VERSION ""

NS_ :

BS_:

BU_: Turbocharger OnBoardDataLogger OffBoardDiagnosticTool2 OffBoardDiagnosticTool1 FileServer ParkingBrakeController SeatControl2 FanDriveController SteeringColumnUnit CommunicationUnitRadio CommunicationUnitSatellite CommunicationUnitCellular PropulsionBatteryCharger ChassisController2 ChassisController1 EngineValveControl AuxiliaryHeater2 AuxiliaryHeater1 ClutchUnit RampControl InformationSystem1 SuspensionSystemController2 OilSensor VehicleDynamicStability ExhaustEmissionController TransmissionDisplay2 TransmissionDisplay1 ClimateControl2 WaterPumpController RearAxleSteeringController LightingOperatorControl SeatController1 IgnitionController2 IgnitionController1 TirePressureController CabController2 CabController1 PneumaticSystemController SuspensionSystemController1 HydraulicPumpController EnduranceBrakingSystem RetarderExhaustEngine2 OnBoardDiagnosticUnit HeadwayController RetarderExhaustEngine1 CabDisplay1 ManagementComputer VirtualTerminal OffVehicleGateway PowerTakeOffFront HitchControl AuxiliaryValveControl BodyController TractorTrailerBridge1 StarterSystem ElectricalSystem VehicleSecurity VehicleNavigation AerodynamicControl ElectricalChargingSystem ClimateControl1 TripRecorder InstrumentCluster SuspensionDriveAxle2 SuspensionDriveAxle1 SuspensionSteerAxle SteeringController FuelSystem CruiseControl RetarderDriveline RetarderEngine BrakesDriveAxle2 BrakesDriveAxle1 BrakesSystemController BrakesSteerAxle AxleDrive2 AxleDrive1 AxleSteering PowerTakeOff ShiftConsoleSecondary ShiftConsolePrimary Transmission2 Transmission1 Engine2 Engine1

BO_ 2348941054 TC1: 8 Vector__XXX
 SG_ TrnsShftSlctorDisplayModeSwitch : 54|2@1+ (1,0) [0|3] "" Vector__XXX
 SG_ TransMode4 : 46|2@1+ (1,0) [0|3] "" Vector__XXX
 SG_ TransMode3 : 44|2@1+ (1,0) [0|3] "" Vector__XXX
 SG_ TransMode2 : 42|2@1+ (1,0) [0|3] "" Vector__XXX
 SG_ TransMode1 : 40|2@1+ (1,0) [0|3] "" Vector__XXX
 SG_ DisengageDiffLockRqCentralRear : 36|2@1+ (1,0) [0|3] "" Vector__XXX
 SG_ DisengageDiffLockRqCentralFront : 34|2@1+ (1,0) [0|3] "" Vector__XXX
 SG_ DisengageDiffLockRqCentral : 32|2@1+ (1,0) [0|3] "" Vector__XXX
 SG_ DisengageDiffLockRqRearAxle2 : 30|2@1+ (1,0) [0|3] "" Vector__XXX
 SG_ DisengageDiffLockRqRearAxle1 : 28|2@1+ (1,0) [0|3] "" Vector__XXX
 SG_ DisengageDiffLockRqFrontAxle2 : 26|2@1+ (1,0) [0|3] "" Vector__XXX
 SG_ DisengageDiffLockRqFrontAxle1 : 24|2@1+ (1,0) [0|3] "" Vector__XXX
 SG_ TransRqedGear : 16|8@1+ (1,-125) [-125|125] "" Vector__XXX
 SG_ RqedPercentClutchSlip : 8|8@1+ (0.4,0) [0|100] "%" Vector__XXX
 SG_ DisengageDrivelineRq : 4|2@1+ (1,0) [0|3] "" Vector__XXX
 SG_ TransGearShiftInhibitRq : 0|2@1+ (1,0) [0|3] "" Vector__XXX
 SG_ TrnsTrqConverterLockupDisableRq : 2|2@1+ (1,0) [0|3] "" Vector__XXX
 SG_ TransRqedLaunchGear : 50|4@1+ (1,0) [0|15] "" Vector__XXX
 SG_ TransReverseGearShiftInhibitRq : 6|2@1+ (1,0) [0|3] "" Vector__XXX
 SG_ TransMode8 : 62|2@1+ (1,0) [0|3] "" Vector__XXX
 SG_ TransMode7 : 60|2@1+ (1,0) [0|3] "" Vector__XXX
 SG_ TransMode6 : 58|2@1+ (1,0) [0|3] "" Vector__XXX
 SG_ TransMode5 : 56|2@1+ (1,0) [0|3] "" Vector__XXX

BO_ 2566839806 TC: 8 Vector__XXX
 SG_ EngTurboOilLevelSwitch : 30|2@1+ (1,0) [0|3] "" Vector__XXX
 SG_ EngTurbo1Speed : 8|16@1+ (4,0) [0|257020] "rpm" Vector__XXX
 SG_ EngTurboLubeOilPress1 : 0|8@1+ (4,0) [0|1000] "kPa" Vector__XXX

BO_ 2633911806 TAVG: 8 Vector__XXX
 SG_ EngTotalAverageFuelEconomy : 16|16@1+ (0.001953125,0) [0|125.5] "km/L" Vector__XXX
 SG_ EngTotalAverageFuelRate : 0|16@1+ (0.05,0) [0|3212.75] "L/h" Vector__XXX

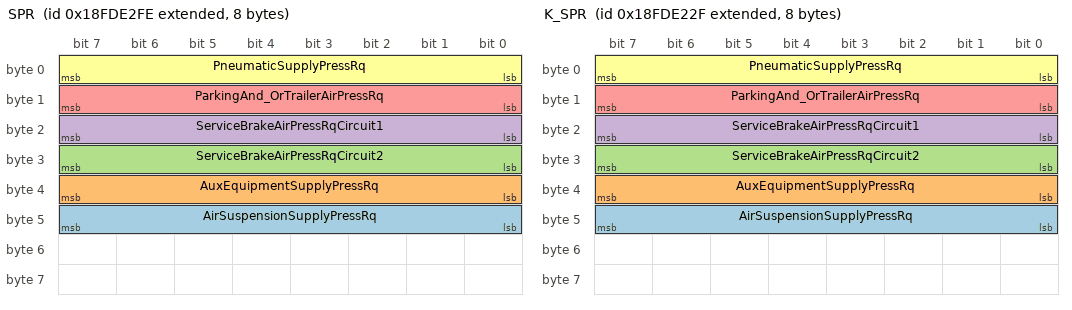
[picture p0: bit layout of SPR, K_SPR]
BO_ 2566775550 SPR: 8 Vector__XXX
 SG_ AirSuspensionSupplyPressRq : 40|8@1+ (8,0) [0|2000] "kPa" Vector__XXX
 SG_ AuxEquipmentSupplyPressRq : 32|8@1+ (8,0) [0|2000] "kPa" Vector__XXX
 SG_ ServiceBrakeAirPressRqCircuit2 : 24|8@1+ (8,0) [0|2000] "kPa" Vector__XXX
 SG_ ServiceBrakeAirPressRqCircuit1 : 16|8@1+ (8,0) [0|2000] "kPa" Vector__XXX
 SG_ ParkingAnd_OrTrailerAirPressRq : 8|8@1+ (8,0) [0|2000] "kPa" Vector__XXX
 SG_ PneumaticSupplyPressRq : 0|8@1+ (8,0) [0|2000] "kPa" Vector__XXX

BO_ 2566775343 K_SPR: 8 Vector__XXX
 SG_ AirSuspensionSupplyPressRq : 40|8@1+ (8,0) [0|2000] "kPa" Vector__XXX
 SG_ AuxEquipmentSupplyPressRq : 32|8@1+ (8,0) [0|2000] "kPa" Vector__XXX
 SG_ ServiceBrakeAirPressRqCircuit2 : 24|8@1+ (8,0) [0|2000] "kPa" Vector__XXX
 SG_ ServiceBrakeAirPressRqCircuit1 : 16|8@1+ (8,0) [0|2000] "kPa" Vector__XXX
 SG_ ParkingAnd_OrTrailerAirPressRq : 8|8@1+ (8,0) [0|2000] "kPa" Vector__XXX
 SG_ PneumaticSupplyPressRq : 0|8@1+ (8,0) [0|2000] "kPa" Vector__XXX

BO_ 2566819838 SP2: 8 Vector__XXX
 SG_ EngExtlShutdownAirSupplyPress : 0|16@1+ (0.5,0) [0|32127.5] "kPa" Vector__XXX

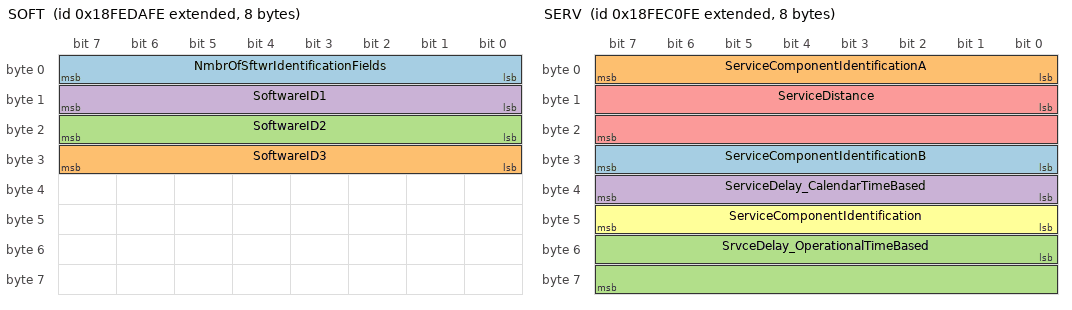
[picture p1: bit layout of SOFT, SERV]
BO_ 2566839038 SOFT: 8 Vector__XXX
 SG_ NmbrOfSftwrIdentificationFields : 0|8@1+ (1,0) [0|250] "steps" Vector__XXX
 SG_ SoftwareID3 : 24|8@1+ (1,0) [0|255] "" Vector__XXX
 SG_ SoftwareID2 : 16|8@1+ (1,0) [0|255] "" Vector__XXX
 SG_ SoftwareID1 : 8|8@1+ (1,0) [0|255] "" Vector__XXX

BO_ 2566841598 SHUTDN: 8 Vector__XXX
 SG_ EngOverspeedTest : 54|2@1+ (1,0) [0|3] "" Vector__XXX
 SG_ EngAirShutoffCmdStatus : 52|2@1+ (1,0) [0|3] "" Vector__XXX
 SG_ EngAlarmOutputCmdStatus : 50|2@1+ (1,0) [0|3] "" Vector__XXX
 SG_ EngAlarmAcknowledge : 48|2@1+ (1,0) [0|3] "" Vector__XXX
 SG_ EngProtectionSystemConfig : 46|2@1+ (1,0) [0|3] "" Vector__XXX
 SG_ EngProtectionSystemTimerState : 38|2@1+ (1,0) [0|3] "" Vector__XXX
 SG_ EngPrtectionSystemTimerOverride : 36|2@1+ (1,0) [0|3] "" Vector__XXX
 SG_ EngPrtctnSystmApprchingShutdown : 34|2@1+ (1,0) [0|3] "" Vector__XXX
 SG_ EngWaitToStartLamp : 24|2@1+ (1,0) [0|3] "" Vector__XXX
 SG_ RefrigerantHighPressSwitch : 20|2@1+ (1,0) [0|3] "" Vector__XXX
 SG_ RefrigerantLowPressSwitch : 18|2@1+ (1,0) [0|3] "" Vector__XXX
 SG_ A_CHighPressFanSwitch : 16|2@1+ (1,0) [0|3] "" Vector__XXX
 SG_ EngIdleShutdownTimerFunction : 14|2@1+ (1,0) [0|3] "" Vector__XXX
 SG_ EngIdleShutdownTimerState : 6|2@1+ (1,0) [0|3] "" Vector__XXX
 SG_ EngIdleShutdownTimerOverride : 4|2@1+ (1,0) [0|3] "" Vector__XXX
 SG_ EngIdleShutdownDriverAlertMode : 2|2@1+ (1,0) [0|3] "" Vector__XXX
 SG_ PTOShutdownHasShutdownEng : 58|2@1+ (1,0) [0|3] "" Vector__XXX
 SG_ EngPrtctnSystmHasShutdownEngine : 32|2@1+ (1,0) [0|3] "" Vector__XXX
 SG_ EngIdlShutdownHasShutdownEngine : 0|2@1+ (1,0) [0|3] "" Vector__XXX
 SG_ EngAirShutoffStatus : 56|2@1+ (1,0) [0|3] "" Vector__XXX

BO_ 2566832382 SERV: 8 Vector__XXX
 SG_ ServiceComponentIdentificationB : 24|8@1+ (1,0) [0|250] "ID" Vector__XXX
 SG_ ServiceComponentIdentificationA : 0|8@1+ (1,0) [0|250] "ID" Vector__XXX
 SG_ SrvceDelay_OperationalTimeBased : 48|16@1+ (1,-32127) [-32127|32128] "hr" Vector__XXX
 SG_ ServiceDelay_CalendarTimeBased : 32|8@1+ (1,-125) [-125|125] "weeks" Vector__XXX
 SG_ ServiceDistance : 8|16@1+ (5,-160635) [-160635|160640] "km" Vector__XXX
 SG_ ServiceComponentIdentification : 40|8@1+ (1,0) [0|250] "ID" Vector__XXX

BO_ 2633928446 S2: 8 Vector__XXX
 SG_ TimeSinceLastService : 8|16@1+ (1,-32127) [-32127|32128] "hr" Vector__XXX
 SG_ ServiceComponentIdentification : 0|8@1+ (1,0) [0|250] "ID" Vector__XXX

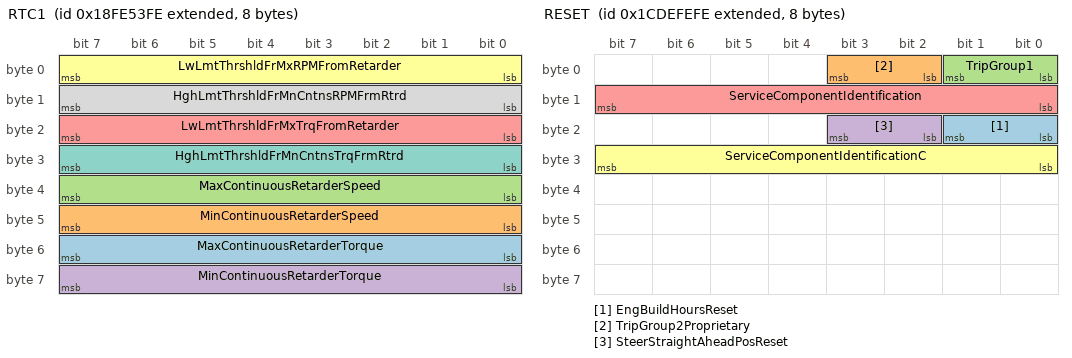
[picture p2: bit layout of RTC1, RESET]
BO_ 2566804478 RTC1: 8 Vector__XXX
 SG_ MaxContinuousRetarderTorque : 48|8@1+ (1,-125) [-125|125] "%" Vector__XXX
 SG_ MinContinuousRetarderSpeed : 40|8@1+ (32,0) [0|8000] "rpm" Vector__XXX
 SG_ MaxContinuousRetarderSpeed : 32|8@1+ (32,0) [0|8000] "rpm" Vector__XXX
 SG_ MinContinuousRetarderTorque : 56|8@1+ (1,-125) [-125|125] "%" Vector__XXX
 SG_ LwLmtThrshldFrMxTrqFromRetarder : 16|8@1+ (1,-125) [-125|125] "%" Vector__XXX
 SG_ LwLmtThrshldFrMxRPMFromRetarder : 0|8@1+ (32,0) [0|8000] "rpm" Vector__XXX
 SG_ HghLmtThrshldFrMnCntnsTrqFrmRtrd : 24|8@1+ (1,-125) [-125|125] "%" Vector__XXX
 SG_ HghLmtThrshldFrMnCntnsRPMFrmRtrd : 8|8@1+ (32,0) [0|8000] "rpm" Vector__XXX

BO_ 2566847486 RF: 8 Vector__XXX
 SG_ DrvlneRetarderOverheatIndicator : 16|2@1+ (1,0) [0|3] "" Vector__XXX
 SG_ HydRetarderOilTemp : 8|8@1+ (1,-40) [-40|210] "deg C" Vector__XXX
 SG_ HydRetarderPress : 0|8@1+ (16,0) [0|4000] "kPa" Vector__XXX

BO_ 2566847248 K_RF: 8 Vector__XXX
 SG_ DrvlneRetarderOverheatIndicator : 16|2@1+ (1,0) [0|3] "" Vector__XXX
 SG_ HydRetarderOilTemp : 8|8@1+ (1,-40) [-40|210] "deg C" Vector__XXX
 SG_ HydRetarderPress : 0|8@1+ (16,0) [0|4000] "kPa" Vector__XXX

BO_ 2631859966 RESET: 8 Vector__XXX
 SG_ EngBuildHoursReset : 16|2@1+ (1,0) [0|3] "" Vector__XXX
 SG_ TripGroup2Proprietary : 2|2@1+ (1,0) [0|3] "" Vector__XXX
 SG_ TripGroup1 : 0|2@1+ (1,0) [0|3] "" Vector__XXX
 SG_ SteerStraightAheadPosReset : 18|2@1+ (1,0) [0|3] "" Vector__XXX
 SG_ ServiceComponentIdentification : 8|8@1+ (1,0) [0|250] "ID" Vector__XXX
 SG_ ServiceComponentIdentificationC : 24|8@1+ (1,0) [0|250] "ID" Vector__XXX

BO_ 2566840830 RC: 19 Vector__XXX
 SG_ PercentTorqueAtPeakTorquePoint5 : 144|8@1+ (1,-125) [-125|125] "%" Vector__XXX
 SG_ ReferenceRetarderTorque : 128|16@1+ (1,0) [0|64255] "Nm" Vector__XXX
 SG_ RetarderSpeedAtPeakTorquePoint5 : 112|16@1+ (0.125,0) [0|8031.875] "rpm" Vector__XXX
 SG_ PercentTorqueAtPoint4 : 104|8@1+ (1,-125) [-125|125] "%" Vector__XXX
 SG_ RetarderSpeedAtPoint4 : 88|16@1+ (0.125,0) [0|8031.875] "rpm" Vector__XXX
 SG_ PercentTorqueAtPoint3 : 80|8@1+ (1,-125) [-125|125] "%" Vector__XXX
 SG_ RetarderSpeedAtPoint3 : 64|16@1+ (0.125,0) [0|8031.875] "rpm" Vector__XXX
 SG_ PercentTorqueAtMaxSpeedPoint2 : 56|8@1+ (1,-125) [-125|125] "%" Vector__XXX
 SG_ MaxRetarderSpeedPoint2 : 40|16@1+ (0.125,0) [0|8031.875] "rpm" Vector__XXX
 SG_ PercentTorqueAtIdlePoint1 : 32|8@1+ (1,-125) [-125|125] "%" Vector__XXX
 SG_ RetarderSpeedAtIdlePoint1 : 16|16@1+ (0.125,0) [0|8031.875] "rpm" Vector__XXX
 SG_ RetarderCtrlMethod : 8|8@1+ (1,0) [0|250] "steps" Vector__XXX
 SG_ RetarderLocation : 4|4@1+ (1,0) [0|15] "" Vector__XXX
 SG_ RetarderType : 0|4@1+ (1,0) [0|15] "" Vector__XXX

BO_ 2633930238 RBI: 8 Vector__XXX
 SG_ EngOperationTimeSinceRebuild : 0|32@1+ (1,0) [0|4211081215] "s" Vector__XXX

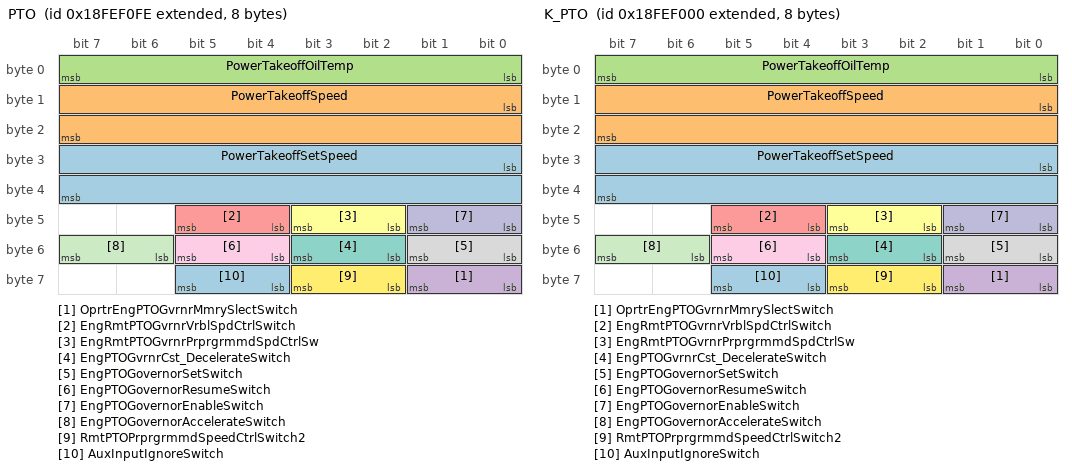
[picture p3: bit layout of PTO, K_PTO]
BO_ 2566844670 PTO: 8 Vector__XXX
 SG_ PowerTakeoffSetSpeed : 24|16@1+ (0.125,0) [0|8031.875] "rpm" Vector__XXX
 SG_ PowerTakeoffSpeed : 8|16@1+ (0.125,0) [0|8031.875] "rpm" Vector__XXX
 SG_ PowerTakeoffOilTemp : 0|8@1+ (1,-40) [-40|210] "deg C" Vector__XXX
 SG_ OprtrEngPTOGvrnrMmrySlectSwitch : 56|2@1+ (1,0) [0|3] "" Vector__XXX
 SG_ EngRmtPTOGvrnrVrblSpdCtrlSwitch : 44|2@1+ (1,0) [0|3] "" Vector__XXX
 SG_ EngRmtPTOGvrnrPrprgrmmdSpdCtrlSw : 42|2@1+ (1,0) [0|3] "" Vector__XXX
 SG_ EngPTOGvrnrCst_DecelerateSwitch : 50|2@1+ (1,0) [0|3] "" Vector__XXX
 SG_ EngPTOGovernorSetSwitch : 48|2@1+ (1,0) [0|3] "" Vector__XXX
 SG_ EngPTOGovernorResumeSwitch : 52|2@1+ (1,0) [0|3] "" Vector__XXX
 SG_ EngPTOGovernorEnableSwitch : 40|2@1+ (1,0) [0|3] "" Vector__XXX
 SG_ EngPTOGovernorAccelerateSwitch : 54|2@1+ (1,0) [0|3] "" Vector__XXX
 SG_ RmtPTOPrprgrmmdSpeedCtrlSwitch2 : 58|2@1+ (1,0) [0|3] "" Vector__XXX
 SG_ AuxInputIgnoreSwitch : 60|2@1+ (1,0) [0|3] "" Vector__XXX

BO_ 2566844416 K_PTO: 8 Vector__XXX
 SG_ PowerTakeoffSetSpeed : 24|16@1+ (0.125,0) [0|8031.875] "rpm" Vector__XXX
 SG_ PowerTakeoffSpeed : 8|16@1+ (0.125,0) [0|8031.875] "rpm" Vector__XXX
 SG_ PowerTakeoffOilTemp : 0|8@1+ (1,-40) [-40|210] "deg C" Vector__XXX
 SG_ OprtrEngPTOGvrnrMmrySlectSwitch : 56|2@1+ (1,0) [0|3] "" Vector__XXX
 SG_ EngRmtPTOGvrnrVrblSpdCtrlSwitch : 44|2@1+ (1,0) [0|3] "" Vector__XXX
 SG_ EngRmtPTOGvrnrPrprgrmmdSpdCtrlSw : 42|2@1+ (1,0) [0|3] "" Vector__XXX
 SG_ EngPTOGvrnrCst_DecelerateSwitch : 50|2@1+ (1,0) [0|3] "" Vector__XXX
 SG_ EngPTOGovernorSetSwitch : 48|2@1+ (1,0) [0|3] "" Vector__XXX
 SG_ EngPTOGovernorResumeSwitch : 52|2@1+ (1,0) [0|3] "" Vector__XXX
 SG_ EngPTOGovernorEnableSwitch : 40|2@1+ (1,0) [0|3] "" Vector__XXX
 SG_ EngPTOGovernorAccelerateSwitch : 54|2@1+ (1,0) [0|3] "" Vector__XXX
 SG_ RmtPTOPrprgrmmdSpeedCtrlSwitch2 : 58|2@1+ (1,0) [0|3] "" Vector__XXX
 SG_ AuxInputIgnoreSwitch : 60|2@1+ (1,0) [0|3] "" Vector__XXX

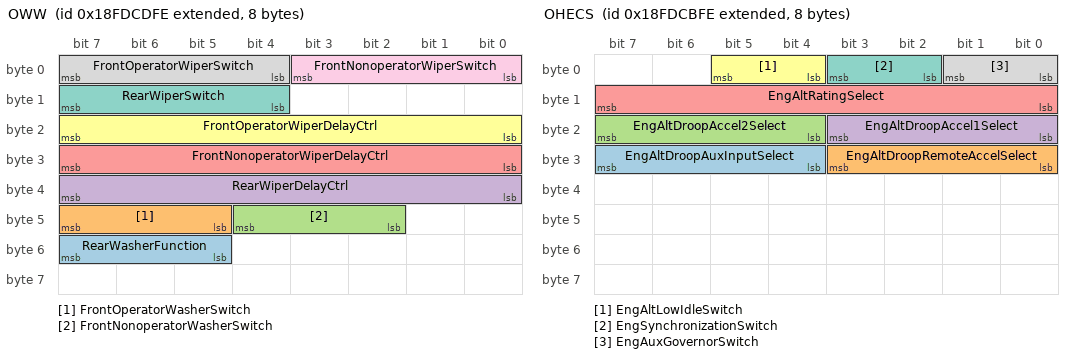
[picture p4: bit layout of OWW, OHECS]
BO_ 2566770174 OWW: 8 Vector__XXX
 SG_ RearWasherFunction : 53|3@1+ (1,0) [0|7] "" Vector__XXX
 SG_ FrontOperatorWasherSwitch : 45|3@1+ (1,0) [0|7] "" Vector__XXX
 SG_ FrontNonoperatorWasherSwitch : 42|3@1+ (1,0) [0|7] "" Vector__XXX
 SG_ RearWiperDelayCtrl : 32|8@1+ (0.4,0) [0|100] "%" Vector__XXX
 SG_ FrontNonoperatorWiperDelayCtrl : 24|8@1+ (0.4,0) [0|100] "%" Vector__XXX
 SG_ FrontOperatorWiperDelayCtrl : 16|8@1+ (0.4,0) [0|100] "%" Vector__XXX
 SG_ RearWiperSwitch : 12|4@1+ (1,0) [0|15] "" Vector__XXX
 SG_ FrontOperatorWiperSwitch : 4|4@1+ (1,0) [0|15] "" Vector__XXX
 SG_ FrontNonoperatorWiperSwitch : 0|4@1+ (1,0) [0|15] "" Vector__XXX

BO_ 2566769662 OHECS: 8 Vector__XXX
 SG_ EngAltDroopAuxInputSelect : 28|4@1+ (1,0) [0|15] "" Vector__XXX
 SG_ EngAltDroopRemoteAccelSelect : 24|4@1+ (1,0) [0|15] "" Vector__XXX
 SG_ EngAltDroopAccel2Select : 20|4@1+ (1,0) [0|15] "" Vector__XXX
 SG_ EngAltDroopAccel1Select : 16|4@1+ (1,0) [0|15] "" Vector__XXX
 SG_ EngAltRatingSelect : 8|8@1+ (1,0) [0|255] "" Vector__XXX
 SG_ EngAltLowIdleSwitch : 4|2@1+ (1,0) [0|3] "" Vector__XXX
 SG_ EngSynchronizationSwitch : 2|2@1+ (1,0) [0|3] "" Vector__XXX
 SG_ EngAuxGovernorSwitch : 0|2@1+ (1,0) [0|3] "" Vector__XXX

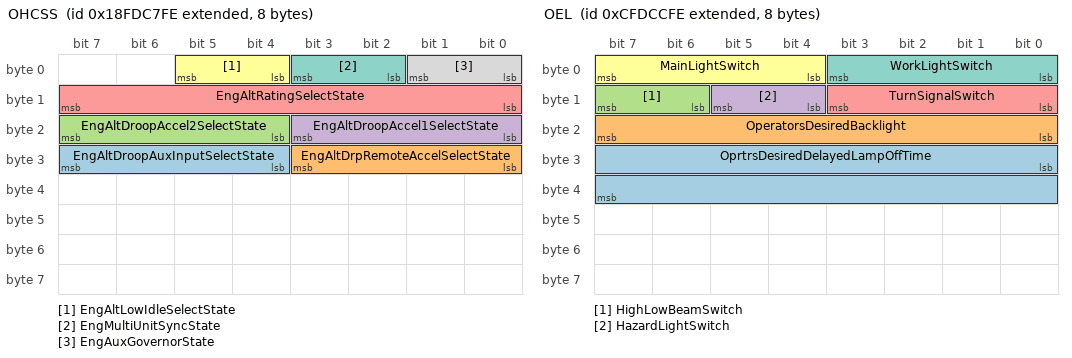
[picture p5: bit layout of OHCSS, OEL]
BO_ 2566768638 OHCSS: 8 Vector__XXX
 SG_ EngAltDroopAuxInputSelectState : 28|4@1+ (1,0) [0|15] "" Vector__XXX
 SG_ EngAltDrpRemoteAccelSelectState : 24|4@1+ (1,0) [0|15] "" Vector__XXX
 SG_ EngAltDroopAccel2SelectState : 20|4@1+ (1,0) [0|15] "" Vector__XXX
 SG_ EngAltDroopAccel1SelectState : 16|4@1+ (1,0) [0|15] "" Vector__XXX
 SG_ EngAltRatingSelectState : 8|8@1+ (1,0) [0|255] "" Vector__XXX
 SG_ EngAltLowIdleSelectState : 4|2@1+ (1,0) [0|3] "" Vector__XXX
 SG_ EngMultiUnitSyncState : 2|2@1+ (1,0) [0|3] "" Vector__XXX
 SG_ EngAuxGovernorState : 0|2@1+ (1,0) [0|3] "" Vector__XXX

BO_ 2365443326 OEL: 8 Vector__XXX
 SG_ OprtrsDesiredDelayedLampOffTime : 24|16@1+ (1,0) [0|64255] "s" Vector__XXX
 SG_ OperatorsDesiredBacklight : 16|8@1+ (0.4,0) [0|100] "%" Vector__XXX
 SG_ HighLowBeamSwitch : 14|2@1+ (1,0) [0|3] "" Vector__XXX
 SG_ HazardLightSwitch : 12|2@1+ (1,0) [0|3] "" Vector__XXX
 SG_ TurnSignalSwitch : 8|4@1+ (1,0) [0|15] "" Vector__XXX
 SG_ MainLightSwitch : 4|4@1+ (1,0) [0|15] "" Vector__XXX
 SG_ WorkLightSwitch : 0|4@1+ (1,0) [0|15] "" Vector__XXX

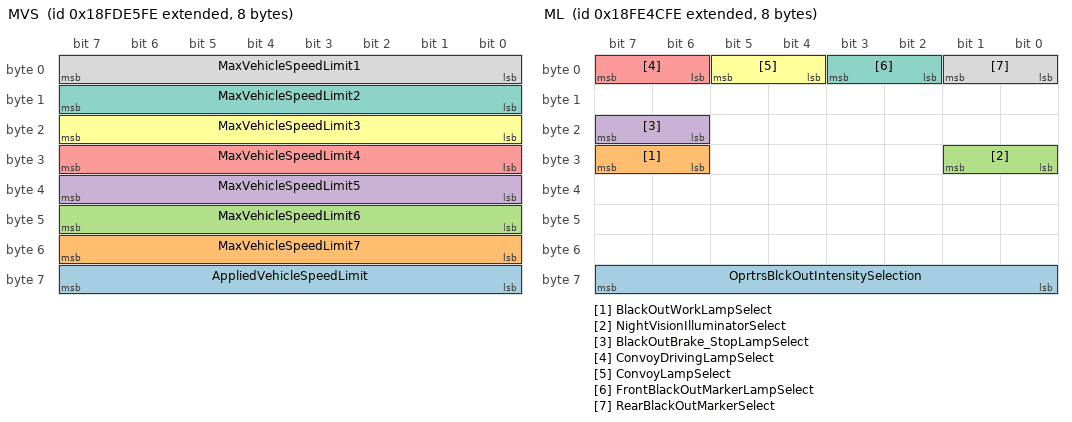
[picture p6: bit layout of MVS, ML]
BO_ 2566776318 MVS: 8 Vector__XXX
 SG_ AppliedVehicleSpeedLimit : 56|8@1+ (1,0) [0|250] "km/h" Vector__XXX
 SG_ MaxVehicleSpeedLimit7 : 48|8@1+ (1,0) [0|250] "km/h" Vector__XXX
 SG_ MaxVehicleSpeedLimit6 : 40|8@1+ (1,0) [0|250] "km/h" Vector__XXX
 SG_ MaxVehicleSpeedLimit5 : 32|8@1+ (1,0) [0|250] "km/h" Vector__XXX
 SG_ MaxVehicleSpeedLimit4 : 24|8@1+ (1,0) [0|250] "km/h" Vector__XXX
 SG_ MaxVehicleSpeedLimit3 : 16|8@1+ (1,0) [0|250] "km/h" Vector__XXX
 SG_ MaxVehicleSpeedLimit2 : 8|8@1+ (1,0) [0|250] "km/h" Vector__XXX
 SG_ MaxVehicleSpeedLimit1 : 0|8@1+ (1,0) [0|250] "km/h" Vector__XXX

BO_ 2566802686 ML: 8 Vector__XXX
 SG_ OprtrsBlckOutIntensitySelection : 56|8@1+ (0.4,0) [0|100] "%" Vector__XXX
 SG_ BlackOutWorkLampSelect : 30|2@1+ (1,0) [0|3] "" Vector__XXX
 SG_ NightVisionIlluminatorSelect : 24|2@1+ (1,0) [0|3] "" Vector__XXX
 SG_ BlackOutBrake_StopLampSelect : 22|2@1+ (1,0) [0|3] "" Vector__XXX
 SG_ ConvoyDrivingLampSelect : 6|2@1+ (1,0) [0|3] "" Vector__XXX
 SG_ ConvoyLampSelect : 4|2@1+ (1,0) [0|3] "" Vector__XXX
 SG_ FrontBlackOutMarkerLampSelect : 2|2@1+ (1,0) [0|3] "" Vector__XXX
 SG_ RearBlackOutMarkerSelect : 0|2@1+ (1,0) [0|3] "" Vector__XXX

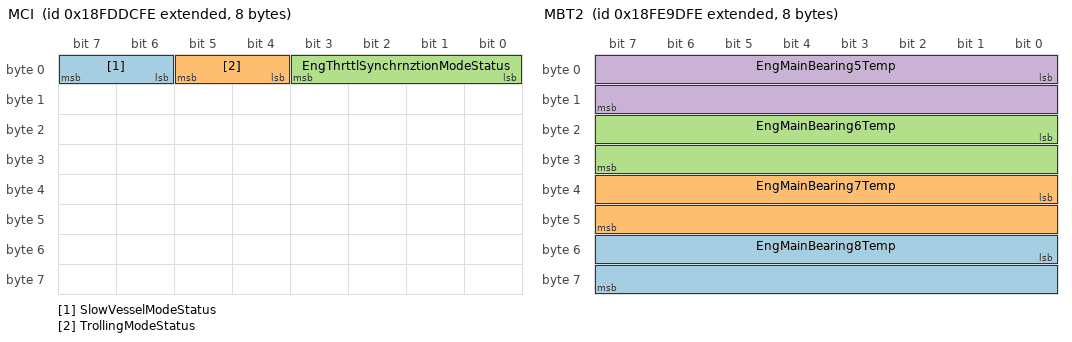
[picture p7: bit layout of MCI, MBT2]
BO_ 2566774014 MCI: 8 Vector__XXX
 SG_ SlowVesselModeStatus : 6|2@1+ (1,0) [0|3] "" Vector__XXX
 SG_ TrollingModeStatus : 4|2@1+ (1,0) [0|3] "" Vector__XXX
 SG_ EngThrttlSynchrnztionModeStatus : 0|4@1+ (1,0) [0|15] "" Vector__XXX

BO_ 2566823166 MBT3: 8 Vector__XXX
 SG_ EngMainBearing11Temp : 32|16@1+ (0.03125,-273) [-273|1734.96875] "deg C" Vector__XXX
 SG_ EngMainBearing10Temp : 16|16@1+ (0.03125,-273) [-273|1734.96875] "deg C" Vector__XXX
 SG_ EngMainBearing9Temp : 0|16@1+ (0.03125,-273) [-273|1734.96875] "deg C" Vector__XXX

BO_ 2566823422 MBT2: 8 Vector__XXX
 SG_ EngMainBearing8Temp : 48|16@1+ (0.03125,-273) [-273|1734.96875] "deg C" Vector__XXX
 SG_ EngMainBearing7Temp : 32|16@1+ (0.03125,-273) [-273|1734.96875] "deg C" Vector__XXX
 SG_ EngMainBearing6Temp : 16|16@1+ (0.03125,-273) [-273|1734.96875] "deg C" Vector__XXX
 SG_ EngMainBearing5Temp : 0|16@1+ (0.03125,-273) [-273|1734.96875] "deg C" Vector__XXX

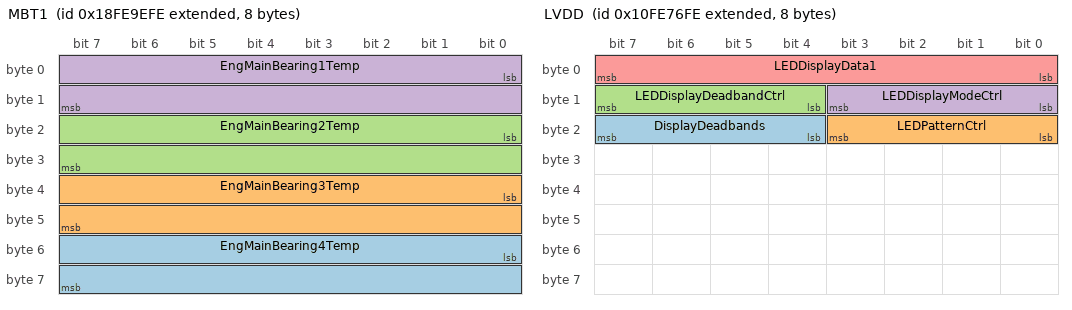
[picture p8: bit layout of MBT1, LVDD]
BO_ 2566823678 MBT1: 8 Vector__XXX
 SG_ EngMainBearing4Temp : 48|16@1+ (0.03125,-273) [-273|1734.96875] "deg C" Vector__XXX
 SG_ EngMainBearing3Temp : 32|16@1+ (0.03125,-273) [-273|1734.96875] "deg C" Vector__XXX
 SG_ EngMainBearing2Temp : 16|16@1+ (0.03125,-273) [-273|1734.96875] "deg C" Vector__XXX
 SG_ EngMainBearing1Temp : 0|16@1+ (0.03125,-273) [-273|1734.96875] "deg C" Vector__XXX

BO_ 2432595710 LVDD: 8 Vector__XXX
 SG_ DisplayDeadbands : 20|4@1+ (1,0) [0|15] "" Vector__XXX
 SG_ LEDPatternCtrl : 16|4@1+ (1,0) [0|15] "" Vector__XXX
 SG_ LEDDisplayDeadbandCtrl : 12|4@1+ (1,0) [0|15] "" Vector__XXX
 SG_ LEDDisplayModeCtrl : 8|4@1+ (1,0) [0|15] "" Vector__XXX
 SG_ LEDDisplayData1 : 0|8@1+ (1,0) [0|255] "" Vector__XXX

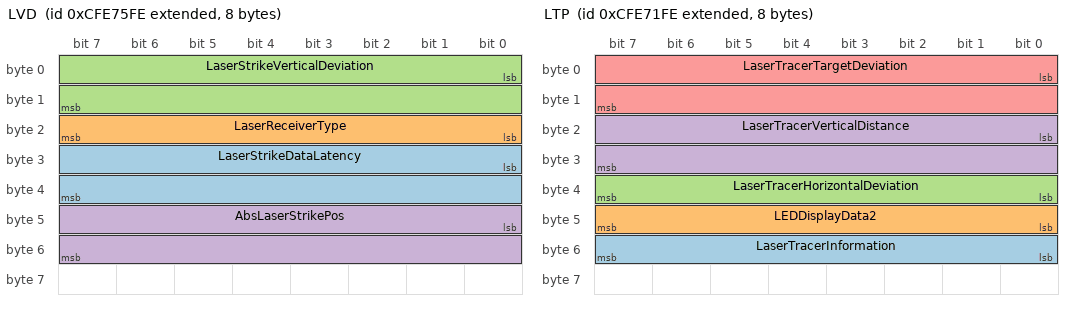
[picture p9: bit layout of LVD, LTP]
BO_ 2365486590 LVD: 8 Vector__XXX
 SG_ LaserStrikeDataLatency : 24|16@1+ (51.2,0) [0|3.289856] "s" Vector__XXX
 SG_ LaserReceiverType : 16|8@1+ (1,0) [0|250] "" Vector__XXX
 SG_ LaserStrikeVerticalDeviation : 0|16@1+ (0.1,-3200) [-3200|3225.5] "mm" Vector__XXX
 SG_ AbsLaserStrikePos : 40|16@1+ (0.1,0) [0|6425.5] "mm" Vector__XXX

BO_ 2365485566 LTP: 8 Vector__XXX
 SG_ LaserTracerInformation : 48|8@1+ (1,0) [0|255] "" Vector__XXX
 SG_ LEDDisplayData2 : 40|8@1+ (1,0) [0|255] "" Vector__XXX
 SG_ LaserTracerHorizontalDeviation : 32|8@1+ (1,0) [0|250] "%" Vector__XXX
 SG_ LaserTracerVerticalDistance : 16|16@1+ (0.1,0) [0|6425.5] "mm" Vector__XXX
 SG_ LaserTracerTargetDeviation : 0|16@1+ (0.1,-3200) [-3200|3225.5] "mm" Vector__XXX

BO_ 2633939454 LTFI: 22 Vector__XXX
 SG_ TripCruiseFuelUsed : 128|32@1+ (0.5,0) [0|2105540607.5] "L" Vector__XXX
 SG_ TripVehicleIdleFuelUsed : 96|32@1+ (0.5,0) [0|2105540607.5] "L" Vector__XXX
 SG_ TripDriveFuelUsed : 0|32@1+ (0.5,0) [0|2105540607.5] "L" Vector__XXX
 SG_ TrpPTOGovernorNonmovingFuelUsed : 64|32@1+ (0.5,0) [0|2105540607.5] "L" Vector__XXX
 SG_ TripPTOGovernorMovingFuelUsed : 32|32@1+ (0.5,0) [0|2105540607.5] "L" Vector__XXX
 SG_ TripDriveFuelEconomy : 160|16@1+ (0.001953125,0) [0|125.5] "km/L" Vector__XXX

BO_ 2365486334 LSP: 8 Vector__XXX
 SG_ BldHeightSetPointHighResolution : 16|32@1+ (100,-209.7152) [-209.7152|211.3929215] "m" Vector__XXX
 SG_ ModifyLevelingSystemSetPoint : 0|16@1+ (0.1,-3200) [-3200|3225.5] "mm" Vector__XXX

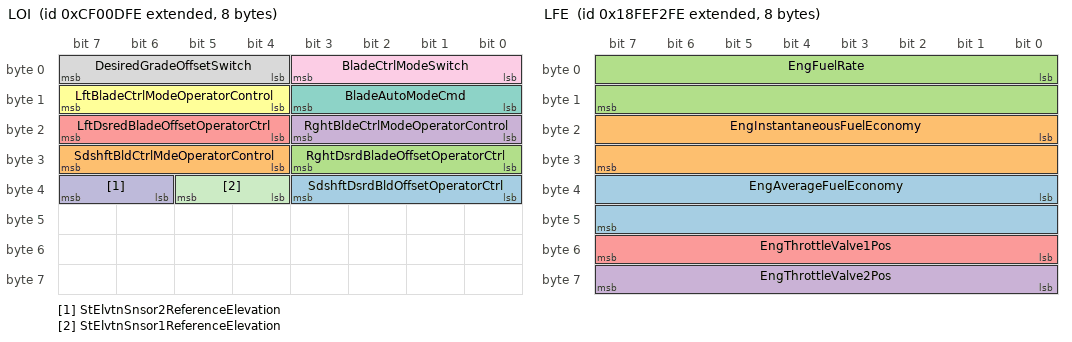
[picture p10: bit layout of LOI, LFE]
BO_ 2364542462 LOI: 8 Vector__XXX
 SG_ SdshftDsrdBldOffsetOperatorCtrl : 32|4@1+ (1,0) [0|15] "" Vector__XXX
 SG_ SdshftBldCtrlMdeOperatorControl : 28|4@1+ (1,0) [0|15] "" Vector__XXX
 SG_ RghtDsrdBladeOffsetOperatorCtrl : 24|4@1+ (1,0) [0|15] "" Vector__XXX
 SG_ RghtBldeCtrlModeOperatorControl : 16|4@1+ (1,0) [0|15] "" Vector__XXX
 SG_ LftDsredBladeOffsetOperatorCtrl : 20|4@1+ (1,0) [0|15] "" Vector__XXX
 SG_ LftBladeCtrlModeOperatorControl : 12|4@1+ (1,0) [0|15] "" Vector__XXX
 SG_ BladeAutoModeCmd : 8|4@1+ (1,0) [0|15] "" Vector__XXX
 SG_ DesiredGradeOffsetSwitch : 4|4@1+ (1,0) [0|15] "" Vector__XXX
 SG_ BladeCtrlModeSwitch : 0|4@1+ (1,0) [0|15] "" Vector__XXX
 SG_ StElvtnSnsor2ReferenceElevation : 38|2@1+ (1,0) [0|3] "" Vector__XXX
 SG_ StElvtnSnsor1ReferenceElevation : 36|2@1+ (1,0) [0|3] "" Vector__XXX

BO_ 2365486078 LMP: 8 Vector__XXX
 SG_ MastPos : 0|16@1+ (0.1,-3200) [-3200|3225.5] "mm" Vector__XXX

BO_ 2633937918 LFI: 8 Vector__XXX
 SG_ TotalEngPTOGovernorFuelUsed : 0|32@1+ (0.5,0) [0|2105540607.5] "L" Vector__XXX
 SG_ TripAverageFuelRate : 32|16@1+ (0.05,0) [0|3212.75] "L/h" Vector__XXX
 SG_ FlexibleFuelPercentage : 48|10@1+ (0.1,0) [0|102] "%" Vector__XXX

BO_ 2566845182 LFE: 8 Vector__XXX
 SG_ EngAverageFuelEconomy : 32|16@1+ (0.001953125,0) [0|125.5] "km/L" Vector__XXX
 SG_ EngInstantaneousFuelEconomy : 16|16@1+ (0.001953125,0) [0|125.5] "km/L" Vector__XXX
 SG_ EngFuelRate : 0|16@1+ (0.05,0) [0|3212.75] "L/h" Vector__XXX
 SG_ EngThrottleValve2Pos : 56|8@1+ (0.4,0) [0|100] "%" Vector__XXX
 SG_ EngThrottleValve1Pos : 48|8@1+ (0.4,0) [0|100] "%" Vector__XXX

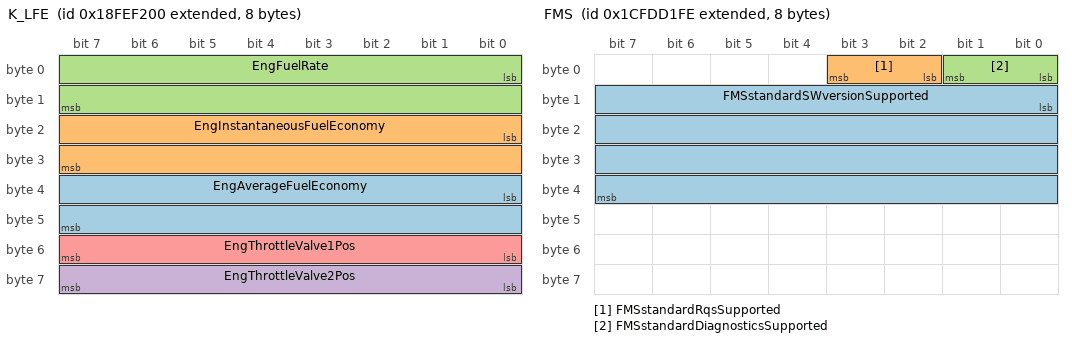
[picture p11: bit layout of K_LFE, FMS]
BO_ 2566844928 K_LFE: 8 Vector__XXX
 SG_ EngAverageFuelEconomy : 32|16@1+ (0.001953125,0) [0|125.5] "km/L" Vector__XXX
 SG_ EngInstantaneousFuelEconomy : 16|16@1+ (0.001953125,0) [0|125.5] "km/L" Vector__XXX
 SG_ EngFuelRate : 0|16@1+ (0.05,0) [0|3212.75] "L/h" Vector__XXX
 SG_ EngThrottleValve2Pos : 56|8@1+ (0.4,0) [0|100] "%" Vector__XXX
 SG_ EngThrottleValve1Pos : 48|8@1+ (0.4,0) [0|100] "%" Vector__XXX

BO_ 2566842878 LFC: 8 Vector__XXX
 SG_ EngTotalFuelUsed : 32|32@1+ (0.5,0) [0|2105540607.5] "L" Vector__XXX
 SG_ EngTripFuel : 0|32@1+ (0.5,0) [0|2105540607.5] "L" Vector__XXX

BO_ 2633883646 FWD: 8 Vector__XXX
 SG_ FrontWheelDriveActuatorStatus : 0|2@1+ (1,0) [0|3] "" Vector__XXX

BO_ 2633880062 FMS: 8 Vector__XXX
 SG_ FMSstandardSWversionSupported : 8|32@1+ (1,0) [0|255] "per" Vector__XXX
 SG_ FMSstandardRqsSupported : 2|2@1+ (1,0) [0|3] "" Vector__XXX
 SG_ FMSstandardDiagnosticsSupported : 0|2@1+ (1,0) [0|3] "" Vector__XXX

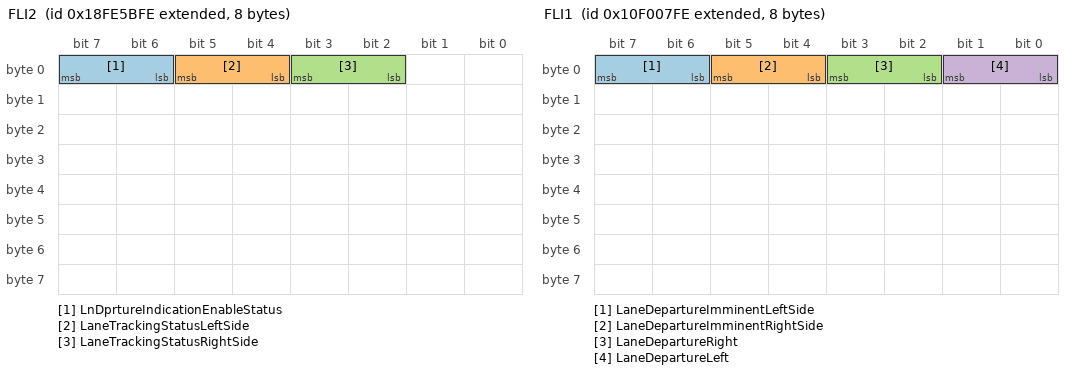
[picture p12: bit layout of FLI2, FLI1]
BO_ 2566806526 FLI2: 8 Vector__XXX
 SG_ LnDprtureIndicationEnableStatus : 6|2@1+ (1,0) [0|3] "" Vector__XXX
 SG_ LaneTrackingStatusLeftSide : 4|2@1+ (1,0) [0|3] "" Vector__XXX
 SG_ LaneTrackingStatusRightSide : 2|2@1+ (1,0) [0|3] "" Vector__XXX

BO_ 2431649790 FLI1: 8 Vector__XXX
 SG_ LaneDepartureImminentLeftSide : 6|2@1+ (1,0) [0|3] "" Vector__XXX
 SG_ LaneDepartureImminentRightSide : 4|2@1+ (1,0) [0|3] "" Vector__XXX
 SG_ LaneDepartureRight : 2|2@1+ (1,0) [0|3] "" Vector__XXX
 SG_ LaneDepartureLeft : 0|2@1+ (1,0) [0|3] "" Vector__XXX

BO_ 2633929214 FL: 8 Vector__XXX
 SG_ EngFuelLeakage2 : 2|2@1+ (1,0) [0|3] "" Vector__XXX
 SG_ EngFuelLeakage1 : 0|2@1+ (1,0) [0|3] "" Vector__XXX

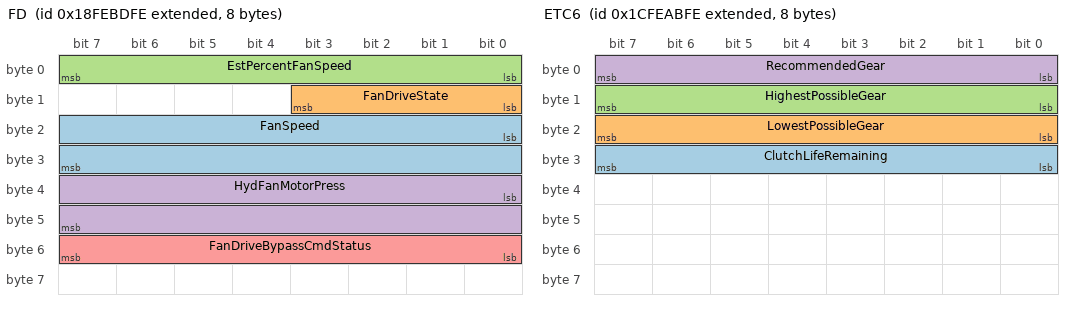
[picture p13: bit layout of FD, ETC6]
BO_ 2566831614 FD: 8 Vector__XXX
 SG_ FanSpeed : 16|16@1+ (0.125,0) [0|8031.875] "rpm" Vector__XXX
 SG_ FanDriveState : 8|4@1+ (1,0) [0|15] "" Vector__XXX
 SG_ EstPercentFanSpeed : 0|8@1+ (0.4,0) [0|100] "%" Vector__XXX
 SG_ HydFanMotorPress : 32|16@1+ (0.5,0) [0|32127.5] "kPa" Vector__XXX
 SG_ FanDriveBypassCmdStatus : 48|8@1+ (0.4,0) [0|100] "%" Vector__XXX

BO_ 2566820094 ETH: 33 Vector__XXX
 SG_ EngTorqueLimit6AxleInput : 248|16@1+ (2,0) [0|128510] "Nm" Vector__XXX
 SG_ EngTorqueLimit5Switch : 232|16@1+ (1,0) [0|64255] "Nm" Vector__XXX
 SG_ EngTorqueLimit4Trans : 216|16@1+ (1,0) [0|64255] "Nm" Vector__XXX
 SG_ EngTorqueLimit3Trans : 200|16@1+ (1,0) [0|64255] "Nm" Vector__XXX
 SG_ TransGearRatio3 : 184|16@1+ (0.01,0) [0|642.55] "" Vector__XXX
 SG_ EngTorqueLimit2Trans : 168|16@1+ (1,0) [0|64255] "Nm" Vector__XXX
 SG_ TransGearRatio2 : 152|16@1+ (0.01,0) [0|642.55] "" Vector__XXX
 SG_ EngTorqueLimit1Trans : 136|16@1+ (1,0) [0|64255] "Nm" Vector__XXX
 SG_ TransGearRatio1 : 120|16@1+ (0.01,0) [0|642.55] "" Vector__XXX
 SG_ EngTorqueLimitFeature : 114|3@1+ (1,0) [0|7] "" Vector__XXX
 SG_ TorqueLimitingFeatureStatus : 112|2@1+ (1,0) [0|3] "" Vector__XXX
 SG_ CalibRecordDurationTime : 80|32@1+ (0.05,0) [0|210554060.75] "hr" Vector__XXX
 SG_ CalibRecordStartYear : 72|8@1+ (1,1985) [1985|2235] "years" Vector__XXX
 SG_ CalibRecordStartDay : 64|8@1+ (0.25,0) [0|62.5] "days" Vector__XXX
 SG_ CalibRecordStartMonth : 56|8@1+ (1,0) [0|250] "months" Vector__XXX
 SG_ EngPeakTorque2 : 40|16@1+ (1,0) [0|64255] "Nm" Vector__XXX
 SG_ EngPeakTorque1 : 24|16@1+ (1,0) [0|64255] "Nm" Vector__XXX
 SG_ EngPower : 8|16@1+ (0.5,0) [0|32127.5] "kW" Vector__XXX
 SG_ NumberOfEngTorqueHistoryRecords : 0|8@1+ (1,0) [0|250] "records" Vector__XXX

BO_ 2364542206 ETC8: 8 Vector__XXX
 SG_ TransClutch_ConverterInputSpeed : 16|16@1+ (0.125,0) [0|8031.875] "rpm" Vector__XXX
 SG_ TransTorqueConverterRatio : 0|16@1+ (0.001,0) [0|64.255] "" Vector__XXX

BO_ 2566802174 ETC7: 8 Vector__XXX
 SG_ TrnsRvrseGearShiftInhibitStatus : 40|2@1+ (1,0) [0|3] "" Vector__XXX
 SG_ TrnsCrrntRangeDisplayBlankState : 0|2@1+ (1,0) [0|3] "" Vector__XXX
 SG_ TransWarningIndicator : 42|2@1+ (1,0) [0|3] "" Vector__XXX
 SG_ TransMode8Indicator : 38|2@1+ (1,0) [0|3] "" Vector__XXX
 SG_ TransMode7Indicator : 36|2@1+ (1,0) [0|3] "" Vector__XXX
 SG_ TransMode6Indicator : 34|2@1+ (1,0) [0|3] "" Vector__XXX
 SG_ TransMode5Indicator : 32|2@1+ (1,0) [0|3] "" Vector__XXX
 SG_ TransRqedGearFeedback : 24|8@1+ (1,-125) [-125|125] "" Vector__XXX
 SG_ TransMode1Indicator : 22|2@1+ (1,0) [0|3] "" Vector__XXX
 SG_ TransMode2Indicator : 20|2@1+ (1,0) [0|3] "" Vector__XXX
 SG_ TransMode3Indicator : 18|2@1+ (1,0) [0|3] "" Vector__XXX
 SG_ TransMode4Indicator : 16|2@1+ (1,0) [0|3] "" Vector__XXX
 SG_ TransShiftInhibitIndicator : 14|2@1+ (1,0) [0|3] "" Vector__XXX
 SG_ TransEngCrankEnable : 12|2@1+ (1,0) [0|3] "" Vector__XXX
 SG_ ActiveShiftConsoleIndicator : 10|2@1+ (1,0) [0|3] "" Vector__XXX
 SG_ TransReadyForBrakeRelease : 8|2@1+ (1,0) [0|3] "" Vector__XXX
 SG_ TransRqedRangeDisplayFlashState : 6|2@1+ (1,0) [0|3] "" Vector__XXX
 SG_ TransRqedRangeDisplayBlankState : 4|2@1+ (1,0) [0|3] "" Vector__XXX
 SG_ TransServiceIndicator : 2|2@1+ (1,0) [0|3] "" Vector__XXX

BO_ 2633935870 ETC6: 8 Vector__XXX
 SG_ ClutchLifeRemaining : 24|8@1+ (0.4,0) [0|100] "%" Vector__XXX
 SG_ LowestPossibleGear : 16|8@1+ (1,-125) [-125|125] "" Vector__XXX
 SG_ HighestPossibleGear : 8|8@1+ (1,-125) [-125|125] "" Vector__XXX
 SG_ RecommendedGear : 0|8@1+ (1,-125) [-125|125] "" Vector__XXX

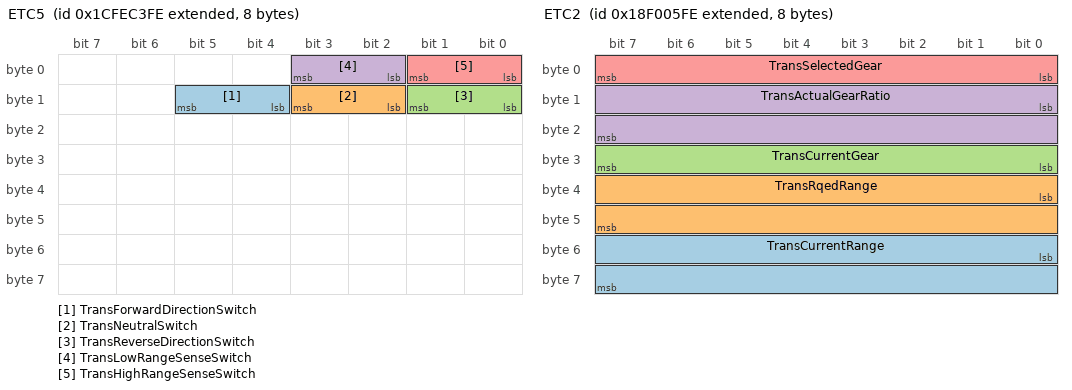
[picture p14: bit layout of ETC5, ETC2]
BO_ 2633942014 ETC5: 8 Vector__XXX
 SG_ TransForwardDirectionSwitch : 12|2@1+ (1,0) [0|3] "" Vector__XXX
 SG_ TransNeutralSwitch : 10|2@1+ (1,0) [0|3] "" Vector__XXX
 SG_ TransReverseDirectionSwitch : 8|2@1+ (1,0) [0|3] "" Vector__XXX
 SG_ TransLowRangeSenseSwitch : 2|2@1+ (1,0) [0|3] "" Vector__XXX
 SG_ TransHighRangeSenseSwitch : 0|2@1+ (1,0) [0|3] "" Vector__XXX

BO_ 2633942526 ETC4: 8 Vector__XXX
 SG_ TransSynchronizerBrakeValue : 8|8@1+ (0.4,0) [0|100] "%" Vector__XXX
 SG_ TransSynchronizerClutchValue : 0|8@1+ (0.4,0) [0|100] "%" Vector__XXX

BO_ 2633943038 ETC3: 8 Vector__XXX
 SG_ TransInertiaBrakeActuator : 46|2@1+ (1,0) [0|3] "" Vector__XXX
 SG_ TransDefuelActuator : 44|2@1+ (1,0) [0|3] "" Vector__XXX
 SG_ TransLockupClutchActuator : 42|2@1+ (1,0) [0|3] "" Vector__XXX
 SG_ TransClutchActuator : 40|2@1+ (1,0) [0|3] "" Vector__XXX
 SG_ TransSplitterIndirectActuator : 38|2@1+ (1,0) [0|3] "" Vector__XXX
 SG_ TransSplitterDirectActuator : 36|2@1+ (1,0) [0|3] "" Vector__XXX
 SG_ TransRangeLowActuator : 34|2@1+ (1,0) [0|3] "" Vector__XXX
 SG_ TransRangeHighActuator : 32|2@1+ (1,0) [0|3] "" Vector__XXX
 SG_ TransShiftFingerGearActuator2 : 30|2@1+ (1,0) [0|3] "" Vector__XXX
 SG_ TransShiftFingerRailActuator2 : 28|2@1+ (1,0) [0|3] "" Vector__XXX
 SG_ TransShiftFingerGearActuator1 : 26|2@1+ (1,0) [0|3] "" Vector__XXX
 SG_ TransShiftFingerRailActuator1 : 24|2@1+ (1,0) [0|3] "" Vector__XXX
 SG_ TrnsShftFngrCenterRailIndicator : 20|2@1+ (1,0) [0|3] "" Vector__XXX
 SG_ TrnsShftFngrEngagementIndicator : 18|2@1+ (1,0) [0|3] "" Vector__XXX
 SG_ TrnsShiftFingerNeutralIndicator : 16|2@1+ (1,0) [0|3] "" Vector__XXX
 SG_ TransShiftFingerRailPos : 8|8@1+ (0.4,0) [0|100] "%" Vector__XXX
 SG_ TransShiftFingerGearPos : 0|8@1+ (0.4,0) [0|100] "%" Vector__XXX

BO_ 2565867006 ETC2: 8 Vector__XXX
 SG_ TransCurrentRange : 48|16@1+ (1,0) [0|255] "" Vector__XXX
 SG_ TransRqedRange : 32|16@1+ (1,0) [0|255] "per" Vector__XXX
 SG_ TransCurrentGear : 24|8@1+ (1,-125) [-125|125] "" Vector__XXX
 SG_ TransActualGearRatio : 8|16@1+ (0.001,0) [0|64.255] "" Vector__XXX
 SG_ TransSelectedGear : 0|8@1+ (1,-125) [-125|125] "" Vector__XXX

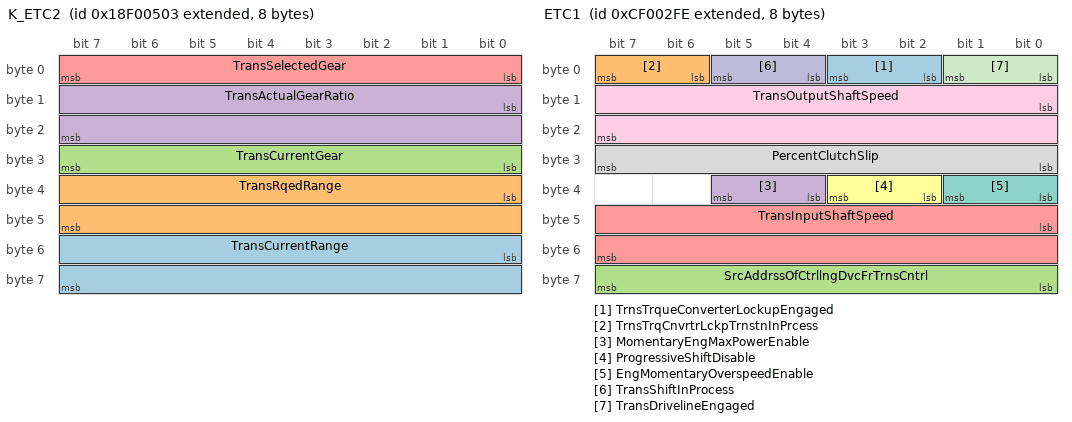
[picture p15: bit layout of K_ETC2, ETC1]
BO_ 2565866755 K_ETC2: 8 Vector__XXX
 SG_ TransCurrentRange : 48|16@1+ (1,0) [0|255] "" Vector__XXX
 SG_ TransRqedRange : 32|16@1+ (1,0) [0|255] "per" Vector__XXX
 SG_ TransCurrentGear : 24|8@1+ (1,-125) [-125|125] "" Vector__XXX
 SG_ TransActualGearRatio : 8|16@1+ (0.001,0) [0|64.255] "" Vector__XXX
 SG_ TransSelectedGear : 0|8@1+ (1,-125) [-125|125] "" Vector__XXX

BO_ 2364539646 ETC1: 8 Vector__XXX
 SG_ TrnsTrqueConverterLockupEngaged : 2|2@1+ (1,0) [0|3] "" Vector__XXX
 SG_ TrnsTrqCnvrtrLckpTrnstnInPrcess : 6|2@1+ (1,0) [0|3] "" Vector__XXX
 SG_ SrcAddrssOfCtrllngDvcFrTrnsCntrl : 56|8@1+ (1,0) [0|255] "" Vector__XXX
 SG_ MomentaryEngMaxPowerEnable : 36|2@1+ (1,0) [0|3] "" Vector__XXX
 SG_ TransInputShaftSpeed : 40|16@1+ (0.125,0) [0|8031.875] "rpm" Vector__XXX
 SG_ ProgressiveShiftDisable : 34|2@1+ (1,0) [0|3] "" Vector__XXX
 SG_ EngMomentaryOverspeedEnable : 32|2@1+ (1,0) [0|3] "" Vector__XXX
 SG_ PercentClutchSlip : 24|8@1+ (0.4,0) [0|100] "%" Vector__XXX
 SG_ TransOutputShaftSpeed : 8|16@1+ (0.125,0) [0|8031.875] "rpm" Vector__XXX
 SG_ TransShiftInProcess : 4|2@1+ (1,0) [0|3] "" Vector__XXX
 SG_ TransDrivelineEngaged : 0|2@1+ (1,0) [0|3] "" Vector__XXX

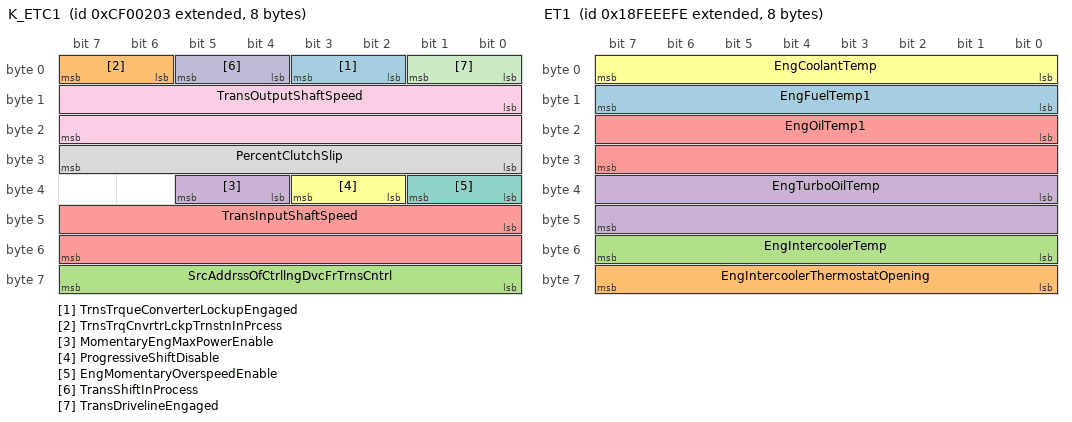
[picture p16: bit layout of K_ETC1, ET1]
BO_ 2364539395 K_ETC1: 8 Vector__XXX
 SG_ TrnsTrqueConverterLockupEngaged : 2|2@1+ (1,0) [0|3] "" Vector__XXX
 SG_ TrnsTrqCnvrtrLckpTrnstnInPrcess : 6|2@1+ (1,0) [0|3] "" Vector__XXX
 SG_ SrcAddrssOfCtrllngDvcFrTrnsCntrl : 56|8@1+ (1,0) [0|255] "" Vector__XXX
 SG_ MomentaryEngMaxPowerEnable : 36|2@1+ (1,0) [0|3] "" Vector__XXX
 SG_ TransInputShaftSpeed : 40|16@1+ (0.125,0) [0|8031.875] "rpm" Vector__XXX
 SG_ ProgressiveShiftDisable : 34|2@1+ (1,0) [0|3] "" Vector__XXX
 SG_ EngMomentaryOverspeedEnable : 32|2@1+ (1,0) [0|3] "" Vector__XXX
 SG_ PercentClutchSlip : 24|8@1+ (0.4,0) [0|100] "%" Vector__XXX
 SG_ TransOutputShaftSpeed : 8|16@1+ (0.125,0) [0|8031.875] "rpm" Vector__XXX
 SG_ TransShiftInProcess : 4|2@1+ (1,0) [0|3] "" Vector__XXX
 SG_ TransDrivelineEngaged : 0|2@1+ (1,0) [0|3] "" Vector__XXX

BO_ 2566810110 ET3: 8 Vector__XXX
 SG_ EngChargeAirCooler1OutletTemp : 48|16@1+ (0.03125,-273) [-273|1734.96875] "deg C" Vector__XXX
 SG_ EngIntkVlvActationSystemOilTemp : 32|16@1+ (0.03125,-273) [-273|1734.96875] "deg C" Vector__XXX
 SG_ EngIntakeManifold1AirTemp : 0|16@1+ (0.03125,-273) [-273|1734.96875] "deg C" Vector__XXX
 SG_ EngCoolantTempHiRes : 16|16@1+ (0.03125,-273) [-273|1734.96875] "deg C" Vector__XXX

BO_ 2566825214 ET2: 8 Vector__XXX
 SG_ EngExhstGsRcrculation1DiffPress : 32|16@1+ (0.0078125,-250) [-250|251.99] "kPa" Vector__XXX
 SG_ EngExhaustGasRecirculation1Temp : 48|16@1+ (0.03125,-273) [-273|1734.96875] "deg C" Vector__XXX
 SG_ EngECUTemp : 16|16@1+ (0.03125,-273) [-273|1734.96875] "deg C" Vector__XXX
 SG_ EngOilTemp2 : 0|16@1+ (0.03125,-273) [-273|1734.96875] "deg C" Vector__XXX

BO_ 2566844158 ET1: 8 Vector__XXX
 SG_ EngFuelTemp1 : 8|8@1+ (1,-40) [-40|210] "deg C" Vector__XXX
 SG_ EngIntercoolerThermostatOpening : 56|8@1+ (0.4,0) [0|100] "%" Vector__XXX
 SG_ EngIntercoolerTemp : 48|8@1+ (1,-40) [-40|210] "deg C" Vector__XXX
 SG_ EngTurboOilTemp : 32|16@1+ (0.03125,-273) [-273|1734.96875] "deg C" Vector__XXX
 SG_ EngOilTemp1 : 16|16@1+ (0.03125,-273) [-273|1734.96875] "deg C" Vector__XXX
 SG_ EngCoolantTemp : 0|8@1+ (0.03125,-273) [-273|-265.03125] "deg C" Vector__XXX

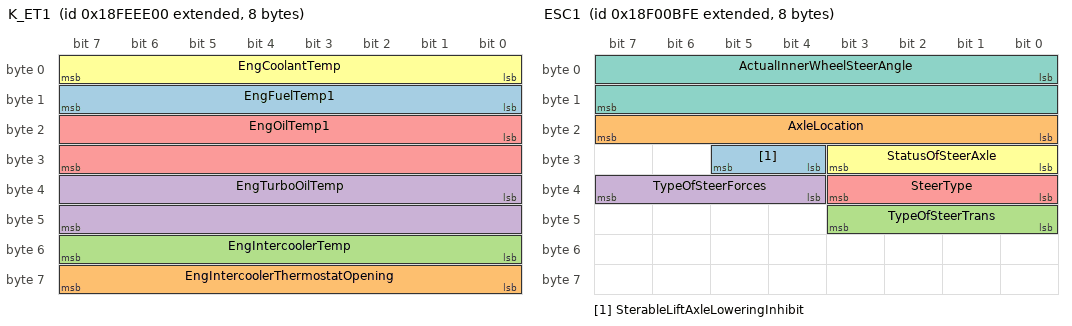
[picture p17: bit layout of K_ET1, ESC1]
BO_ 2566843904 K_ET1: 8 Vector__XXX
 SG_ EngFuelTemp1 : 8|8@1+ (1,-40) [-40|210] "deg C" Vector__XXX
 SG_ EngIntercoolerThermostatOpening : 56|8@1+ (0.4,0) [0|100] "%" Vector__XXX
 SG_ EngIntercoolerTemp : 48|8@1+ (1,-40) [-40|210] "deg C" Vector__XXX
 SG_ EngTurboOilTemp : 32|16@1+ (0.03125,-273) [-273|1734.96875] "deg C" Vector__XXX
 SG_ EngOilTemp1 : 16|16@1+ (0.03125,-273) [-273|1734.96875] "deg C" Vector__XXX
 SG_ EngCoolantTemp : 0|8@1+ (0.03125,-273) [-273|-265.03125] "deg C" Vector__XXX

BO_ 2566785022 ET: 8 Vector__XXX
 SG_ EngExhaustGasTempRightManifold : 0|16@1+ (0.03125,-273) [-273|1734.96875] "deg C" Vector__XXX
 SG_ EngExhaustGasTempLeftManifold : 16|16@1+ (0.03125,-273) [-273|1734.96875] "deg C" Vector__XXX

BO_ 2565868542 ESC1: 8 Vector__XXX
 SG_ SterableLiftAxleLoweringInhibit : 28|2@1+ (1,0) [0|3] "" Vector__XXX
 SG_ AxleLocation : 16|8@1+ (1,0) [0|255] "" Vector__XXX
 SG_ TypeOfSteerTrans : 40|4@1+ (1,0) [0|15] "" Vector__XXX
 SG_ TypeOfSteerForces : 36|4@1+ (1,0) [0|15] "" Vector__XXX
 SG_ SteerType : 32|4@1+ (1,0) [0|15] "" Vector__XXX
 SG_ StatusOfSteerAxle : 24|4@1+ (1,0) [0|15] "" Vector__XXX
 SG_ ActualInnerWheelSteerAngle : 0|16@1+ (0.00390625,-125) [-125|125] "deg" Vector__XXX

BO_ 2633941758 ERC2: 8 Vector__XXX
 SG_ TransOutputRetarder : 0|2@1+ (1,0) [0|3] "" Vector__XXX

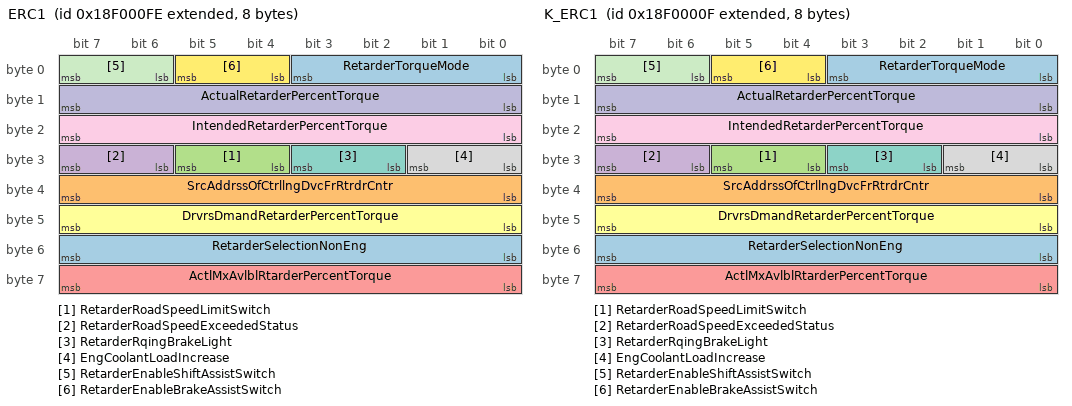
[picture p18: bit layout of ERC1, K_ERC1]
BO_ 2565865726 ERC1: 8 Vector__XXX
 SG_ RetarderSelectionNonEng : 48|8@1+ (0.4,0) [0|100] "%" Vector__XXX
 SG_ SrcAddrssOfCtrllngDvcFrRtrdrCntr : 32|8@1+ (1,0) [0|255] "" Vector__XXX
 SG_ RetarderRoadSpeedLimitSwitch : 28|2@1+ (1,0) [0|3] "" Vector__XXX
 SG_ RetarderRoadSpeedExceededStatus : 30|2@1+ (1,0) [0|3] "" Vector__XXX
 SG_ ActlMxAvlblRtarderPercentTorque : 56|8@1+ (1,-125) [-125|125] "%" Vector__XXX
 SG_ DrvrsDmandRetarderPercentTorque : 40|8@1+ (1,-125) [-125|125] "%" Vector__XXX
 SG_ RetarderRqingBrakeLight : 26|2@1+ (1,0) [0|3] "" Vector__XXX
 SG_ EngCoolantLoadIncrease : 24|2@1+ (1,0) [0|3] "" Vector__XXX
 SG_ IntendedRetarderPercentTorque : 16|8@1+ (1,-125) [-125|125] "%" Vector__XXX
 SG_ ActualRetarderPercentTorque : 8|8@1+ (1,-125) [-125|125] "%" Vector__XXX
 SG_ RetarderEnableShiftAssistSwitch : 6|2@1+ (1,0) [0|3] "" Vector__XXX
 SG_ RetarderEnableBrakeAssistSwitch : 4|2@1+ (1,0) [0|3] "" Vector__XXX
 SG_ RetarderTorqueMode : 0|4@1+ (1,0) [0|15] "" Vector__XXX

BO_ 2565865487 K_ERC1: 8 Vector__XXX
 SG_ RetarderSelectionNonEng : 48|8@1+ (0.4,0) [0|100] "%" Vector__XXX
 SG_ SrcAddrssOfCtrllngDvcFrRtrdrCntr : 32|8@1+ (1,0) [0|255] "" Vector__XXX
 SG_ RetarderRoadSpeedLimitSwitch : 28|2@1+ (1,0) [0|3] "" Vector__XXX
 SG_ RetarderRoadSpeedExceededStatus : 30|2@1+ (1,0) [0|3] "" Vector__XXX
 SG_ ActlMxAvlblRtarderPercentTorque : 56|8@1+ (1,-125) [-125|125] "%" Vector__XXX
 SG_ DrvrsDmandRetarderPercentTorque : 40|8@1+ (1,-125) [-125|125] "%" Vector__XXX
 SG_ RetarderRqingBrakeLight : 26|2@1+ (1,0) [0|3] "" Vector__XXX
 SG_ EngCoolantLoadIncrease : 24|2@1+ (1,0) [0|3] "" Vector__XXX
 SG_ IntendedRetarderPercentTorque : 16|8@1+ (1,-125) [-125|125] "%" Vector__XXX
 SG_ ActualRetarderPercentTorque : 8|8@1+ (1,-125) [-125|125] "%" Vector__XXX
 SG_ RetarderEnableShiftAssistSwitch : 6|2@1+ (1,0) [0|3] "" Vector__XXX
 SG_ RetarderEnableBrakeAssistSwitch : 4|2@1+ (1,0) [0|3] "" Vector__XXX
 SG_ RetarderTorqueMode : 0|4@1+ (1,0) [0|15] "" Vector__XXX

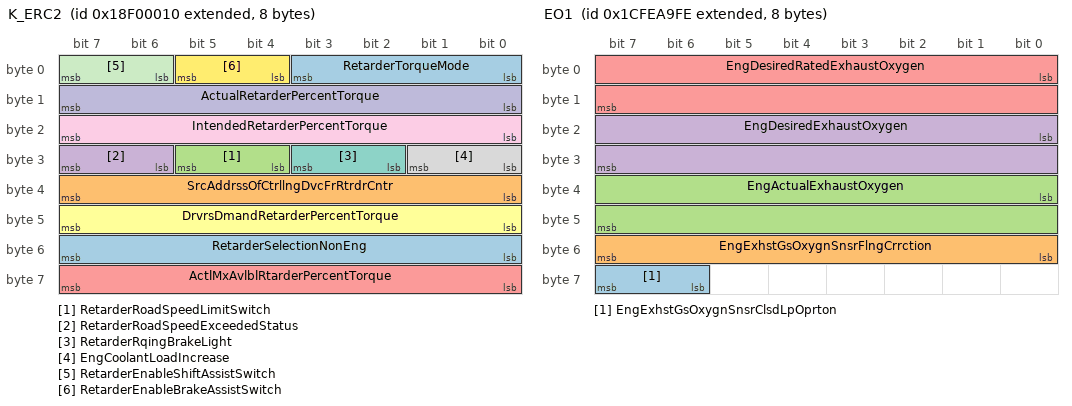
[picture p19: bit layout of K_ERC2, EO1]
BO_ 2565865488 K_ERC2: 8 Vector__XXX
 SG_ RetarderSelectionNonEng : 48|8@1+ (0.4,0) [0|100] "%" Vector__XXX
 SG_ SrcAddrssOfCtrllngDvcFrRtrdrCntr : 32|8@1+ (1,0) [0|255] "" Vector__XXX
 SG_ RetarderRoadSpeedLimitSwitch : 28|2@1+ (1,0) [0|3] "" Vector__XXX
 SG_ RetarderRoadSpeedExceededStatus : 30|2@1+ (1,0) [0|3] "" Vector__XXX
 SG_ ActlMxAvlblRtarderPercentTorque : 56|8@1+ (1,-125) [-125|125] "%" Vector__XXX
 SG_ DrvrsDmandRetarderPercentTorque : 40|8@1+ (1,-125) [-125|125] "%" Vector__XXX
 SG_ RetarderRqingBrakeLight : 26|2@1+ (1,0) [0|3] "" Vector__XXX
 SG_ EngCoolantLoadIncrease : 24|2@1+ (1,0) [0|3] "" Vector__XXX
 SG_ IntendedRetarderPercentTorque : 16|8@1+ (1,-125) [-125|125] "%" Vector__XXX
 SG_ ActualRetarderPercentTorque : 8|8@1+ (1,-125) [-125|125] "%" Vector__XXX
 SG_ RetarderEnableShiftAssistSwitch : 6|2@1+ (1,0) [0|3] "" Vector__XXX
 SG_ RetarderEnableBrakeAssistSwitch : 4|2@1+ (1,0) [0|3] "" Vector__XXX
 SG_ RetarderTorqueMode : 0|4@1+ (1,0) [0|15] "" Vector__XXX

BO_ 2633932798 EPT5: 8 Vector__XXX
 SG_ EngExhaustGasPort20Temp : 48|16@1+ (0.03125,-273) [-273|1734.96875] "deg C" Vector__XXX
 SG_ EngExhaustGasPort19Temp : 32|16@1+ (0.03125,-273) [-273|1734.96875] "deg C" Vector__XXX
 SG_ EngExhaustGasPort18Temp : 16|16@1+ (0.03125,-273) [-273|1734.96875] "deg C" Vector__XXX
 SG_ EngExhaustGasPort17Temp : 0|16@1+ (0.03125,-273) [-273|1734.96875] "deg C" Vector__XXX

BO_ 2566824190 EPT4: 8 Vector__XXX
 SG_ EngExhaustGasPort16Temp : 48|16@1+ (0.03125,-273) [-273|1734.96875] "deg C" Vector__XXX
 SG_ EngExhaustGasPort15Temp : 32|16@1+ (0.03125,-273) [-273|1734.96875] "deg C" Vector__XXX
 SG_ EngExhaustGasPort14Temp : 16|16@1+ (0.03125,-273) [-273|1734.96875] "deg C" Vector__XXX
 SG_ EngExhaustGasPort13Temp : 0|16@1+ (0.03125,-273) [-273|1734.96875] "deg C" Vector__XXX

BO_ 2633933310 EPT3: 8 Vector__XXX
 SG_ EngExhaustGasPort12Temp : 48|16@1+ (0.03125,-273) [-273|1734.96875] "deg C" Vector__XXX
 SG_ EngExhaustGasPort11Temp : 32|16@1+ (0.03125,-273) [-273|1734.96875] "deg C" Vector__XXX
 SG_ EngExhaustGasPort10Temp : 16|16@1+ (0.03125,-273) [-273|1734.96875] "deg C" Vector__XXX
 SG_ EngExhaustGasPort9Temp : 0|16@1+ (0.03125,-273) [-273|1734.96875] "deg C" Vector__XXX

BO_ 2633933566 EPT2: 8 Vector__XXX
 SG_ EngExhaustGasPort8Temp : 48|16@1+ (0.03125,-273) [-273|1734.96875] "deg C" Vector__XXX
 SG_ EngExhaustGasPort7Temp : 32|16@1+ (0.03125,-273) [-273|1734.96875] "deg C" Vector__XXX
 SG_ EngExhaustGasPort6Temp : 16|16@1+ (0.03125,-273) [-273|1734.96875] "deg C" Vector__XXX
 SG_ EngExhaustGasPort5Temp : 0|16@1+ (0.03125,-273) [-273|1734.96875] "deg C" Vector__XXX

BO_ 2633933822 EPT1: 8 Vector__XXX
 SG_ EngExhaustGasPort4Temp : 48|16@1+ (0.03125,-273) [-273|1734.96875] "deg C" Vector__XXX
 SG_ EngExhaustGasPort3Temp : 32|16@1+ (0.03125,-273) [-273|1734.96875] "deg C" Vector__XXX
 SG_ EngExhaustGasPort2Temp : 16|16@1+ (0.03125,-273) [-273|1734.96875] "deg C" Vector__XXX
 SG_ EngExhaustGasPort1Temp : 0|16@1+ (0.03125,-273) [-273|1734.96875] "deg C" Vector__XXX

BO_ 2566776062 EPD: 8 Vector__XXX
 SG_ PayloadPercentage : 0|8@1+ (1,0) [0|250] "%" Vector__XXX

BO_ 2566771454 EP: 8 Vector__XXX
 SG_ DataMemoryUsage : 16|8@1+ (0.4,0) [0|100] "%" Vector__XXX
 SG_ KeepAliveBatteryConsumption : 0|16@1+ (1,0) [0|64255] "mAhr" Vector__XXX

BO_ 2566775806 EOAC: 8 Vector__XXX
 SG_ TravelVelocityCtrlPos : 0|8@1+ (1,-125) [-125|125] "%" Vector__XXX

BO_ 2633935358 EO1: 8 Vector__XXX
 SG_ EngExhstGsOxygnSnsrClsdLpOprton : 62|2@1+ (1,0) [0|3] "" Vector__XXX
 SG_ EngExhstGsOxygnSnsrFlngCrrction : 48|8@1+ (1,-125) [-125|125] "%" Vector__XXX
 SG_ EngActualExhaustOxygen : 32|16@1+ (0.0025,0) [0|160.6375] "%" Vector__XXX
 SG_ EngDesiredExhaustOxygen : 16|16@1+ (0.0025,0) [0|160.6375] "%" Vector__XXX
 SG_ EngDesiredRatedExhaustOxygen : 0|16@1+ (0.0025,0) [0|160.6375] "%" Vector__XXX

CM_ BO_ 2348941054 "Transmission Control 1";
CM_ SG_ 2348941054 TrnsShftSlctorDisplayModeSwitch "Status of the operator's switch used to `toggle' through multiple display modes of a shift selector display.";
CM_ SG_ 2348941054 TransMode4 "Indicates whether transmission mode 4 is enabled.";
CM_ SG_ 2348941054 TransMode3 "Indicates whether transmission mode 3 is enabled.";
CM_ SG_ 2348941054 TransMode2 "Indicates whether transmission mode 2 is enabled.";
CM_ SG_ 2348941054 TransMode1 "Indicates whether transmission mode 1 is enabled.";
CM_ SG_ 2348941054 DisengageDiffLockRqCentralRear "Command signal used to disengage the various differential locks, e.";
CM_ SG_ 2348941054 DisengageDiffLockRqCentralFront "Command signal used to disengage the various differential locks, e.";
CM_ SG_ 2348941054 DisengageDiffLockRqCentral "Command signal used to disengage the various differential locks, e.";
CM_ SG_ 2348941054 DisengageDiffLockRqRearAxle2 "Command signal used to disengage the various differential locks, e.";
CM_ SG_ 2348941054 DisengageDiffLockRqRearAxle1 "Command signal used to disengage the various differential locks, e.";
CM_ SG_ 2348941054 DisengageDiffLockRqFrontAxle2 "Command signal used to disengage the various differential locks, e.";
CM_ SG_ 2348941054 DisengageDiffLockRqFrontAxle1 "Command signal used to disengage the various differential locks, e.";
CM_ SG_ 2348941054 TransRqedGear "Gear requested by the operator, ABS, or engine.";
CM_ SG_ 2348941054 RqedPercentClutchSlip "Parameter which represents the percent clutch slip requested by a device.";
CM_ SG_ 2348941054 DisengageDrivelineRq "Command signal used to simply disengage the driveline, e.";
CM_ SG_ 2348941054 TransGearShiftInhibitRq "Command signal to inhibit gear shifts.";
CM_ SG_ 2348941054 TrnsTrqConverterLockupDisableRq "Command signal to prevent torque converter lockup, which may cause problems in certain circumstances for ASR.";
CM_ SG_ 2348941054 TransRqedLaunchGear "Initial gear for the transmission to start out in when the vehicle is launched from a standing stop, as specified by the";
CM_ SG_ 2348941054 TransReverseGearShiftInhibitRq "Allows devices external to the normal transmission shift selector system to request the transmission to inhibit shifts into";
CM_ SG_ 2348941054 TransMode8 "Indicates whether transmission mode 8 is enabled.";
CM_ SG_ 2348941054 TransMode7 "Indicates whether transmission mode 7 is enabled.";
CM_ SG_ 2348941054 TransMode6 "Indicates whether transmission mode 6 is enabled.";
CM_ SG_ 2348941054 TransMode5 "Indicates whether transmission mode 5 is enabled.";
CM_ BO_ 2566839806 "Turbocharger";
CM_ SG_ 2566839806 EngTurboOilLevelSwitch "Switch signal which indicates the presence of oil at the turbocharger";
CM_ SG_ 2566839806 EngTurbo1Speed "Rotational velocity of rotor in the turbocharger.";
CM_ SG_ 2566839806 EngTurboLubeOilPress1 "Gage pressure of oil in turbocharger lubrication system.";
CM_ BO_ 2633911806 "Total Averaged Information";
CM_ SG_ 2633911806 EngTotalAverageFuelEconomy "Average fuel economy, equal to total vehicle distance divided by total fuel used, over the life of the engine";
CM_ SG_ 2633911806 EngTotalAverageFuelRate "Average fuel rate, equal to total fuel used divided by total engine hours, over the life of the engine";
CM_ BO_ 2566775550 "Supply Pressure Demand";
CM_ SG_ 2566775550 AirSuspensionSupplyPressRq "Command signal to influence the pneumatic pressure in the circuit for the electronically controlled air suspension system.";
CM_ SG_ 2566775550 AuxEquipmentSupplyPressRq "Command signal to influence the pneumatic pressure in the auxiliary circuit.";
CM_ SG_ 2566775550 ServiceBrakeAirPressRqCircuit2 "Command signal to influence the pneumatic pressure in the service brake circuit or reservoir #2.";
CM_ SG_ 2566775550 ServiceBrakeAirPressRqCircuit1 "Command signal to influence the pneumatic pressure in the service brake circuit or reservoir #1.";
CM_ SG_ 2566775550 ParkingAnd_OrTrailerAirPressRq "Command signal to influence the pneumatic pressure in the circuit or reservoir for the parking brake and/or the trailer supply.";
CM_ SG_ 2566775550 PneumaticSupplyPressRq "Command signal to influence the pneumatic pressure in the main reservoir.";
CM_ BO_ 2566775343 "Supply Pressure Demand";
CM_ SG_ 2566775343 AirSuspensionSupplyPressRq "Command signal to influence the pneumatic pressure in the circuit for the electronically controlled air suspension system.";
CM_ SG_ 2566775343 AuxEquipmentSupplyPressRq "Command signal to influence the pneumatic pressure in the auxiliary circuit.";
CM_ SG_ 2566775343 ServiceBrakeAirPressRqCircuit2 "Command signal to influence the pneumatic pressure in the service brake circuit or reservoir #2.";
CM_ SG_ 2566775343 ServiceBrakeAirPressRqCircuit1 "Command signal to influence the pneumatic pressure in the service brake circuit or reservoir #1.";
CM_ SG_ 2566775343 ParkingAnd_OrTrailerAirPressRq "Command signal to influence the pneumatic pressure in the circuit or reservoir for the parking brake and/or the trailer supply.";
CM_ SG_ 2566775343 PneumaticSupplyPressRq "Command signal to influence the pneumatic pressure in the main reservoir.";
CM_ BO_ 2566819838 "Supply Pressure 2";
CM_ SG_ 2566819838 EngExtlShutdownAirSupplyPress "Pressure of the air used to shut off the fuel supply to the engine.";
CM_ BO_ 2566839038 "Software Identification";
CM_ SG_ 2566839038 NmbrOfSftwrIdentificationFields "Number of software identification designators represented in the software identification parameter group.";
CM_ SG_ 2566839038 SoftwareID3 "Software ID";
CM_ SG_ 2566839038 SoftwareID2 "Software ID";
CM_ SG_ 2566839038 SoftwareID1 "Software ID";
CM_ BO_ 2566841598 "Shutdown";
CM_ SG_ 2566841598 EngOverspeedTest "The engine overspeed test signal as measured by the reporting ECM.";
CM_ SG_ 2566841598 EngAirShutoffCmdStatus "State signal which indicates when the Air Shutoff driver output is being driven.";
CM_ SG_ 2566841598 EngAlarmOutputCmdStatus "State signal which indicates when the Alarm driver output is being driven.";
CM_ SG_ 2566841598 EngAlarmAcknowledge "The Engine Alarm Acknowledge Input signal as measured by the reporting ECM.";
CM_ SG_ 2566841598 EngProtectionSystemConfig "Parameter which indicates the configuration of the engine shutdown system.";
CM_ SG_ 2566841598 EngProtectionSystemTimerState "Status signal which indicates the current mode of the engine protection system timer system.";
CM_ SG_ 2566841598 EngPrtectionSystemTimerOverride "Status signal which indicates the status of the override feature of the engine protection system timer.";
CM_ SG_ 2566841598 EngPrtctnSystmApprchingShutdown "Status signal which indicates that engine shutdown is imminent.";
CM_ SG_ 2566841598 EngWaitToStartLamp "Lamp signal which indicates that the engine is too cold to start and the operator should wait until the signal becomes";
CM_ SG_ 2566841598 RefrigerantHighPressSwitch "Switch signal which indicates the position of the high pressure switch in the coolant circuit of an air conditioning system.";
CM_ SG_ 2566841598 RefrigerantLowPressSwitch "Switch signal which indicates the position of the low pressure switch in the coolant circuit of an air conditioning system.";
CM_ SG_ 2566841598 A_CHighPressFanSwitch "Switch signal which indicates that the pressure in the coolant circuit of an air conditioning system is high and the fan may";
CM_ SG_ 2566841598 EngIdleShutdownTimerFunction "Parameter which indicates the configuration of the idle shutdown timer system.";
CM_ SG_ 2566841598 EngIdleShutdownTimerState "Status signal which indicates the current mode of operation of the idle shutdown timer system.";
CM_ SG_ 2566841598 EngIdleShutdownTimerOverride "Status signal which indicates the status of the override feature of the idle shutdown timer system.";
CM_ SG_ 2566841598 EngIdleShutdownDriverAlertMode "Status signal which indicates the status of the driver alert mode of the idle shutdown timer system.";
CM_ SG_ 2566841598 PTOShutdownHasShutdownEng "Status signal which identifies whether or not the engine has been shutdown by the PTO shutdown system.";
CM_ SG_ 2566841598 EngPrtctnSystmHasShutdownEngine "Status signal which indicates whether or not the engine protection system has shutdown the engine.";
CM_ SG_ 2566841598 EngIdlShutdownHasShutdownEngine "Status signal which identifies whether or not the engine has been shutdown by the idle shutdown timer system.";
CM_ SG_ 2566841598 EngAirShutoffStatus "State signal which indicates the actual measured position of the Air Shutoff.";
CM_ BO_ 2566832382 "Service Information";
CM_ SG_ 2566832382 ServiceComponentIdentificationB "Identification of component needing service.";
CM_ SG_ 2566832382 ServiceComponentIdentificationA "Identification of component needing service.";
CM_ SG_ 2566832382 SrvceDelay_OperationalTimeBased "The time in vehicle operational time until the next vehicle service inspection is required.";
CM_ SG_ 2566832382 ServiceDelay_CalendarTimeBased "The time in weeks until the next vehicle service inspection is required.";
CM_ SG_ 2566832382 ServiceDistance "The distance which can be traveled by the vehicle before the next service inspection is required.";
CM_ SG_ 2566832382 ServiceComponentIdentification "Identification of component needing service.";
CM_ BO_ 2633928446 "Service 2";
CM_ SG_ 2633928446 TimeSinceLastService "The vehicle operation time since the last service was performed.";
CM_ SG_ 2633928446 ServiceComponentIdentification "Identification of component needing service.";
CM_ BO_ 2566804478 "Retarder Continuous Torque & Speed Limit";
CM_ SG_ 2566804478 MaxContinuousRetarderTorque "Applied limit for maximum continuous retarder torque.";
CM_ SG_ 2566804478 MinContinuousRetarderSpeed "Applied limit for minimum continuous retarder RPM";
CM_ SG_ 2566804478 MaxContinuousRetarderSpeed "Applied limit for maximum continuous retarder RPM";
CM_ SG_ 2566804478 MinContinuousRetarderTorque "Applied limit for minimum continuous retarder torque";
CM_ SG_ 2566804478 LwLmtThrshldFrMxTrqFromRetarder "Minimum allowable value for maximum continuous retarder torque.";
CM_ SG_ 2566804478 LwLmtThrshldFrMxRPMFromRetarder "Minimum allowable value for maximum continuous retarder speed";
CM_ SG_ 2566804478 HghLmtThrshldFrMnCntnsTrqFrmRtrd "Maximum allowable value for minimum continuous retarder torque.";
CM_ SG_ 2566804478 HghLmtThrshldFrMnCntnsRPMFrmRtrd "Maximum allowable value for minimum continuous retarder speed";
CM_ BO_ 2566847486 "Retarder fluids";
CM_ SG_ 2566847486 DrvlneRetarderOverheatIndicator "Signal from the driveline retarder indicating that its fluid temperature is above normal acceptable limits, and as a result,";
CM_ SG_ 2566847486 HydRetarderOilTemp "Temperature of oil found in a hydraulic retarder.";
CM_ SG_ 2566847486 HydRetarderPress "Gage pressure of oil in hydraulic retarder system.";
CM_ BO_ 2566847248 "Retarder fluids";
CM_ SG_ 2566847248 DrvlneRetarderOverheatIndicator "Signal from the driveline retarder indicating that its fluid temperature is above normal acceptable limits, and as a result,";
CM_ SG_ 2566847248 HydRetarderOilTemp "Temperature of oil found in a hydraulic retarder.";
CM_ SG_ 2566847248 HydRetarderPress "Gage pressure of oil in hydraulic retarder system.";
CM_ BO_ 2631859966 "Reset";
CM_ SG_ 2631859966 EngBuildHoursReset "Command signal used to reset the engine rebuild hours.";
CM_ SG_ 2631859966 TripGroup2Proprietary "Command signal used to reset proprietary parameters associated with a trip but not defined within this document.";
CM_ SG_ 2631859966 TripGroup1 "Command signal used to reset the PGNs and parameters as defined in Table SPN988_A.";
CM_ SG_ 2631859966 SteerStraightAheadPosReset "Used to reset the straight ahead position for a steering sensor in the steering column or a steering controller's straight";
CM_ SG_ 2631859966 ServiceComponentIdentification "Identification of component needing service.";
CM_ SG_ 2631859966 ServiceComponentIdentificationC "Identification of component needing service.";
CM_ BO_ 2566840830 "Retarder Configuration";
CM_ SG_ 2566840830 PercentTorqueAtPeakTorquePoint5 "The torque limit that indicates the available retarder torque which can be provided by the retarder at point 5 of the retarder";
CM_ SG_ 2566840830 ReferenceRetarderTorque "This parameter is the 100% reference value for all defined indicated retarder torque parameters.";
CM_ SG_ 2566840830 RetarderSpeedAtPeakTorquePoint5 "Please reference PGN 65249";
CM_ SG_ 2566840830 PercentTorqueAtPoint4 "The torque limit that indicates the available retarder torque which can be provided by the retarder at points 3 and 4 of the";
CM_ SG_ 2566840830 RetarderSpeedAtPoint4 "Retarder speed of point 4 of the engine retarder torque map.";
CM_ SG_ 2566840830 PercentTorqueAtPoint3 "The torque limit that indicates the available retarder torque which can be provided by the retarder at points 3 and 4 of the";
CM_ SG_ 2566840830 RetarderSpeedAtPoint3 "Retarder speed of point 3 of the engine retarder torque map.";
CM_ SG_ 2566840830 PercentTorqueAtMaxSpeedPoint2 "The torque limit that indicates the available retarder torque which can be provided by the retarder at its maximum speed.";
CM_ SG_ 2566840830 MaxRetarderSpeedPoint2 "Maximum speed of retarder (Please reference PGN 65249).";
CM_ SG_ 2566840830 PercentTorqueAtIdlePoint1 "The torque limit that indicates the available retarder torque which can be provided by the retarder at idle speed.";
CM_ SG_ 2566840830 RetarderSpeedAtIdlePoint1 "Please reference PGN 65249";
CM_ SG_ 2566840830 RetarderCtrlMethod "This parameter identifies the number of steps used by the retarder.";
CM_ SG_ 2566840830 RetarderLocation "This parameter defines whether the [torque/speed curve] defined by the retarder configuration message (PGN 65249) is";
CM_ SG_ 2566840830 RetarderType "A vehicle retarder is a supplementary device to the wheel brakes for the driver to better control the vehicle.";
CM_ BO_ 2633930238 "Rebuild Information";
CM_ SG_ 2633930238 EngOperationTimeSinceRebuild "The time in engine operation since the last engine rebuild.";
CM_ BO_ 2566844670 "Power Takeoff Information";
CM_ SG_ 2566844670 PowerTakeoffSetSpeed "Rotational velocity selected by operator for device used to transmit engine power to auxiliary equipment.";
CM_ SG_ 2566844670 PowerTakeoffSpeed "Rotational velocity of device used to transmit engine power to auxiliary equipment.";
CM_ SG_ 2566844670 PowerTakeoffOilTemp "Temperature of lubricant in device used to transmit engine power to auxiliary equipment.";
CM_ SG_ 2566844670 OprtrEngPTOGvrnrMmrySlectSwitch "Measured state of the operator's engine PTO governor memory select switch.";
CM_ SG_ 2566844670 EngRmtPTOGvrnrVrblSpdCtrlSwitch "Switch signal which indicates that the remote PTO governor toggle switch is in the enabled (ON) position.";
CM_ SG_ 2566844670 EngRmtPTOGvrnrPrprgrmmdSpdCtrlSw "Switch signal which indicates that the remote PTO governor toggle switch is in the enabled (ON) position.";
CM_ SG_ 2566844670 EngPTOGvrnrCst_DecelerateSwitch "Switch signal of the PTO control activator which indicates that the activator is in the position to \"coast\" decelerate\" the PTO";
CM_ SG_ 2566844670 EngPTOGovernorSetSwitch "Switch signal of the PTO control activator which indicates that the activator is in the position to \"set\" the engine PTO";
CM_ SG_ 2566844670 EngPTOGovernorResumeSwitch "Switch signal of the PTO control activator which indicates that the activator is in the position to \"resume\" a previously";
CM_ SG_ 2566844670 EngPTOGovernorEnableSwitch "Switch signal which indicates that the PTO governor toggle switch is in the enabled (ON) position and therefore it is";
CM_ SG_ 2566844670 EngPTOGovernorAccelerateSwitch "Switch signal of the PTO control activator which indicates that the activator is in the position to \"accelerate\" the PTO";
CM_ SG_ 2566844670 RmtPTOPrprgrmmdSpeedCtrlSwitch2 "Switch signal which indicates that the remote PTO toggle switch #2 is in the enabled (ON) position.";
CM_ SG_ 2566844670 AuxInputIgnoreSwitch "Switch signal which overrides other switch input's ability to kick out of an engine's operating condition.";
CM_ BO_ 2566844416 "Power Takeoff Information";
CM_ SG_ 2566844416 PowerTakeoffSetSpeed "Rotational velocity selected by operator for device used to transmit engine power to auxiliary equipment.";
CM_ SG_ 2566844416 PowerTakeoffSpeed "Rotational velocity of device used to transmit engine power to auxiliary equipment.";
CM_ SG_ 2566844416 PowerTakeoffOilTemp "Temperature of lubricant in device used to transmit engine power to auxiliary equipment.";
CM_ SG_ 2566844416 OprtrEngPTOGvrnrMmrySlectSwitch "Measured state of the operator's engine PTO governor memory select switch.";
CM_ SG_ 2566844416 EngRmtPTOGvrnrVrblSpdCtrlSwitch "Switch signal which indicates that the remote PTO governor toggle switch is in the enabled (ON) position.";
CM_ SG_ 2566844416 EngRmtPTOGvrnrPrprgrmmdSpdCtrlSw "Switch signal which indicates that the remote PTO governor toggle switch is in the enabled (ON) position.";
CM_ SG_ 2566844416 EngPTOGvrnrCst_DecelerateSwitch "Switch signal of the PTO control activator which indicates that the activator is in the position to \"coast\" decelerate\" the PTO";
CM_ SG_ 2566844416 EngPTOGovernorSetSwitch "Switch signal of the PTO control activator which indicates that the activator is in the position to \"set\" the engine PTO";
CM_ SG_ 2566844416 EngPTOGovernorResumeSwitch "Switch signal of the PTO control activator which indicates that the activator is in the position to \"resume\" a previously";
CM_ SG_ 2566844416 EngPTOGovernorEnableSwitch "Switch signal which indicates that the PTO governor toggle switch is in the enabled (ON) position and therefore it is";
CM_ SG_ 2566844416 EngPTOGovernorAccelerateSwitch "Switch signal of the PTO control activator which indicates that the activator is in the position to \"accelerate\" the PTO";
CM_ SG_ 2566844416 RmtPTOPrprgrmmdSpeedCtrlSwitch2 "Switch signal which indicates that the remote PTO toggle switch #2 is in the enabled (ON) position.";
CM_ SG_ 2566844416 AuxInputIgnoreSwitch "Switch signal which overrides other switch input's ability to kick out of an engine's operating condition.";
CM_ BO_ 2566770174 "Operator Wiper and Washer Controls Message";
CM_ SG_ 2566770174 RearWasherFunction "State of operation selected by operator switch for the rear washer.";
CM_ SG_ 2566770174 FrontOperatorWasherSwitch "State of operation selected by operator switch for the washer in front of the operator position.";
CM_ SG_ 2566770174 FrontNonoperatorWasherSwitch "State of operation selected by operator switch for the front washer not in front of the operator position.";
CM_ SG_ 2566770174 RearWiperDelayCtrl "Time between cycles of the rear wiper (i.";
CM_ SG_ 2566770174 FrontNonoperatorWiperDelayCtrl "Time between cycles of the front non-operator side wiper (i.";
CM_ SG_ 2566770174 FrontOperatorWiperDelayCtrl "Time between cycles of the front operator side wiper (i.";
CM_ SG_ 2566770174 RearWiperSwitch "State of operation selected by operator switch for the rear wiper.";
CM_ SG_ 2566770174 FrontOperatorWiperSwitch "State of operation selected by operator switch for the Wiper in front of the operator position.";
CM_ SG_ 2566770174 FrontNonoperatorWiperSwitch "State of operation selected by operator switch for the front wiper not in front of the operator position.";
CM_ BO_ 2566769662 "Off-Highway Engine Control Selection";
CM_ SG_ 2566769662 EngAltDroopAuxInputSelect "In some off-highway applications it may be desirable to have multiple droop settings available across the range of engine";
CM_ SG_ 2566769662 EngAltDroopRemoteAccelSelect "In some off-highway applications it may be desirable to have multiple droop settings available across the range of engine";
CM_ SG_ 2566769662 EngAltDroopAccel2Select "Same description as Engine Alternate Droop Accelerator 1 Select (SPN 2881) except that the selections may apply to";
CM_ SG_ 2566769662 EngAltDroopAccel1Select "In some off-highway applications it may be desirable to have multiple droop settings available across the range of engine";
CM_ SG_ 2566769662 EngAltRatingSelect "In some off-highway applications it may be desirable to have multiple engine ratings available for selection by the operator.";
CM_ SG_ 2566769662 EngAltLowIdleSwitch "Operator switch which selects between two low idle speeds, default and alternate.";
CM_ SG_ 2566769662 EngSynchronizationSwitch "This is the On/Off operation of the Multiple Unit Synchronization functionality.";
CM_ SG_ 2566769662 EngAuxGovernorSwitch "This is the On/Off operation of the Auxiliary Governor feature switch.";
CM_ BO_ 2566768638 "Off-Highway Engine Control Selection States";
CM_ SG_ 2566768638 EngAltDroopAuxInputSelectState "In some off-highway applications it may be desirable to have multiple droop settings available across the range of engine";
CM_ SG_ 2566768638 EngAltDrpRemoteAccelSelectState "In some off-highway applications it may be desirable to have multiple droop settings available across the range of engine";
CM_ SG_ 2566768638 EngAltDroopAccel2SelectState "In some off-highway applications it may be desirable to have multiple droop settings available across the range of engine";
CM_ SG_ 2566768638 EngAltDroopAccel1SelectState "In some off-highway applications it may be desirable to have multiple droop settings available across the range of engine";
CM_ SG_ 2566768638 EngAltRatingSelectState "In some off-highway applications it may be desirable to have multiple engine ratings available for selection by the operator.";
CM_ SG_ 2566768638 EngAltLowIdleSelectState "In many applications, it is desirable that an alternate low idle speed setting be made available via switch input.";
CM_ SG_ 2566768638 EngMultiUnitSyncState "This feature is widely used in Industry to operate multiple engines from a single command source.";
CM_ SG_ 2566768638 EngAuxGovernorState "This is the Engine Auxiliary Governor feature.";
CM_ BO_ 2365443326 "Operators External Light Controls Message";
CM_ SG_ 2365443326 OprtrsDesiredDelayedLampOffTime "A 16 bit parameter to be associated with Delayed Off position (1000 binary) of the Main Light Switch.";
CM_ SG_ 2365443326 OperatorsDesiredBacklight "A 8 bit parameter to indicate the level of back lighting the operator has selected for displays.";
CM_ SG_ 2365443326 HighLowBeamSwitch "A 2 bit parameter to indicate the selected position of the operator's high/low beam select switch.";
CM_ SG_ 2365443326 HazardLightSwitch "A 2 bit parameter to indicate the selected position of the operator's hazard light switch.";
CM_ SG_ 2365443326 TurnSignalSwitch "A 4 bit parameter to indicate the selected position of the operator's turn signal switch.";
CM_ SG_ 2365443326 MainLightSwitch "A 4 bit parameter to indicate the selected position of the operator's main light switch.";
CM_ SG_ 2365443326 WorkLightSwitch "A 4 bit parameter to indicate the selected position of the operator's work light switch.";
CM_ BO_ 2566776318 "Maximum Vehicle Speed Limit Status";
CM_ SG_ 2566776318 AppliedVehicleSpeedLimit "The vehicle speed limit in effect.";
CM_ SG_ 2566776318 MaxVehicleSpeedLimit7 "The highest of the seven lowest vehicle speed limits";
CM_ SG_ 2566776318 MaxVehicleSpeedLimit6 "The highest of the six lowest vehicle speed limits";
CM_ SG_ 2566776318 MaxVehicleSpeedLimit5 "The highest of the five lowest vehicle speed limits";
CM_ SG_ 2566776318 MaxVehicleSpeedLimit4 "The highest of the four lowest vehicle speed limits";
CM_ SG_ 2566776318 MaxVehicleSpeedLimit3 "The highest of the three lowest vehicle speed limits";
CM_ SG_ 2566776318 MaxVehicleSpeedLimit2 "The highest of the two lowest vehicle speed limits";
CM_ SG_ 2566776318 MaxVehicleSpeedLimit1 "The lowest Maximum Vehicle Speed Limit.";
CM_ BO_ 2566802686 "Military Lighting Command";
CM_ SG_ 2566802686 OprtrsBlckOutIntensitySelection "Operators Selection of lamp intensity in black out mode.";
CM_ SG_ 2566802686 BlackOutWorkLampSelect "Black Out Work Lamp Selection";
CM_ SG_ 2566802686 NightVisionIlluminatorSelect "Night Vision Illuminator Selection";
CM_ SG_ 2566802686 BlackOutBrake_StopLampSelect "Black Out Brake/Stop Lamp Selection";
CM_ SG_ 2566802686 ConvoyDrivingLampSelect "Black Out Convoy Driving Lamp Selection";
CM_ SG_ 2566802686 ConvoyLampSelect "Black Out Convoy Lamp Selection";
CM_ SG_ 2566802686 FrontBlackOutMarkerLampSelect "Front Black Out Marker Lamp Selection";
CM_ SG_ 2566802686 RearBlackOutMarkerSelect "Rear Black Out Marker Selection";
CM_ BO_ 2566774014 "Marine Control Information";
CM_ SG_ 2566774014 SlowVesselModeStatus "The status of the Slow Vessel Mode.";
CM_ SG_ 2566774014 TrollingModeStatus "The status of the Trolling Mode.";
CM_ SG_ 2566774014 EngThrttlSynchrnztionModeStatus "The status of the Throttle Synchronization Mode.";
CM_ BO_ 2566823166 "Main Bearing Temperature 3";
CM_ SG_ 2566823166 EngMainBearing11Temp "Temperature of the main bearing which supports the crankshaft of the engine.";
CM_ SG_ 2566823166 EngMainBearing10Temp "Temperature of the main bearing which supports the crankshaft of the engine.";
CM_ SG_ 2566823166 EngMainBearing9Temp "Temperature of the main bearing which supports the crankshaft of the engine.";
CM_ BO_ 2566823422 "Main Bearing Temperature 2";
CM_ SG_ 2566823422 EngMainBearing8Temp "Temperature of the main bearing which supports the crankshaft of the engine.";
CM_ SG_ 2566823422 EngMainBearing7Temp "Temperature of the main bearing which supports the crankshaft of the engine.";
CM_ SG_ 2566823422 EngMainBearing6Temp "Temperature of the main bearing which supports the crankshaft of the engine.";
CM_ SG_ 2566823422 EngMainBearing5Temp "Temperature of the main bearing which supports the crankshaft of the engine.";
CM_ BO_ 2566823678 "Main Bearing Temperature 1";
CM_ SG_ 2566823678 EngMainBearing4Temp "Temperature of the main bearing which supports the crankshaft of the engine.";
CM_ SG_ 2566823678 EngMainBearing3Temp "Temperature of the main bearing which supports the crankshaft of the engine.";
CM_ SG_ 2566823678 EngMainBearing2Temp "Temperature of the main bearing which supports the crankshaft of the engine.";
CM_ SG_ 2566823678 EngMainBearing1Temp "Temperature of the main bearing which supports the crankshaft of the engine.";
CM_ BO_ 2432595710 "Laser Leveling System Vertical Position Display Data";
CM_ SG_ 2432595710 DisplayDeadbands "Sets Display Deadbands mode.";
CM_ SG_ 2432595710 LEDPatternCtrl "Sets LED Pattern control mode on laser leveling systems.";
CM_ SG_ 2432595710 LEDDisplayDeadbandCtrl "This parameter informs the system what the selected Display deadband will be.";
CM_ SG_ 2432595710 LEDDisplayModeCtrl "This parameter informs the system what the selected Display mode will be.";
CM_ SG_ 2432595710 LEDDisplayData1 "Informs display devices how to display the current vertical position.";
CM_ BO_ 2365486590 "Laser Leveling System Vertical Deviation";
CM_ SG_ 2365486590 LaserStrikeDataLatency "Time from laser strike to CAN message transmission.";
CM_ SG_ 2365486590 LaserReceiverType "Identifies which type of Laser Receiver transmitted the message.";
CM_ SG_ 2365486590 LaserStrikeVerticalDeviation "The calculated distance from the laser strike position to the current land leveling system reference point.";
CM_ SG_ 2365486590 AbsLaserStrikePos "Laser Strike location on the survey type laser receiver.";
CM_ BO_ 2365485566 "Laser Tracer Position";
CM_ SG_ 2365485566 LaserTracerInformation "Provides the status of the laser tracer to the operator.";
CM_ SG_ 2365485566 LEDDisplayData2 "Informs display devices how to display the current position of the laser tracer.";
CM_ SG_ 2365485566 LaserTracerHorizontalDeviation "The calculated percent deviation between the target distance and the center of the laser tracer.";
CM_ SG_ 2365485566 LaserTracerVerticalDistance "The elevation of the laser tracer sensor in a laser leveling system.";
CM_ SG_ 2365485566 LaserTracerTargetDeviation "The calculated distance for the laser target to the current laser tracer reference point.";
CM_ BO_ 2633939454 "Trip Fuel Information (Liquid)";
CM_ SG_ 2633939454 TripCruiseFuelUsed "Total fuel consumed while the engine is in the cruise hold state since the last trip reset.";
CM_ SG_ 2633939454 TripVehicleIdleFuelUsed "Total fuel consumed while neither the PTO or remote PTO governor is in the hold state, the engine speed is greater than";
CM_ SG_ 2633939454 TripDriveFuelUsed "Total fuel consumed while the engine speed is greater than zero, vehicle speed is greater than or equal to 2 km/h, and";
CM_ SG_ 2633939454 TrpPTOGovernorNonmovingFuelUsed "Total fuel consumed while either the PTO or remote PTO governors are in the hold state, the engine speed is greater";
CM_ SG_ 2633939454 TripPTOGovernorMovingFuelUsed "Total fuel consumed while either the PTO or remote PTO governors are in the hold state, the engine speed is greater";
CM_ SG_ 2633939454 TripDriveFuelEconomy "Trip drive fuel economy is equal to the distance traveled by vehicle in the drive state (engine speed greater than zero,";
CM_ BO_ 2365486334 "Modify Leveling System Control Set Point";
CM_ SG_ 2365486334 BldHeightSetPointHighResolution "High resolution for the laser guided blade set point.";
CM_ SG_ 2365486334 ModifyLevelingSystemSetPoint "Used to control and coordinate the set point for the leveling system.";
CM_ BO_ 2364542462 "Land Leveling System Operational Information";
CM_ SG_ 2364542462 SdshftDsrdBldOffsetOperatorCtrl "This parameter indicates the side-shift blade control mode operator control state the user has set for the land leveling system.";
CM_ SG_ 2364542462 SdshftBldCtrlMdeOperatorControl "This parameter indicates the side-shift offset operator control state the user has set for the land leveling system.";
CM_ SG_ 2364542462 RghtDsrdBladeOffsetOperatorCtrl "This parameter indicates the right blade offset operator control state the user has set for the land leveling system.";
CM_ SG_ 2364542462 RghtBldeCtrlModeOperatorControl "This parameter indicates the right blade control mode operator control state the user has set for the land leveling system.";
CM_ SG_ 2364542462 LftDsredBladeOffsetOperatorCtrl "This parameter indicates the left blade offset operator control state the user has set for the land leveling system.";
CM_ SG_ 2364542462 LftBladeCtrlModeOperatorControl "This parameter indicates the left blade control mode operator control state the user has set for the land leveling system.";
CM_ SG_ 2364542462 BladeAutoModeCmd "Allows other controllers to command to the primary control system what they think is the appropriate auto control mode to";
CM_ SG_ 2364542462 DesiredGradeOffsetSwitch "This parameter indicates the grade offset switch state the user has set for the land leveling system.";
CM_ SG_ 2364542462 BladeCtrlModeSwitch "This parameter indicates the blade control mode switch state the user has set for the land leveling system.";
CM_ SG_ 2364542462 StElvtnSnsor2ReferenceElevation "Command from a display or other external device (i.";
CM_ SG_ 2364542462 StElvtnSnsor1ReferenceElevation "Command from a display or other external device (i.";
CM_ BO_ 2365486078 "Laser Receiver Mast Position";
CM_ SG_ 2365486078 MastPos "Used to monitor the position of the sensor attached to the land leveling mast.";
CM_ BO_ 2633937918 "Fuel Information (Liquid)";
CM_ SG_ 2633937918 TotalEngPTOGovernorFuelUsed "Total fuel used while the PTO or remote PTO governors are in the hold state and engine speed is above zero, over the";
CM_ SG_ 2633937918 TripAverageFuelRate "Average fuel rate, equal to trip fuel divided by trip time while the engine speed is above zero, since the last trip reset.";
CM_ SG_ 2633937918 FlexibleFuelPercentage "Measured signal that indicates the percentage of alcohol in the fuel currently being used.";
CM_ BO_ 2566845182 "Fuel Economy (Liquid)";
CM_ SG_ 2566845182 EngAverageFuelEconomy "Average of instantaneous fuel economy for that segment of vehicle operation of interest.";
CM_ SG_ 2566845182 EngInstantaneousFuelEconomy "Current fuel economy at current vehicle velocity.";
CM_ SG_ 2566845182 EngFuelRate "Amount of fuel consumed by engine per unit of time.";
CM_ SG_ 2566845182 EngThrottleValve2Pos "The sensed position feedback of the valve, coming from a second electrical actuator for a second throttle plate, used to";
CM_ SG_ 2566845182 EngThrottleValve1Pos "The position of the valve used to regulate the supply of a fluid, usually air or fuel/air mixture, to an engine.";
CM_ BO_ 2566844928 "Fuel Economy (Liquid)";
CM_ SG_ 2566844928 EngAverageFuelEconomy "Average of instantaneous fuel economy for that segment of vehicle operation of interest.";
CM_ SG_ 2566844928 EngInstantaneousFuelEconomy "Current fuel economy at current vehicle velocity.";
CM_ SG_ 2566844928 EngFuelRate "Amount of fuel consumed by engine per unit of time.";
CM_ SG_ 2566844928 EngThrottleValve2Pos "The sensed position feedback of the valve, coming from a second electrical actuator for a second throttle plate, used to";
CM_ SG_ 2566844928 EngThrottleValve1Pos "The position of the valve used to regulate the supply of a fluid, usually air or fuel/air mixture, to an engine.";
CM_ BO_ 2566842878 "Fuel Consumption (Liquid)";
CM_ SG_ 2566842878 EngTotalFuelUsed "Accumulated amount of fuel used during vehicle operation.";
CM_ SG_ 2566842878 EngTripFuel "Fuel consumed during all or part of a journey.";
CM_ BO_ 2633883646 "Front Wheel Drive Status";
CM_ SG_ 2633883646 FrontWheelDriveActuatorStatus "Feedback on the front wheel drive actuator.";
CM_ BO_ 2633880062 "FMS-standard Interface Identity/Capabilities";
CM_ SG_ 2633880062 FMSstandardSWversionSupported "Information that identifies which issue level of the FMS-standard document the software included in the FMS gateway supports.";
CM_ SG_ 2633880062 FMSstandardRqsSupported "Status signal which indicates if the FMS Vehicle Interface (FMS Gateway) will respond to requests from the FMS device";
CM_ SG_ 2633880062 FMSstandardDiagnosticsSupported "Status signal which indicates if the FMS Vehicle Interface (FMS Gateway) supports the handling of diagnostic messages";
CM_ BO_ 2566806526 "Forward Lane Image";
CM_ SG_ 2566806526 LnDprtureIndicationEnableStatus "Indicates whether lane departure indication is active.";
CM_ SG_ 2566806526 LaneTrackingStatusLeftSide "Indicates whether the left side is tracking lane.";
CM_ SG_ 2566806526 LaneTrackingStatusRightSide "Indicates whether right side is tracking lane.";
CM_ BO_ 2431649790 "Forward Lane Image urgent msg";
CM_ SG_ 2431649790 LaneDepartureImminentLeftSide "Indicates departure imminent on left side of lane.";
CM_ SG_ 2431649790 LaneDepartureImminentRightSide "Indicates departure imminent on right side of lane.";
CM_ SG_ 2431649790 LaneDepartureRight "Indicates that the middle of vehicle departs the lane on the right side.";
CM_ SG_ 2431649790 LaneDepartureLeft "Indicates that the middle of vehicle departs the lane on the left side.";
CM_ BO_ 2633929214 "Fuel Leakage";
CM_ SG_ 2633929214 EngFuelLeakage2 "Status signal which indicates fuel leakage in the fuel rail of the engine.";
CM_ SG_ 2633929214 EngFuelLeakage1 "Status signal which indicates fuel leakage in the fuel rail of the engine.";
CM_ BO_ 2566831614 "Fan Drive";
CM_ SG_ 2566831614 FanSpeed "The speed of the fan associated with engine coolant system.";
CM_ SG_ 2566831614 FanDriveState "This parameter is used to indicate the current state or mode of operation by the fan drive.";
CM_ SG_ 2566831614 EstPercentFanSpeed "Estimated fan speed as a ratio of the fan drive (current speed) to the fully engaged fan drive (maximum fan speed).";
CM_ SG_ 2566831614 HydFanMotorPress "The hydraulic pressure used to drive the fan system, sensed before the hydraulic fan motor.";
CM_ SG_ 2566831614 FanDriveBypassCmdStatus "Status of the Fan Drive Bypass Command as being commanded by the ECU.";
CM_ BO_ 2566820094 "Engine Torque History";
CM_ SG_ 2566820094 EngTorqueLimit6AxleInput "Limit applied to the engine output torque based on the maximum allowable axle input torque.";
CM_ SG_ 2566820094 EngTorqueLimit5Switch "Limit applied to the engine output torque based on activation of an ECU switch input.";
CM_ SG_ 2566820094 EngTorqueLimit4Trans "Limit applied to the engine output torque during vehicle operation in transmission gear ratios numerically less than or";
CM_ SG_ 2566820094 EngTorqueLimit3Trans "Limit applied to the engine output torque during vehicle operation in transmission gear ratios numerically less than or";
CM_ SG_ 2566820094 TransGearRatio3 "Gear ratio value stored in the ECU that is used to define a range of transmission gears for which a limit is applied to the";
CM_ SG_ 2566820094 EngTorqueLimit2Trans "Limit applied to the engine output torque during vehicle operation in transmission gear ratios numerically less than or";
CM_ SG_ 2566820094 TransGearRatio2 "Gear ratio value stored in the ECU that is used to define a range of transmission gears for which a limit is applied to the";
CM_ SG_ 2566820094 EngTorqueLimit1Trans "Limit applied to the engine output torque during vehicle operation in transmission gear ratios numerically greater than";
CM_ SG_ 2566820094 TransGearRatio1 "Gear ratio value stored in the ECU that is used to define a range of transmission gears for which a limit is applied to the";
CM_ SG_ 2566820094 EngTorqueLimitFeature "Torque limit rating described in the current record.";
CM_ SG_ 2566820094 TorqueLimitingFeatureStatus "Status of an ECU feature which limits the torque output of the engine.";
CM_ SG_ 2566820094 CalibRecordDurationTime "Duration in hours for which the engine operated in the conditions captured in the current record.";
CM_ SG_ 2566820094 CalibRecordStartYear "Calendar year timestamp when an ECU record was established.";
CM_ SG_ 2566820094 CalibRecordStartDay "Calendar day timestamp when an ECU record was established.";
CM_ SG_ 2566820094 CalibRecordStartMonth "Calendar month timestamp when an ECU record was established.";
CM_ SG_ 2566820094 EngPeakTorque2 "Maximum torque output of the current ECU calibration when the engine operates on torque curve 2.";
CM_ SG_ 2566820094 EngPeakTorque1 "Maximum torque output of the current ECU calibration when the engine operates on torque curve 1.";
CM_ SG_ 2566820094 EngPower "Advertised engine power capability.";
CM_ SG_ 2566820094 NumberOfEngTorqueHistoryRecords "Number of torque history records contained in the engine torque history PGN.";
CM_ BO_ 2364542206 "Electronic Transmission Controller #8";
CM_ SG_ 2364542206 TransClutch_ConverterInputSpeed "Rotational velocity of the input to a transmission's master clutch or torque converter.";
CM_ SG_ 2364542206 TransTorqueConverterRatio "Ratio of the transmissions torque converter output torque to torque converter input torque at current speed.";
CM_ BO_ 2566802174 "Electronic Transmission Controller 7";
CM_ SG_ 2566802174 TrnsRvrseGearShiftInhibitStatus "Reflects the status of transmission reverse inhibit activity in response to requests via SPN 4242 - Transmission Reverse";
CM_ SG_ 2566802174 TrnsCrrntRangeDisplayBlankState "State signal indicating a transmission request for the display of the Transmission Current Range parameter (SPN 163) to";
CM_ SG_ 2566802174 TransWarningIndicator "Signal from transmission indicating that some aspect of its operation is not functioning correctly, and as a result,";
CM_ SG_ 2566802174 TransMode8Indicator "Indicates whether transmission mode 8 is enabled.";
CM_ SG_ 2566802174 TransMode7Indicator "Indicates whether transmission mode 7 is enabled.";
CM_ SG_ 2566802174 TransMode6Indicator "Indicates whether transmission mode 6 is enabled.";
CM_ SG_ 2566802174 TransMode5Indicator "Indicates whether transmission mode 5 is enabled.";
CM_ SG_ 2566802174 TransRqedGearFeedback "Feedback of the SPN 525 Transmission Requested Gear input as received from the shift selector, ABS or engine via";
CM_ SG_ 2566802174 TransMode1Indicator "This state signal is the transmission's indication that it is operating under transmission mode 1 (SPN 1852) as";
CM_ SG_ 2566802174 TransMode2Indicator "This state signal is the transmission's indication that it is operating under transmission mode 2 (SPN 1853) as";
CM_ SG_ 2566802174 TransMode3Indicator "This state signal is the transmission's indication that it is operating under transmission mode 3 (SPN 1854) as";
CM_ SG_ 2566802174 TransMode4Indicator "This state signal is the transmission's indication that it is operating under transmission mode 4 (SPN 1855) as";
CM_ SG_ 2566802174 TransShiftInhibitIndicator "State signal indicating a transmission request for the Shift Inhibit Indicator to be active or inactive.";
CM_ SG_ 2566802174 TransEngCrankEnable "State signal from the transmission indicating if the transmission's status is such that engine cranking is allowed (i.";
CM_ SG_ 2566802174 ActiveShiftConsoleIndicator "Signal from transmission control unit indicating which shift console (primary or secondary) it currently considers as the";
CM_ SG_ 2566802174 TransReadyForBrakeRelease "This parameter indicates that enough torque / motive force is available at the transmission output shaft to release all the";
CM_ SG_ 2566802174 TransRqedRangeDisplayFlashState "State signal indicating a transmission request for the display of the Transmission Requested Range parameter (SPN 162)";
CM_ SG_ 2566802174 TransRqedRangeDisplayBlankState "State signal indicating a transmission request for the display of the Transmission Requested Range parameter (SPN162)";
CM_ SG_ 2566802174 TransServiceIndicator "Signal from transmission indicating that some aspect of the gearbox requires servicing, such as the oil, filter, clutch(es) or";
CM_ BO_ 2633935870 "Electronic Transmission Controller 6";
CM_ SG_ 2633935870 ClutchLifeRemaining "Signal which indicates the actual clutch life remaining in percent.";
CM_ SG_ 2633935870 LowestPossibleGear "The transmission calculates this gear continuously.";
CM_ SG_ 2633935870 HighestPossibleGear "The transmission calculates this gear continuously.";
CM_ SG_ 2633935870 RecommendedGear "The transmission calculates this gear continuously.";
CM_ BO_ 2633942014 "Electronic Transmission Controller 5";
CM_ SG_ 2633942014 TransForwardDirectionSwitch "Identifies the status of the switch that indicates forward direction.";
CM_ SG_ 2633942014 TransNeutralSwitch "Identifies the status of the switch that indicates neutral.";
CM_ SG_ 2633942014 TransReverseDirectionSwitch "Identifies the status of the switch that indicates reverse direction.";
CM_ SG_ 2633942014 TransLowRangeSenseSwitch "Identifies the status of the switch that represents low range.";
CM_ SG_ 2633942014 TransHighRangeSenseSwitch "Identifies the status of the switch that represents high range.";
CM_ BO_ 2633942526 "Electronic Transmission Controller 4";
CM_ SG_ 2633942526 TransSynchronizerBrakeValue "The current modulated value for the air supply to the synchronizer brake.";
CM_ SG_ 2633942526 TransSynchronizerClutchValue "The current modulated value for the air supply to the synchronizer clutch.";
CM_ BO_ 2633943038 "Electronic Transmission Controller 3";
CM_ SG_ 2633943038 TransInertiaBrakeActuator "Identifies the status of the actuator that controls the inertia brake.";
CM_ SG_ 2633943038 TransDefuelActuator "Identifies the status of the actuator that controls the engine defuel mechanism.";
CM_ SG_ 2633943038 TransLockupClutchActuator "Identifies the status of the actuator that controls the lockup clutch.";
CM_ SG_ 2633943038 TransClutchActuator "Identifies the status of the actuator that controls the clutch.";
CM_ SG_ 2633943038 TransSplitterIndirectActuator "Identifies the status of the splitter indirect actuator in the auxiliary unit.";
CM_ SG_ 2633943038 TransSplitterDirectActuator "Identifies the status of the splitter direct actuator in the auxiliary unit.";
CM_ SG_ 2633943038 TransRangeLowActuator "Identifies the status of the range low actuator in the auxiliary unit.";
CM_ SG_ 2633943038 TransRangeHighActuator "Identifies the status of the range high actuator in the auxiliary unit.";
CM_ SG_ 2633943038 TransShiftFingerGearActuator2 "Identifies the status of the actuator that moves the shift finger identified as gear actuator #2.";
CM_ SG_ 2633943038 TransShiftFingerRailActuator2 "Identifies the status of the actuator that moves the shift finger identified as rail actuator #2.";
CM_ SG_ 2633943038 TransShiftFingerGearActuator1 "Identifies the status of the actuator that moves the shift finger identified as gear actuator #1.";
CM_ SG_ 2633943038 TransShiftFingerRailActuator1 "Identifies the status of the actuator that moves the shift finger identified as rail actuator #1.";
CM_ SG_ 2633943038 TrnsShftFngrCenterRailIndicator "Identifies the status of the shift finger in the center rail position.";
CM_ SG_ 2633943038 TrnsShftFngrEngagementIndicator "Identifies the status of the shift finger in the engagement position.";
CM_ SG_ 2633943038 TrnsShiftFingerNeutralIndicator "Indicates the status of the shift finger in the neutral position.";
CM_ SG_ 2633943038 TransShiftFingerRailPos "The current position of the shift finger in the rail direction.";
CM_ SG_ 2633943038 TransShiftFingerGearPos "The current position of the shift finger in the gear direction.";
CM_ BO_ 2565867006 "Electronic Transmission Controller 2";
CM_ SG_ 2565867006 TransCurrentRange "Range currently being commanded by the transmission control system.";
CM_ SG_ 2565867006 TransRqedRange "Range selected by the operator.";
CM_ SG_ 2565867006 TransCurrentGear "The gear currently engaged in the transmission or the last gear engaged while the transmission is in the process of";
CM_ SG_ 2565867006 TransActualGearRatio "Actual ratio of input shaft speed to output shaft speed.";
CM_ SG_ 2565867006 TransSelectedGear "The gear that the transmission will attempt to achieve during the current shift if a shift is in progress, or the next shift if one";
CM_ BO_ 2565866755 "Electronic Transmission Controller 2";
CM_ SG_ 2565866755 TransCurrentRange "Range currently being commanded by the transmission control system.";
CM_ SG_ 2565866755 TransRqedRange "Range selected by the operator.";
CM_ SG_ 2565866755 TransCurrentGear "The gear currently engaged in the transmission or the last gear engaged while the transmission is in the process of";
CM_ SG_ 2565866755 TransActualGearRatio "Actual ratio of input shaft speed to output shaft speed.";
CM_ SG_ 2565866755 TransSelectedGear "The gear that the transmission will attempt to achieve during the current shift if a shift is in progress, or the next shift if one";
CM_ BO_ 2364539646 "Electronic Transmission Controller 1";
CM_ SG_ 2364539646 TrnsTrqueConverterLockupEngaged "State signal which indicates whether the torque converter lockup is engaged.";
CM_ SG_ 2364539646 TrnsTrqCnvrtrLckpTrnstnInPrcess "State signal indicating whether or not the transmission torque converter lock up clutch is transitioning between being";
CM_ SG_ 2364539646 SrcAddrssOfCtrllngDvcFrTrnsCntrl "The source address of the SAE J1939 device currently controlling the transmission.";
CM_ SG_ 2364539646 MomentaryEngMaxPowerEnable "Momentarily Requesting highest torque map from the engine control";
CM_ SG_ 2364539646 TransInputShaftSpeed "Rotational velocity of the primary shaft transferring power into the transmission.";
CM_ SG_ 2364539646 ProgressiveShiftDisable "Command signal used to indicate that progressive shifting by the engine should be disallowed.";
CM_ SG_ 2364539646 EngMomentaryOverspeedEnable "Command signal used to indicate that the engine speed may be boosted up to the maximum engine overspeed value to";
CM_ SG_ 2364539646 PercentClutchSlip "Parameter which represents the ratio of input shaft speed to current engine speed (in percent).";
CM_ SG_ 2364539646 TransOutputShaftSpeed "Calculated speed of the transmission output shaft.";
CM_ SG_ 2364539646 TransShiftInProcess "Indicates that the transmission is in process of shifting from the current gear to the selected gear.";
CM_ SG_ 2364539646 TransDrivelineEngaged "Driveline engaged indicates the transmission controlled portion of the driveline is engaged sufficiently to allow a transfer";
CM_ BO_ 2364539395 "Electronic Transmission Controller 1";
CM_ SG_ 2364539395 TrnsTrqueConverterLockupEngaged "State signal which indicates whether the torque converter lockup is engaged.";
CM_ SG_ 2364539395 TrnsTrqCnvrtrLckpTrnstnInPrcess "State signal indicating whether or not the transmission torque converter lock up clutch is transitioning between being";
CM_ SG_ 2364539395 SrcAddrssOfCtrllngDvcFrTrnsCntrl "The source address of the SAE J1939 device currently controlling the transmission.";
CM_ SG_ 2364539395 MomentaryEngMaxPowerEnable "Momentarily Requesting highest torque map from the engine control";
CM_ SG_ 2364539395 TransInputShaftSpeed "Rotational velocity of the primary shaft transferring power into the transmission.";
CM_ SG_ 2364539395 ProgressiveShiftDisable "Command signal used to indicate that progressive shifting by the engine should be disallowed.";
CM_ SG_ 2364539395 EngMomentaryOverspeedEnable "Command signal used to indicate that the engine speed may be boosted up to the maximum engine overspeed value to";
CM_ SG_ 2364539395 PercentClutchSlip "Parameter which represents the ratio of input shaft speed to current engine speed (in percent).";
CM_ SG_ 2364539395 TransOutputShaftSpeed "Calculated speed of the transmission output shaft.";
CM_ SG_ 2364539395 TransShiftInProcess "Indicates that the transmission is in process of shifting from the current gear to the selected gear.";
CM_ SG_ 2364539395 TransDrivelineEngaged "Driveline engaged indicates the transmission controlled portion of the driveline is engaged sufficiently to allow a transfer";
CM_ BO_ 2566810110 "Engine Temperature 3";
CM_ SG_ 2566810110 EngChargeAirCooler1OutletTemp "Temperature of combustion air after it exits from the Charge Air Cooler 1 but before any mixing of recirculated exhaust";
CM_ SG_ 2566810110 EngIntkVlvActationSystemOilTemp "The temperature of the oil in the hydraulic system that powers the intake valve actuation system.";
CM_ SG_ 2566810110 EngIntakeManifold1AirTemp "Temperature of pre-combustion air found in intake manifold of engine air supply system.";
CM_ SG_ 2566810110 EngCoolantTempHiRes "Temperature of liquid found in engine cooling system.";
CM_ BO_ 2566825214 "Engine Temperature 2";
CM_ SG_ 2566825214 EngExhstGsRcrculation1DiffPress "Differential pressure across the Exhaust Gas Recirculation (EGR) system";
CM_ SG_ 2566825214 EngExhaustGasRecirculation1Temp "Temperature of Recirculated Exhaust Gas.";
CM_ SG_ 2566825214 EngECUTemp "Temperature of the engine electronic control unit.";
CM_ SG_ 2566825214 EngOilTemp2 "Temperature of the engine lubricant.";
CM_ BO_ 2566844158 "Engine Temperature 1";
CM_ SG_ 2566844158 EngFuelTemp1 "Temperature of fuel (or gas) passing through the first fuel control system.";
CM_ SG_ 2566844158 EngIntercoolerThermostatOpening "The current position of the thermostat used to regulate the temperature of the engine intercooler.";
CM_ SG_ 2566844158 EngIntercoolerTemp "Temperature of liquid found in the intercooler located after the turbocharger.";
CM_ SG_ 2566844158 EngTurboOilTemp "Temperature of the turbocharger lubricant.";
CM_ SG_ 2566844158 EngOilTemp1 "Temperature of the engine lubricant.";
CM_ SG_ 2566844158 EngCoolantTemp "Temperature of liquid found in engine cooling system.";
CM_ BO_ 2566843904 "Engine Temperature 1";
CM_ SG_ 2566843904 EngFuelTemp1 "Temperature of fuel (or gas) passing through the first fuel control system.";
CM_ SG_ 2566843904 EngIntercoolerThermostatOpening "The current position of the thermostat used to regulate the temperature of the engine intercooler.";
CM_ SG_ 2566843904 EngIntercoolerTemp "Temperature of liquid found in the intercooler located after the turbocharger.";
CM_ SG_ 2566843904 EngTurboOilTemp "Temperature of the turbocharger lubricant.";
CM_ SG_ 2566843904 EngOilTemp1 "Temperature of the engine lubricant.";
CM_ SG_ 2566843904 EngCoolantTemp "Temperature of liquid found in engine cooling system.";
CM_ BO_ 2566785022 "Exhaust Temperature";
CM_ SG_ 2566785022 EngExhaustGasTempRightManifold "Temperature of combustion byproducts within the right engine exhaust manifold.";
CM_ SG_ 2566785022 EngExhaustGasTempLeftManifold "Temperature of combustion byproducts within the left engine exhaust manifold.";
CM_ BO_ 2565868542 "Electronic Steering Control";
CM_ SG_ 2565868542 SterableLiftAxleLoweringInhibit "A signal which indicates if lowering of lifted axle is allowed or inhibited.";
CM_ SG_ 2565868542 AxleLocation "To identify to which of several similar devices (such as tires or fuel tanks) the information applies.";
CM_ SG_ 2565868542 TypeOfSteerTrans "Type of Steering Transmission (Ref.";
CM_ SG_ 2565868542 TypeOfSteerForces "Type of Steering Forces (Ref.";
CM_ SG_ 2565868542 SteerType "Indicates the different types of steering systems (ref.";
CM_ SG_ 2565868542 StatusOfSteerAxle "A signal which indicates different states of the steering axle";
CM_ SG_ 2565868542 ActualInnerWheelSteerAngle "Signal which indicates the actual inner wheel steering angle.";
CM_ BO_ 2633941758 "Electronic Retarder Controller 2";
CM_ SG_ 2633941758 TransOutputRetarder "Identifies the status of the transmission output retarder.";
CM_ BO_ 2565865726 "Electronic Retarder Controller 1";
CM_ SG_ 2565865726 RetarderSelectionNonEng "The [Retarder Selection, non-engine] is the position of the driver's selector for retarders that are not part of the engine";
CM_ SG_ 2565865726 SrcAddrssOfCtrllngDvcFrRtrdrCntr "The source address of the SAE J1939 device currently controlling the retarder.";
CM_ SG_ 2565865726 RetarderRoadSpeedLimitSwitch "Retarder road speed limit switch states:";
CM_ SG_ 2565865726 RetarderRoadSpeedExceededStatus "Retarder Road Speed Exceeded Status:";
CM_ SG_ 2565865726 ActlMxAvlblRtarderPercentTorque "This is the maximum amount of torque that the retarder can immediately deliver.";
CM_ SG_ 2565865726 DrvrsDmandRetarderPercentTorque "The Drivers demand retarder percent torque is the maximum torque selected by the driver when one or more modes";
CM_ SG_ 2565865726 RetarderRqingBrakeLight "Indicates that whether the retarder is requesting that the brake lights are illuminated.";
CM_ SG_ 2565865726 EngCoolantLoadIncrease "Status of an event, external to the engine, that may increase the nominal temperature of the engine coolant liquid.";
CM_ SG_ 2565865726 IntendedRetarderPercentTorque "Braking torque of retarder that the retarder is currently trying to achieve.";
CM_ SG_ 2565865726 ActualRetarderPercentTorque "Actual braking torque of the retarder as a percent of retarder configuration reference torque SPN 556.";
CM_ SG_ 2565865726 RetarderEnableShiftAssistSwitch "Switch signal which indicates whether the operator wishes the retarder to be enabled for transmission shift assist.";
CM_ SG_ 2565865726 RetarderEnableBrakeAssistSwitch "Switch signal which indicates whether the operator wishes the retarder to be enabled for vehicle braking assist.";
CM_ SG_ 2565865726 RetarderTorqueMode "State signal which indicates which retarder torque mode is currently generating, limiting, or controlling the torque.";
CM_ BO_ 2565865487 "Electronic Retarder Controller 1";
CM_ SG_ 2565865487 RetarderSelectionNonEng "The [Retarder Selection, non-engine] is the position of the driver's selector for retarders that are not part of the engine";
CM_ SG_ 2565865487 SrcAddrssOfCtrllngDvcFrRtrdrCntr "The source address of the SAE J1939 device currently controlling the retarder.";
CM_ SG_ 2565865487 RetarderRoadSpeedLimitSwitch "Retarder road speed limit switch states:";
CM_ SG_ 2565865487 RetarderRoadSpeedExceededStatus "Retarder Road Speed Exceeded Status:";
CM_ SG_ 2565865487 ActlMxAvlblRtarderPercentTorque "This is the maximum amount of torque that the retarder can immediately deliver.";
CM_ SG_ 2565865487 DrvrsDmandRetarderPercentTorque "The Drivers demand retarder percent torque is the maximum torque selected by the driver when one or more modes";
CM_ SG_ 2565865487 RetarderRqingBrakeLight "Indicates that whether the retarder is requesting that the brake lights are illuminated.";
CM_ SG_ 2565865487 EngCoolantLoadIncrease "Status of an event, external to the engine, that may increase the nominal temperature of the engine coolant liquid.";
CM_ SG_ 2565865487 IntendedRetarderPercentTorque "Braking torque of retarder that the retarder is currently trying to achieve.";
CM_ SG_ 2565865487 ActualRetarderPercentTorque "Actual braking torque of the retarder as a percent of retarder configuration reference torque SPN 556.";
CM_ SG_ 2565865487 RetarderEnableShiftAssistSwitch "Switch signal which indicates whether the operator wishes the retarder to be enabled for transmission shift assist.";
CM_ SG_ 2565865487 RetarderEnableBrakeAssistSwitch "Switch signal which indicates whether the operator wishes the retarder to be enabled for vehicle braking assist.";
CM_ SG_ 2565865487 RetarderTorqueMode "State signal which indicates which retarder torque mode is currently generating, limiting, or controlling the torque.";
CM_ BO_ 2565865488 "Electronic Retarder Controller 1";
CM_ SG_ 2565865488 RetarderSelectionNonEng "The [Retarder Selection, non-engine] is the position of the driver's selector for retarders that are not part of the engine";
CM_ SG_ 2565865488 SrcAddrssOfCtrllngDvcFrRtrdrCntr "The source address of the SAE J1939 device currently controlling the retarder.";
CM_ SG_ 2565865488 RetarderRoadSpeedLimitSwitch "Retarder road speed limit switch states:";
CM_ SG_ 2565865488 RetarderRoadSpeedExceededStatus "Retarder Road Speed Exceeded Status:";
CM_ SG_ 2565865488 ActlMxAvlblRtarderPercentTorque "This is the maximum amount of torque that the retarder can immediately deliver.";
CM_ SG_ 2565865488 DrvrsDmandRetarderPercentTorque "The Drivers demand retarder percent torque is the maximum torque selected by the driver when one or more modes";
CM_ SG_ 2565865488 RetarderRqingBrakeLight "Indicates that whether the retarder is requesting that the brake lights are illuminated.";
CM_ SG_ 2565865488 EngCoolantLoadIncrease "Status of an event, external to the engine, that may increase the nominal temperature of the engine coolant liquid.";
CM_ SG_ 2565865488 IntendedRetarderPercentTorque "Braking torque of retarder that the retarder is currently trying to achieve.";
CM_ SG_ 2565865488 ActualRetarderPercentTorque "Actual braking torque of the retarder as a percent of retarder configuration reference torque SPN 556.";
CM_ SG_ 2565865488 RetarderEnableShiftAssistSwitch "Switch signal which indicates whether the operator wishes the retarder to be enabled for transmission shift assist.";
CM_ SG_ 2565865488 RetarderEnableBrakeAssistSwitch "Switch signal which indicates whether the operator wishes the retarder to be enabled for vehicle braking assist.";
CM_ SG_ 2565865488 RetarderTorqueMode "State signal which indicates which retarder torque mode is currently generating, limiting, or controlling the torque.";
CM_ BO_ 2633932798 "Exhaust Port Temperature 5";
CM_ SG_ 2633932798 EngExhaustGasPort20Temp "Temperature at the cylinder exhaust port of the engine.";
CM_ SG_ 2633932798 EngExhaustGasPort19Temp "Temperature at the cylinder exhaust port of the engine.";
CM_ SG_ 2633932798 EngExhaustGasPort18Temp "Temperature at the cylinder exhaust port of the engine.";
CM_ SG_ 2633932798 EngExhaustGasPort17Temp "Temperature at the cylinder exhaust port of the engine.";
CM_ BO_ 2566824190 "Exhaust Port Temperature 4";
CM_ SG_ 2566824190 EngExhaustGasPort16Temp "Temperature at the cylinder exhaust port of the engine.";
CM_ SG_ 2566824190 EngExhaustGasPort15Temp "Temperature at the cylinder exhaust port of the engine.";
CM_ SG_ 2566824190 EngExhaustGasPort14Temp "Temperature at the cylinder exhaust port of the engine.";
CM_ SG_ 2566824190 EngExhaustGasPort13Temp "Temperature at the cylinder exhaust port of the engine.";
CM_ BO_ 2633933310 "Exhaust Port Temperature 3";
CM_ SG_ 2633933310 EngExhaustGasPort12Temp "Temperature at the cylinder exhaust port of the engine.";
CM_ SG_ 2633933310 EngExhaustGasPort11Temp "Temperature at the cylinder exhaust port of the engine.";
CM_ SG_ 2633933310 EngExhaustGasPort10Temp "Temperature at the cylinder exhaust port of the engine.";
CM_ SG_ 2633933310 EngExhaustGasPort9Temp "Temperature at the cylinder exhaust port of the engine.";
CM_ BO_ 2633933566 "Exhaust Port Temperature 2";
CM_ SG_ 2633933566 EngExhaustGasPort8Temp "Temperature at the cylinder exhaust port of the engine.";
CM_ SG_ 2633933566 EngExhaustGasPort7Temp "Temperature at the cylinder exhaust port of the engine.";
CM_ SG_ 2633933566 EngExhaustGasPort6Temp "Temperature at the cylinder exhaust port of the engine.";
CM_ SG_ 2633933566 EngExhaustGasPort5Temp "Temperature at the cylinder exhaust port of the engine.";
CM_ BO_ 2633933822 "Exhaust Port Temperature 1";
CM_ SG_ 2633933822 EngExhaustGasPort4Temp "Temperature at the cylinder exhaust port of the engine.";
CM_ SG_ 2633933822 EngExhaustGasPort3Temp "Temperature at the cylinder exhaust port of the engine.";
CM_ SG_ 2633933822 EngExhaustGasPort2Temp "Temperature at the cylinder exhaust port of the engine.";
CM_ SG_ 2633933822 EngExhaustGasPort1Temp "Temperature at the cylinder exhaust port of the engine.";
CM_ BO_ 2566776062 "Equipment Performance Data";
CM_ SG_ 2566776062 PayloadPercentage "The current payload of the equipment, reported as a percentage of the equipment's rated payload limit.";
CM_ BO_ 2566771454 "ECU Performance";
CM_ SG_ 2566771454 DataMemoryUsage "The used storage capacity of the data buffer memory internal to an ECU, such as a data logger.";
CM_ SG_ 2566771454 KeepAliveBatteryConsumption "The capacity consumed from the direct battery connection since the key was last turned off.";
CM_ BO_ 2566775806 "Equipment Operation and Control";
CM_ SG_ 2566775806 TravelVelocityCtrlPos "The position of the travel velocity control component reported as a percentage of the control's full displacement in each";
CM_ BO_ 2633935358 "Exhaust Oxygen 1";
CM_ SG_ 2633935358 EngExhstGsOxygnSnsrClsdLpOprton "Indicates whether the engine is using the Exhaust Gas Oxygen sensor to control the air/fuel ratio.";
CM_ SG_ 2633935358 EngExhstGsOxygnSnsrFlngCrrction "The amount of fueling change required by the system based on the measured Exhaust Oxygen value compared to the";
CM_ SG_ 2633935358 EngActualExhaustOxygen "The actual amount of oxygen in the exhaust represented as a percentage by volume with respect to the total volume of";
CM_ SG_ 2633935358 EngDesiredExhaustOxygen "The desired amount of oxygen in the exhaust represented as a percentage by volume with respect to the total volume of";
CM_ SG_ 2633935358 EngDesiredRatedExhaustOxygen "The desired amount of oxygen in the exhaust at rated conditions represented as a percentage by volume with respect to";
BA_DEF_ SG_  "SigType" ENUM  "Default","Range","RangeSigned","ASCII","Discrete","Control","ReferencePGN","DTC","StringDelimiter","StringLength","StringLengthControl";
BA_DEF_ SG_  "GenSigStartValue" INT 0 10000;
BA_DEF_ SG_  "GenSigSendType" ENUM  "Cyclic","OnWrite","reserved","OnChange","reserved","reserved","reserved","NoSigSendType";
BA_DEF_ SG_  "GenSigILSupport" ENUM  "Yes","No";
BA_DEF_ SG_  "GenSigEVName" STRING ;
BA_DEF_ SG_  "SPN" INT 0 524287;
BA_DEF_ BO_  "GenMsgStartDelayTime" INT 0 100000;
BA_DEF_ BO_  "GenMsgILSupport" ENUM  "Yes","No";
BA_DEF_ BO_  "GenMsgRequestable" INT 0 1;
BA_DEF_ BO_  "GenMsgSendType" ENUM  "cyclic","reserved","cyclicIfActive","reserved","reserved","reserved","reserved","reserved","noMsgSendType";
BA_DEF_ BO_  "VFrameFormat" ENUM  "StandardCAN","ExtendedCAN","reserved","J1939PG";
BA_DEF_ BO_  "GenMsgCycleTime" INT 0 3600000;
BA_DEF_ SG_  "SystemSignalLongSymbol" STRING ;
BA_DEF_DEF_  "SigType" "Default";
BA_DEF_DEF_  "GenSigStartValue" 0;
BA_DEF_DEF_  "GenSigSendType" "NoSigSendType";
BA_DEF_DEF_  "GenSigILSupport" "Yes";
BA_DEF_DEF_  "GenSigEVName" "Env@Nodename_@Signame";
BA_DEF_DEF_  "SPN" 0;
BA_DEF_DEF_  "GenMsgStartDelayTime" 0;
BA_DEF_DEF_  "GenMsgILSupport" "Yes";
BA_DEF_DEF_  "GenMsgRequestable" 1;
BA_DEF_DEF_  "GenMsgSendType" "noMsgSendType";
BA_DEF_DEF_  "VFrameFormat" "J1939PG";
BA_DEF_DEF_  "GenMsgCycleTime" 0;
BA_DEF_DEF_  "SystemSignalLongSymbol" "";
BA_ "GenMsgCycleTime" BO_ 2566839806 1000;
BA_ "GenMsgSendType" BO_ 2566839806 0;
BA_ "GenMsgCycleTime" BO_ 2566775550 1000;
BA_ "GenMsgSendType" BO_ 2566775550 2;
BA_ "GenMsgCycleTime" BO_ 2566775343 1000;
BA_ "GenMsgSendType" BO_ 2566775343 2;
BA_ "GenMsgCycleTime" BO_ 2566819838 1000;
BA_ "GenMsgSendType" BO_ 2566819838 0;
BA_ "GenMsgCycleTime" BO_ 2566841598 1000;
BA_ "GenMsgSendType" BO_ 2566841598 0;
BA_ "GenMsgCycleTime" BO_ 2566804478 5000;
BA_ "GenMsgSendType" BO_ 2566804478 0;
BA_ "GenMsgCycleTime" BO_ 2566847486 1000;
BA_ "GenMsgSendType" BO_ 2566847486 0;
BA_ "GenMsgCycleTime" BO_ 2566847248 1000;
BA_ "GenMsgSendType" BO_ 2566847248 0;
BA_ "GenMsgCycleTime" BO_ 2566844670 100;
BA_ "GenMsgSendType" BO_ 2566844670 0;
BA_ "GenMsgCycleTime" BO_ 2566844416 100;
BA_ "GenMsgSendType" BO_ 2566844416 0;
BA_ "GenMsgCycleTime" BO_ 2566770174 200;
BA_ "GenMsgSendType" BO_ 2566770174 0;
BA_ "GenMsgCycleTime" BO_ 2566769662 500;
BA_ "GenMsgSendType" BO_ 2566769662 0;
BA_ "GenMsgCycleTime" BO_ 2566768638 500;
BA_ "GenMsgSendType" BO_ 2566768638 0;
BA_ "GenMsgCycleTime" BO_ 2566776318 1000;
BA_ "GenMsgSendType" BO_ 2566776318 0;
BA_ "GenMsgCycleTime" BO_ 2566802686 500;
BA_ "GenMsgSendType" BO_ 2566802686 0;
BA_ "GenMsgCycleTime" BO_ 2566774014 1000;
BA_ "GenMsgSendType" BO_ 2566774014 0;
BA_ "GenMsgCycleTime" BO_ 2566823166 1000;
BA_ "GenMsgSendType" BO_ 2566823166 0;
BA_ "GenMsgCycleTime" BO_ 2566823422 1000;
BA_ "GenMsgSendType" BO_ 2566823422 0;
BA_ "GenMsgCycleTime" BO_ 2566823678 1000;
BA_ "GenMsgSendType" BO_ 2566823678 0;
BA_ "GenMsgCycleTime" BO_ 2432595710 100;
BA_ "GenMsgSendType" BO_ 2432595710 0;
BA_ "GenMsgCycleTime" BO_ 2365486590 50;
BA_ "GenMsgSendType" BO_ 2365486590 0;
BA_ "GenMsgCycleTime" BO_ 2365485566 50;
BA_ "GenMsgSendType" BO_ 2365485566 0;
BA_ "GenMsgCycleTime" BO_ 2365486334 50;
BA_ "GenMsgSendType" BO_ 2365486334 0;
BA_ "GenMsgCycleTime" BO_ 2364542462 100;
BA_ "GenMsgSendType" BO_ 2364542462 0;
BA_ "GenMsgCycleTime" BO_ 2365486078 50;
BA_ "GenMsgSendType" BO_ 2365486078 0;
BA_ "GenMsgCycleTime" BO_ 2566845182 100;
BA_ "GenMsgSendType" BO_ 2566845182 0;
BA_ "GenMsgCycleTime" BO_ 2566844928 100;
BA_ "GenMsgSendType" BO_ 2566844928 0;
BA_ "GenMsgCycleTime" BO_ 2633883646 500;
BA_ "GenMsgSendType" BO_ 2633883646 0;
BA_ "GenMsgCycleTime" BO_ 2633880062 10000;
BA_ "GenMsgSendType" BO_ 2633880062 0;
BA_ "GenMsgCycleTime" BO_ 2566806526 100;
BA_ "GenMsgSendType" BO_ 2566806526 0;
BA_ "GenMsgCycleTime" BO_ 2431649790 50;
BA_ "GenMsgSendType" BO_ 2431649790 2;
BA_ "GenMsgCycleTime" BO_ 2633929214 1000;
BA_ "GenMsgSendType" BO_ 2633929214 0;
BA_ "GenMsgCycleTime" BO_ 2566831614 1000;
BA_ "GenMsgSendType" BO_ 2566831614 0;
BA_ "GenMsgCycleTime" BO_ 2364542206 20;
BA_ "GenMsgSendType" BO_ 2364542206 0;
BA_ "GenMsgCycleTime" BO_ 2566802174 100;
BA_ "GenMsgSendType" BO_ 2566802174 0;
BA_ "GenMsgCycleTime" BO_ 2565867006 100;
BA_ "GenMsgSendType" BO_ 2565867006 0;
BA_ "GenMsgCycleTime" BO_ 2565866755 100;
BA_ "GenMsgSendType" BO_ 2565866755 0;
BA_ "GenMsgCycleTime" BO_ 2364539646 10;
BA_ "GenMsgSendType" BO_ 2364539646 0;
BA_ "GenMsgCycleTime" BO_ 2364539395 10;
BA_ "GenMsgSendType" BO_ 2364539395 0;
BA_ "GenMsgCycleTime" BO_ 2566810110 1000;
BA_ "GenMsgSendType" BO_ 2566810110 0;
BA_ "GenMsgCycleTime" BO_ 2566825214 1000;
BA_ "GenMsgSendType" BO_ 2566825214 0;
BA_ "GenMsgCycleTime" BO_ 2566844158 1000;
BA_ "GenMsgSendType" BO_ 2566844158 0;
BA_ "GenMsgCycleTime" BO_ 2566843904 1000;
BA_ "GenMsgSendType" BO_ 2566843904 0;
BA_ "GenMsgCycleTime" BO_ 2566785022 500;
BA_ "GenMsgSendType" BO_ 2566785022 0;
BA_ "GenMsgCycleTime" BO_ 2565868542 20;
BA_ "GenMsgSendType" BO_ 2565868542 0;
BA_ "GenMsgCycleTime" BO_ 2633941758 1000;
BA_ "GenMsgSendType" BO_ 2633941758 2;
BA_ "GenMsgCycleTime" BO_ 2565865726 100;
BA_ "GenMsgSendType" BO_ 2565865726 0;
BA_ "GenMsgCycleTime" BO_ 2565865487 100;
BA_ "GenMsgSendType" BO_ 2565865487 0;
BA_ "GenMsgCycleTime" BO_ 2565865488 100;
BA_ "GenMsgSendType" BO_ 2565865488 0;
BA_ "GenMsgCycleTime" BO_ 2633932798 1000;
BA_ "GenMsgSendType" BO_ 2633932798 0;
BA_ "GenMsgCycleTime" BO_ 2566824190 1000;
BA_ "GenMsgSendType" BO_ 2566824190 0;
BA_ "GenMsgCycleTime" BO_ 2633933310 1000;
BA_ "GenMsgSendType" BO_ 2633933310 0;
BA_ "GenMsgCycleTime" BO_ 2633933566 1000;
BA_ "GenMsgSendType" BO_ 2633933566 0;
BA_ "GenMsgCycleTime" BO_ 2633933822 1000;
BA_ "GenMsgSendType" BO_ 2633933822 0;
BA_ "GenMsgCycleTime" BO_ 2566776062 500;
BA_ "GenMsgSendType" BO_ 2566776062 0;
BA_ "GenMsgCycleTime" BO_ 2566775806 250;
BA_ "GenMsgSendType" BO_ 2566775806 0;
BA_ "SPN" SG_ 2348941054 TrnsShftSlctorDisplayModeSwitch 2985;
BA_ "SigType" SG_ 2348941054 TrnsShftSlctorDisplayModeSwitch 4;
BA_ "SPN" SG_ 2348941054 TransMode4 1855;
BA_ "SigType" SG_ 2348941054 TransMode4 4;
BA_ "SPN" SG_ 2348941054 TransMode3 1854;
BA_ "SigType" SG_ 2348941054 TransMode3 4;
BA_ "SPN" SG_ 2348941054 TransMode2 1853;
BA_ "SigType" SG_ 2348941054 TransMode2 4;
BA_ "SPN" SG_ 2348941054 TransMode1 1852;
BA_ "SigType" SG_ 2348941054 TransMode1 4;
BA_ "SPN" SG_ 2348941054 DisengageDiffLockRqCentralRear 691;
BA_ "SigType" SG_ 2348941054 DisengageDiffLockRqCentralRear 4;
BA_ "SPN" SG_ 2348941054 DisengageDiffLockRqCentralFront 690;
BA_ "SigType" SG_ 2348941054 DisengageDiffLockRqCentralFront 4;
BA_ "SPN" SG_ 2348941054 DisengageDiffLockRqCentral 689;
BA_ "SigType" SG_ 2348941054 DisengageDiffLockRqCentral 4;
BA_ "SPN" SG_ 2348941054 DisengageDiffLockRqRearAxle2 688;
BA_ "SigType" SG_ 2348941054 DisengageDiffLockRqRearAxle2 4;
BA_ "SPN" SG_ 2348941054 DisengageDiffLockRqRearAxle1 687;
BA_ "SigType" SG_ 2348941054 DisengageDiffLockRqRearAxle1 4;
BA_ "SPN" SG_ 2348941054 DisengageDiffLockRqFrontAxle2 686;
BA_ "SigType" SG_ 2348941054 DisengageDiffLockRqFrontAxle2 4;
BA_ "SPN" SG_ 2348941054 DisengageDiffLockRqFrontAxle1 685;
BA_ "SigType" SG_ 2348941054 DisengageDiffLockRqFrontAxle1 4;
BA_ "SPN" SG_ 2348941054 TransRqedGear 525;
BA_ "SigType" SG_ 2348941054 TransRqedGear 1;
BA_ "SPN" SG_ 2348941054 RqedPercentClutchSlip 684;
BA_ "SigType" SG_ 2348941054 RqedPercentClutchSlip 1;
BA_ "SPN" SG_ 2348941054 DisengageDrivelineRq 683;
BA_ "SigType" SG_ 2348941054 DisengageDrivelineRq 4;
BA_ "SPN" SG_ 2348941054 TransGearShiftInhibitRq 681;
BA_ "SigType" SG_ 2348941054 TransGearShiftInhibitRq 4;
BA_ "SPN" SG_ 2348941054 TrnsTrqConverterLockupDisableRq 682;
BA_ "SigType" SG_ 2348941054 TrnsTrqConverterLockupDisableRq 4;
BA_ "SPN" SG_ 2348941054 TransRqedLaunchGear 4255;
BA_ "SigType" SG_ 2348941054 TransRqedLaunchGear 4;
BA_ "SPN" SG_ 2348941054 TransReverseGearShiftInhibitRq 4242;
BA_ "SigType" SG_ 2348941054 TransReverseGearShiftInhibitRq 4;
BA_ "SPN" SG_ 2348941054 TransMode8 4249;
BA_ "SigType" SG_ 2348941054 TransMode8 4;
BA_ "SPN" SG_ 2348941054 TransMode7 4248;
BA_ "SigType" SG_ 2348941054 TransMode7 4;
BA_ "SPN" SG_ 2348941054 TransMode6 4247;
BA_ "SigType" SG_ 2348941054 TransMode6 4;
BA_ "SPN" SG_ 2348941054 TransMode5 4246;
BA_ "SigType" SG_ 2348941054 TransMode5 4;
BA_ "SPN" SG_ 2566839806 EngTurboOilLevelSwitch 1665;
BA_ "SigType" SG_ 2566839806 EngTurboOilLevelSwitch 4;
BA_ "SPN" SG_ 2566839806 EngTurbo1Speed 103;
BA_ "SigType" SG_ 2566839806 EngTurbo1Speed 1;
BA_ "SPN" SG_ 2566839806 EngTurboLubeOilPress1 104;
BA_ "SigType" SG_ 2566839806 EngTurboLubeOilPress1 1;
BA_ "SPN" SG_ 2633911806 EngTotalAverageFuelEconomy 1835;
BA_ "SigType" SG_ 2633911806 EngTotalAverageFuelEconomy 1;
BA_ "SPN" SG_ 2633911806 EngTotalAverageFuelRate 1834;
BA_ "SigType" SG_ 2633911806 EngTotalAverageFuelRate 1;
BA_ "SPN" SG_ 2566775550 AirSuspensionSupplyPressRq 2608;
BA_ "SigType" SG_ 2566775550 AirSuspensionSupplyPressRq 1;
BA_ "SPN" SG_ 2566775550 AuxEquipmentSupplyPressRq 2607;
BA_ "SigType" SG_ 2566775550 AuxEquipmentSupplyPressRq 1;
BA_ "SPN" SG_ 2566775550 ServiceBrakeAirPressRqCircuit2 2606;
BA_ "SigType" SG_ 2566775550 ServiceBrakeAirPressRqCircuit2 1;
BA_ "SPN" SG_ 2566775550 ServiceBrakeAirPressRqCircuit1 2605;
BA_ "SigType" SG_ 2566775550 ServiceBrakeAirPressRqCircuit1 1;
BA_ "SPN" SG_ 2566775550 ParkingAnd_OrTrailerAirPressRq 2604;
BA_ "SigType" SG_ 2566775550 ParkingAnd_OrTrailerAirPressRq 1;
BA_ "SPN" SG_ 2566775550 PneumaticSupplyPressRq 2603;
BA_ "SigType" SG_ 2566775550 PneumaticSupplyPressRq 1;
BA_ "SPN" SG_ 2566775343 AirSuspensionSupplyPressRq 2608;
BA_ "SigType" SG_ 2566775343 AirSuspensionSupplyPressRq 1;
BA_ "SPN" SG_ 2566775343 AuxEquipmentSupplyPressRq 2607;
BA_ "SigType" SG_ 2566775343 AuxEquipmentSupplyPressRq 1;
BA_ "SPN" SG_ 2566775343 ServiceBrakeAirPressRqCircuit2 2606;
BA_ "SigType" SG_ 2566775343 ServiceBrakeAirPressRqCircuit2 1;
BA_ "SPN" SG_ 2566775343 ServiceBrakeAirPressRqCircuit1 2605;
BA_ "SigType" SG_ 2566775343 ServiceBrakeAirPressRqCircuit1 1;
BA_ "SPN" SG_ 2566775343 ParkingAnd_OrTrailerAirPressRq 2604;
BA_ "SigType" SG_ 2566775343 ParkingAnd_OrTrailerAirPressRq 1;
BA_ "SPN" SG_ 2566775343 PneumaticSupplyPressRq 2603;
BA_ "SigType" SG_ 2566775343 PneumaticSupplyPressRq 1;
BA_ "SPN" SG_ 2566819838 EngExtlShutdownAirSupplyPress 1320;
BA_ "SigType" SG_ 2566819838 EngExtlShutdownAirSupplyPress 1;
BA_ "SPN" SG_ 2566839038 NmbrOfSftwrIdentificationFields 965;
BA_ "SigType" SG_ 2566839038 NmbrOfSftwrIdentificationFields 1;
BA_ "SPN" SG_ 2566839038 SoftwareID3 234;
BA_ "SigType" SG_ 2566839038 SoftwareID3 8;
BA_ "SPN" SG_ 2566839038 SoftwareID2 234;
BA_ "SigType" SG_ 2566839038 SoftwareID2 8;
BA_ "SPN" SG_ 2566839038 SoftwareID1 234;
BA_ "SigType" SG_ 2566839038 SoftwareID1 8;
BA_ "SPN" SG_ 2566841598 EngOverspeedTest 2812;
BA_ "SigType" SG_ 2566841598 EngOverspeedTest 4;
BA_ "SPN" SG_ 2566841598 EngAirShutoffCmdStatus 2813;
BA_ "SigType" SG_ 2566841598 EngAirShutoffCmdStatus 4;
BA_ "SPN" SG_ 2566841598 EngAlarmOutputCmdStatus 2814;
BA_ "SigType" SG_ 2566841598 EngAlarmOutputCmdStatus 4;
BA_ "SPN" SG_ 2566841598 EngAlarmAcknowledge 2815;
BA_ "SigType" SG_ 2566841598 EngAlarmAcknowledge 4;
BA_ "SPN" SG_ 2566841598 EngProtectionSystemConfig 1111;
BA_ "SigType" SG_ 2566841598 EngProtectionSystemConfig 4;
BA_ "SPN" SG_ 2566841598 EngProtectionSystemTimerState 1107;
BA_ "SigType" SG_ 2566841598 EngProtectionSystemTimerState 4;
BA_ "SPN" SG_ 2566841598 EngPrtectionSystemTimerOverride 1108;
BA_ "SigType" SG_ 2566841598 EngPrtectionSystemTimerOverride 4;
BA_ "SPN" SG_ 2566841598 EngPrtctnSystmApprchingShutdown 1109;
BA_ "SigType" SG_ 2566841598 EngPrtctnSystmApprchingShutdown 4;
BA_ "SPN" SG_ 2566841598 EngWaitToStartLamp 1081;
BA_ "SigType" SG_ 2566841598 EngWaitToStartLamp 4;
BA_ "SPN" SG_ 2566841598 RefrigerantHighPressSwitch 605;
BA_ "SigType" SG_ 2566841598 RefrigerantHighPressSwitch 4;
BA_ "SPN" SG_ 2566841598 RefrigerantLowPressSwitch 875;
BA_ "SigType" SG_ 2566841598 RefrigerantLowPressSwitch 4;
BA_ "SPN" SG_ 2566841598 A_CHighPressFanSwitch 985;
BA_ "SigType" SG_ 2566841598 A_CHighPressFanSwitch 4;
BA_ "SPN" SG_ 2566841598 EngIdleShutdownTimerFunction 591;
BA_ "SigType" SG_ 2566841598 EngIdleShutdownTimerFunction 4;
BA_ "SPN" SG_ 2566841598 EngIdleShutdownTimerState 590;
BA_ "SigType" SG_ 2566841598 EngIdleShutdownTimerState 4;
BA_ "SPN" SG_ 2566841598 EngIdleShutdownTimerOverride 592;
BA_ "SigType" SG_ 2566841598 EngIdleShutdownTimerOverride 4;
BA_ "SPN" SG_ 2566841598 EngIdleShutdownDriverAlertMode 594;
BA_ "SigType" SG_ 2566841598 EngIdleShutdownDriverAlertMode 4;
BA_ "SPN" SG_ 2566841598 PTOShutdownHasShutdownEng 5404;
BA_ "SigType" SG_ 2566841598 PTOShutdownHasShutdownEng 4;
BA_ "SPN" SG_ 2566841598 EngPrtctnSystmHasShutdownEngine 1110;
BA_ "SigType" SG_ 2566841598 EngPrtctnSystmHasShutdownEngine 4;
BA_ "SPN" SG_ 2566841598 EngIdlShutdownHasShutdownEngine 593;
BA_ "SigType" SG_ 2566841598 EngIdlShutdownHasShutdownEngine 4;
BA_ "SPN" SG_ 2566841598 EngAirShutoffStatus 3667;
BA_ "SigType" SG_ 2566841598 EngAirShutoffStatus 4;
BA_ "SPN" SG_ 2566832382 ServiceComponentIdentificationB 912;
BA_ "SigType" SG_ 2566832382 ServiceComponentIdentificationB 1;
BA_ "SPN" SG_ 2566832382 ServiceComponentIdentificationA 911;
BA_ "SigType" SG_ 2566832382 ServiceComponentIdentificationA 1;
BA_ "SPN" SG_ 2566832382 SrvceDelay_OperationalTimeBased 916;
BA_ "SigType" SG_ 2566832382 SrvceDelay_OperationalTimeBased 1;
BA_ "SPN" SG_ 2566832382 ServiceDelay_CalendarTimeBased 915;
BA_ "SigType" SG_ 2566832382 ServiceDelay_CalendarTimeBased 1;
BA_ "SPN" SG_ 2566832382 ServiceDistance 914;
BA_ "SigType" SG_ 2566832382 ServiceDistance 1;
BA_ "SPN" SG_ 2566832382 ServiceComponentIdentification 1584;
BA_ "SigType" SG_ 2566832382 ServiceComponentIdentification 1;
BA_ "SPN" SG_ 2633928446 TimeSinceLastService 1350;
BA_ "SigType" SG_ 2633928446 TimeSinceLastService 1;
BA_ "SPN" SG_ 2633928446 ServiceComponentIdentification 1584;
BA_ "SigType" SG_ 2633928446 ServiceComponentIdentification 1;
BA_ "SPN" SG_ 2566804478 MaxContinuousRetarderTorque 1782;
BA_ "SigType" SG_ 2566804478 MaxContinuousRetarderTorque 1;
BA_ "SPN" SG_ 2566804478 MinContinuousRetarderSpeed 1781;
BA_ "SigType" SG_ 2566804478 MinContinuousRetarderSpeed 1;
BA_ "SPN" SG_ 2566804478 MaxContinuousRetarderSpeed 1780;
BA_ "SigType" SG_ 2566804478 MaxContinuousRetarderSpeed 1;
BA_ "SPN" SG_ 2566804478 MinContinuousRetarderTorque 1783;
BA_ "SigType" SG_ 2566804478 MinContinuousRetarderTorque 1;
BA_ "SPN" SG_ 2566804478 LwLmtThrshldFrMxTrqFromRetarder 1778;
BA_ "SigType" SG_ 2566804478 LwLmtThrshldFrMxTrqFromRetarder 1;
BA_ "SPN" SG_ 2566804478 LwLmtThrshldFrMxRPMFromRetarder 1776;
BA_ "SigType" SG_ 2566804478 LwLmtThrshldFrMxRPMFromRetarder 1;
BA_ "SPN" SG_ 2566804478 HghLmtThrshldFrMnCntnsTrqFrmRtrd 1779;
BA_ "SigType" SG_ 2566804478 HghLmtThrshldFrMnCntnsTrqFrmRtrd 1;
BA_ "SystemSignalLongSymbol" SG_ 2566804478 HghLmtThrshldFrMnCntnsTrqFrmRtrd "HghLmtThrshldFrMnCntnsTrqFrmRtrdr";
BA_ "SPN" SG_ 2566804478 HghLmtThrshldFrMnCntnsRPMFrmRtrd 1777;
BA_ "SigType" SG_ 2566804478 HghLmtThrshldFrMnCntnsRPMFrmRtrd 1;
BA_ "SystemSignalLongSymbol" SG_ 2566804478 HghLmtThrshldFrMnCntnsRPMFrmRtrd "HghLmtThrshldFrMnCntnsRPMFrmRtrdr";
BA_ "SPN" SG_ 2566847486 DrvlneRetarderOverheatIndicator 5346;
BA_ "SigType" SG_ 2566847486 DrvlneRetarderOverheatIndicator 4;
BA_ "SPN" SG_ 2566847486 HydRetarderOilTemp 120;
BA_ "SigType" SG_ 2566847486 HydRetarderOilTemp 1;
BA_ "SPN" SG_ 2566847486 HydRetarderPress 119;
BA_ "SigType" SG_ 2566847486 HydRetarderPress 1;
BA_ "SPN" SG_ 2566847248 DrvlneRetarderOverheatIndicator 5346;
BA_ "SigType" SG_ 2566847248 DrvlneRetarderOverheatIndicator 4;
BA_ "SPN" SG_ 2566847248 HydRetarderOilTemp 120;
BA_ "SigType" SG_ 2566847248 HydRetarderOilTemp 1;
BA_ "SPN" SG_ 2566847248 HydRetarderPress 119;
BA_ "SigType" SG_ 2566847248 HydRetarderPress 1;
BA_ "SPN" SG_ 2631859966 EngBuildHoursReset 1211;
BA_ "SigType" SG_ 2631859966 EngBuildHoursReset 4;
BA_ "SPN" SG_ 2631859966 TripGroup2Proprietary 989;
BA_ "SigType" SG_ 2631859966 TripGroup2Proprietary 4;
BA_ "SPN" SG_ 2631859966 TripGroup1 988;
BA_ "SigType" SG_ 2631859966 TripGroup1 4;
BA_ "SPN" SG_ 2631859966 SteerStraightAheadPosReset 3600;
BA_ "SigType" SG_ 2631859966 SteerStraightAheadPosReset 4;
BA_ "SPN" SG_ 2631859966 ServiceComponentIdentification 1584;
BA_ "SigType" SG_ 2631859966 ServiceComponentIdentification 1;
BA_ "SPN" SG_ 2631859966 ServiceComponentIdentificationC 1584;
BA_ "SigType" SG_ 2631859966 ServiceComponentIdentificationC 1;
BA_ "SPN" SG_ 2566840830 PercentTorqueAtPeakTorquePoint5 555;
BA_ "SigType" SG_ 2566840830 PercentTorqueAtPeakTorquePoint5 1;
BA_ "SPN" SG_ 2566840830 ReferenceRetarderTorque 556;
BA_ "SigType" SG_ 2566840830 ReferenceRetarderTorque 1;
BA_ "SPN" SG_ 2566840830 RetarderSpeedAtPeakTorquePoint5 547;
BA_ "SigType" SG_ 2566840830 RetarderSpeedAtPeakTorquePoint5 1;
BA_ "SPN" SG_ 2566840830 PercentTorqueAtPoint4 554;
BA_ "SigType" SG_ 2566840830 PercentTorqueAtPoint4 1;
BA_ "SPN" SG_ 2566840830 RetarderSpeedAtPoint4 550;
BA_ "SigType" SG_ 2566840830 RetarderSpeedAtPoint4 1;
BA_ "SPN" SG_ 2566840830 PercentTorqueAtPoint3 553;
BA_ "SigType" SG_ 2566840830 PercentTorqueAtPoint3 1;
BA_ "SPN" SG_ 2566840830 RetarderSpeedAtPoint3 549;
BA_ "SigType" SG_ 2566840830 RetarderSpeedAtPoint3 1;
BA_ "SPN" SG_ 2566840830 PercentTorqueAtMaxSpeedPoint2 552;
BA_ "SigType" SG_ 2566840830 PercentTorqueAtMaxSpeedPoint2 1;
BA_ "SPN" SG_ 2566840830 MaxRetarderSpeedPoint2 548;
BA_ "SigType" SG_ 2566840830 MaxRetarderSpeedPoint2 1;
BA_ "SPN" SG_ 2566840830 PercentTorqueAtIdlePoint1 551;
BA_ "SigType" SG_ 2566840830 PercentTorqueAtIdlePoint1 1;
BA_ "SPN" SG_ 2566840830 RetarderSpeedAtIdlePoint1 546;
BA_ "SigType" SG_ 2566840830 RetarderSpeedAtIdlePoint1 1;
BA_ "SPN" SG_ 2566840830 RetarderCtrlMethod 557;
BA_ "SigType" SG_ 2566840830 RetarderCtrlMethod 1;
BA_ "SPN" SG_ 2566840830 RetarderLocation 902;
BA_ "SigType" SG_ 2566840830 RetarderLocation 4;
BA_ "SPN" SG_ 2566840830 RetarderType 901;
BA_ "SigType" SG_ 2566840830 RetarderType 4;
BA_ "SPN" SG_ 2633930238 EngOperationTimeSinceRebuild 1193;
BA_ "SigType" SG_ 2633930238 EngOperationTimeSinceRebuild 1;
BA_ "SPN" SG_ 2566844670 PowerTakeoffSetSpeed 187;
BA_ "SigType" SG_ 2566844670 PowerTakeoffSetSpeed 1;
BA_ "SPN" SG_ 2566844670 PowerTakeoffSpeed 186;
BA_ "SigType" SG_ 2566844670 PowerTakeoffSpeed 1;
BA_ "SPN" SG_ 2566844670 PowerTakeoffOilTemp 90;
BA_ "SigType" SG_ 2566844670 PowerTakeoffOilTemp 1;
BA_ "SPN" SG_ 2566844670 OprtrEngPTOGvrnrMmrySlectSwitch 2897;
BA_ "SigType" SG_ 2566844670 OprtrEngPTOGvrnrMmrySlectSwitch 4;
BA_ "SPN" SG_ 2566844670 EngRmtPTOGvrnrVrblSpdCtrlSwitch 978;
BA_ "SigType" SG_ 2566844670 EngRmtPTOGvrnrVrblSpdCtrlSwitch 4;
BA_ "SPN" SG_ 2566844670 EngRmtPTOGvrnrPrprgrmmdSpdCtrlSw 979;
BA_ "SigType" SG_ 2566844670 EngRmtPTOGvrnrPrprgrmmdSpdCtrlSw 4;
BA_ "SystemSignalLongSymbol" SG_ 2566844670 EngRmtPTOGvrnrPrprgrmmdSpdCtrlSw "EngRmtPTOGvrnrPrprgrmmdSpdCtrlSwtch";
BA_ "SPN" SG_ 2566844670 EngPTOGvrnrCst_DecelerateSwitch 983;
BA_ "SigType" SG_ 2566844670 EngPTOGvrnrCst_DecelerateSwitch 4;
BA_ "SPN" SG_ 2566844670 EngPTOGovernorSetSwitch 984;
BA_ "SigType" SG_ 2566844670 EngPTOGovernorSetSwitch 4;
BA_ "SPN" SG_ 2566844670 EngPTOGovernorResumeSwitch 982;
BA_ "SigType" SG_ 2566844670 EngPTOGovernorResumeSwitch 4;
BA_ "SPN" SG_ 2566844670 EngPTOGovernorEnableSwitch 980;
BA_ "SigType" SG_ 2566844670 EngPTOGovernorEnableSwitch 4;
BA_ "SPN" SG_ 2566844670 EngPTOGovernorAccelerateSwitch 981;
BA_ "SigType" SG_ 2566844670 EngPTOGovernorAccelerateSwitch 4;
BA_ "SPN" SG_ 2566844670 RmtPTOPrprgrmmdSpeedCtrlSwitch2 3447;
BA_ "SigType" SG_ 2566844670 RmtPTOPrprgrmmdSpeedCtrlSwitch2 4;
BA_ "SPN" SG_ 2566844670 AuxInputIgnoreSwitch 3448;
BA_ "SigType" SG_ 2566844670 AuxInputIgnoreSwitch 4;
BA_ "SPN" SG_ 2566844416 PowerTakeoffSetSpeed 187;
BA_ "SigType" SG_ 2566844416 PowerTakeoffSetSpeed 1;
BA_ "SPN" SG_ 2566844416 PowerTakeoffSpeed 186;
BA_ "SigType" SG_ 2566844416 PowerTakeoffSpeed 1;
BA_ "SPN" SG_ 2566844416 PowerTakeoffOilTemp 90;
BA_ "SigType" SG_ 2566844416 PowerTakeoffOilTemp 1;
BA_ "SPN" SG_ 2566844416 OprtrEngPTOGvrnrMmrySlectSwitch 2897;
BA_ "SigType" SG_ 2566844416 OprtrEngPTOGvrnrMmrySlectSwitch 4;
BA_ "SPN" SG_ 2566844416 EngRmtPTOGvrnrVrblSpdCtrlSwitch 978;
BA_ "SigType" SG_ 2566844416 EngRmtPTOGvrnrVrblSpdCtrlSwitch 4;
BA_ "SPN" SG_ 2566844416 EngRmtPTOGvrnrPrprgrmmdSpdCtrlSw 979;
BA_ "SigType" SG_ 2566844416 EngRmtPTOGvrnrPrprgrmmdSpdCtrlSw 4;
BA_ "SystemSignalLongSymbol" SG_ 2566844416 EngRmtPTOGvrnrPrprgrmmdSpdCtrlSw "EngRmtPTOGvrnrPrprgrmmdSpdCtrlSwtch";
BA_ "SPN" SG_ 2566844416 EngPTOGvrnrCst_DecelerateSwitch 983;
BA_ "SigType" SG_ 2566844416 EngPTOGvrnrCst_DecelerateSwitch 4;
BA_ "SPN" SG_ 2566844416 EngPTOGovernorSetSwitch 984;
BA_ "SigType" SG_ 2566844416 EngPTOGovernorSetSwitch 4;
BA_ "SPN" SG_ 2566844416 EngPTOGovernorResumeSwitch 982;
BA_ "SigType" SG_ 2566844416 EngPTOGovernorResumeSwitch 4;
BA_ "SPN" SG_ 2566844416 EngPTOGovernorEnableSwitch 980;
BA_ "SigType" SG_ 2566844416 EngPTOGovernorEnableSwitch 4;
BA_ "SPN" SG_ 2566844416 EngPTOGovernorAccelerateSwitch 981;
BA_ "SigType" SG_ 2566844416 EngPTOGovernorAccelerateSwitch 4;
BA_ "SPN" SG_ 2566844416 RmtPTOPrprgrmmdSpeedCtrlSwitch2 3447;
BA_ "SigType" SG_ 2566844416 RmtPTOPrprgrmmdSpeedCtrlSwitch2 4;
BA_ "SPN" SG_ 2566844416 AuxInputIgnoreSwitch 3448;
BA_ "SigType" SG_ 2566844416 AuxInputIgnoreSwitch 4;
BA_ "SPN" SG_ 2566770174 RearWasherFunction 2868;
BA_ "SPN" SG_ 2566770174 FrontOperatorWasherSwitch 2866;
BA_ "SPN" SG_ 2566770174 FrontNonoperatorWasherSwitch 2867;
BA_ "SPN" SG_ 2566770174 RearWiperDelayCtrl 2871;
BA_ "SigType" SG_ 2566770174 RearWiperDelayCtrl 1;
BA_ "SPN" SG_ 2566770174 FrontNonoperatorWiperDelayCtrl 2870;
BA_ "SigType" SG_ 2566770174 FrontNonoperatorWiperDelayCtrl 1;
BA_ "SPN" SG_ 2566770174 FrontOperatorWiperDelayCtrl 2869;
BA_ "SigType" SG_ 2566770174 FrontOperatorWiperDelayCtrl 1;
BA_ "SPN" SG_ 2566770174 RearWiperSwitch 2865;
BA_ "SigType" SG_ 2566770174 RearWiperSwitch 4;
BA_ "SPN" SG_ 2566770174 FrontOperatorWiperSwitch 2863;
BA_ "SigType" SG_ 2566770174 FrontOperatorWiperSwitch 4;
BA_ "SPN" SG_ 2566770174 FrontNonoperatorWiperSwitch 2864;
BA_ "SigType" SG_ 2566770174 FrontNonoperatorWiperSwitch 4;
BA_ "SPN" SG_ 2566769662 EngAltDroopAuxInputSelect 2885;
BA_ "SigType" SG_ 2566769662 EngAltDroopAuxInputSelect 4;
BA_ "SPN" SG_ 2566769662 EngAltDroopRemoteAccelSelect 2886;
BA_ "SigType" SG_ 2566769662 EngAltDroopRemoteAccelSelect 4;
BA_ "SPN" SG_ 2566769662 EngAltDroopAccel2Select 2879;
BA_ "SigType" SG_ 2566769662 EngAltDroopAccel2Select 4;
BA_ "SPN" SG_ 2566769662 EngAltDroopAccel1Select 2881;
BA_ "SigType" SG_ 2566769662 EngAltDroopAccel1Select 4;
BA_ "SPN" SG_ 2566769662 EngAltRatingSelect 2882;
BA_ "SigType" SG_ 2566769662 EngAltRatingSelect 1;
BA_ "SPN" SG_ 2566769662 EngAltLowIdleSwitch 2883;
BA_ "SigType" SG_ 2566769662 EngAltLowIdleSwitch 4;
BA_ "SPN" SG_ 2566769662 EngSynchronizationSwitch 1377;
BA_ "SigType" SG_ 2566769662 EngSynchronizationSwitch 4;
BA_ "SPN" SG_ 2566769662 EngAuxGovernorSwitch 2884;
BA_ "SigType" SG_ 2566769662 EngAuxGovernorSwitch 4;
BA_ "SPN" SG_ 2566768638 EngAltDroopAuxInputSelectState 2895;
BA_ "SigType" SG_ 2566768638 EngAltDroopAuxInputSelectState 4;
BA_ "SPN" SG_ 2566768638 EngAltDrpRemoteAccelSelectState 2894;
BA_ "SigType" SG_ 2566768638 EngAltDrpRemoteAccelSelectState 4;
BA_ "SPN" SG_ 2566768638 EngAltDroopAccel2SelectState 2893;
BA_ "SigType" SG_ 2566768638 EngAltDroopAccel2SelectState 4;
BA_ "SPN" SG_ 2566768638 EngAltDroopAccel1SelectState 2889;
BA_ "SigType" SG_ 2566768638 EngAltDroopAccel1SelectState 4;
BA_ "SPN" SG_ 2566768638 EngAltRatingSelectState 2888;
BA_ "SigType" SG_ 2566768638 EngAltRatingSelectState 1;
BA_ "SPN" SG_ 2566768638 EngAltLowIdleSelectState 2891;
BA_ "SigType" SG_ 2566768638 EngAltLowIdleSelectState 4;
BA_ "SPN" SG_ 2566768638 EngMultiUnitSyncState 2890;
BA_ "SigType" SG_ 2566768638 EngMultiUnitSyncState 4;
BA_ "SPN" SG_ 2566768638 EngAuxGovernorState 2896;
BA_ "SigType" SG_ 2566768638 EngAuxGovernorState 4;
BA_ "SPN" SG_ 2365443326 OprtrsDesiredDelayedLampOffTime 2877;
BA_ "SigType" SG_ 2365443326 OprtrsDesiredDelayedLampOffTime 1;
BA_ "SPN" SG_ 2365443326 OperatorsDesiredBacklight 2878;
BA_ "SigType" SG_ 2365443326 OperatorsDesiredBacklight 1;
BA_ "SPN" SG_ 2365443326 HighLowBeamSwitch 2874;
BA_ "SigType" SG_ 2365443326 HighLowBeamSwitch 4;
BA_ "SPN" SG_ 2365443326 HazardLightSwitch 2875;
BA_ "SigType" SG_ 2365443326 HazardLightSwitch 4;
BA_ "SPN" SG_ 2365443326 TurnSignalSwitch 2876;
BA_ "SigType" SG_ 2365443326 TurnSignalSwitch 4;
BA_ "SPN" SG_ 2365443326 MainLightSwitch 2872;
BA_ "SigType" SG_ 2365443326 MainLightSwitch 4;
BA_ "SPN" SG_ 2365443326 WorkLightSwitch 2873;
BA_ "SigType" SG_ 2365443326 WorkLightSwitch 4;
BA_ "SPN" SG_ 2566776318 AppliedVehicleSpeedLimit 2595;
BA_ "SigType" SG_ 2566776318 AppliedVehicleSpeedLimit 1;
BA_ "SPN" SG_ 2566776318 MaxVehicleSpeedLimit7 2594;
BA_ "SigType" SG_ 2566776318 MaxVehicleSpeedLimit7 1;
BA_ "SPN" SG_ 2566776318 MaxVehicleSpeedLimit6 2593;
BA_ "SigType" SG_ 2566776318 MaxVehicleSpeedLimit6 1;
BA_ "SPN" SG_ 2566776318 MaxVehicleSpeedLimit5 2592;
BA_ "SigType" SG_ 2566776318 MaxVehicleSpeedLimit5 1;
BA_ "SPN" SG_ 2566776318 MaxVehicleSpeedLimit4 2591;
BA_ "SigType" SG_ 2566776318 MaxVehicleSpeedLimit4 1;
BA_ "SPN" SG_ 2566776318 MaxVehicleSpeedLimit3 2590;
BA_ "SigType" SG_ 2566776318 MaxVehicleSpeedLimit3 1;
BA_ "SPN" SG_ 2566776318 MaxVehicleSpeedLimit2 2589;
BA_ "SigType" SG_ 2566776318 MaxVehicleSpeedLimit2 1;
BA_ "SPN" SG_ 2566776318 MaxVehicleSpeedLimit1 2588;
BA_ "SigType" SG_ 2566776318 MaxVehicleSpeedLimit1 1;
BA_ "SPN" SG_ 2566802686 OprtrsBlckOutIntensitySelection 1844;
BA_ "SigType" SG_ 2566802686 OprtrsBlckOutIntensitySelection 1;
BA_ "SPN" SG_ 2566802686 BlackOutWorkLampSelect 1842;
BA_ "SigType" SG_ 2566802686 BlackOutWorkLampSelect 4;
BA_ "SPN" SG_ 2566802686 NightVisionIlluminatorSelect 1843;
BA_ "SigType" SG_ 2566802686 NightVisionIlluminatorSelect 4;
BA_ "SPN" SG_ 2566802686 BlackOutBrake_StopLampSelect 1841;
BA_ "SigType" SG_ 2566802686 BlackOutBrake_StopLampSelect 4;
BA_ "SPN" SG_ 2566802686 ConvoyDrivingLampSelect 1837;
BA_ "SigType" SG_ 2566802686 ConvoyDrivingLampSelect 4;
BA_ "SPN" SG_ 2566802686 ConvoyLampSelect 1838;
BA_ "SigType" SG_ 2566802686 ConvoyLampSelect 4;
BA_ "SPN" SG_ 2566802686 FrontBlackOutMarkerLampSelect 1839;
BA_ "SigType" SG_ 2566802686 FrontBlackOutMarkerLampSelect 4;
BA_ "SPN" SG_ 2566802686 RearBlackOutMarkerSelect 1840;
BA_ "SigType" SG_ 2566802686 RearBlackOutMarkerSelect 4;
BA_ "SPN" SG_ 2566774014 SlowVesselModeStatus 2617;
BA_ "SigType" SG_ 2566774014 SlowVesselModeStatus 4;
BA_ "SPN" SG_ 2566774014 TrollingModeStatus 2616;
BA_ "SigType" SG_ 2566774014 TrollingModeStatus 4;
BA_ "SPN" SG_ 2566774014 EngThrttlSynchrnztionModeStatus 2615;
BA_ "SigType" SG_ 2566774014 EngThrttlSynchrnztionModeStatus 4;
BA_ "SPN" SG_ 2566823166 EngMainBearing11Temp 1167;
BA_ "SigType" SG_ 2566823166 EngMainBearing11Temp 1;
BA_ "SPN" SG_ 2566823166 EngMainBearing10Temp 1166;
BA_ "SigType" SG_ 2566823166 EngMainBearing10Temp 1;
BA_ "SPN" SG_ 2566823166 EngMainBearing9Temp 1165;
BA_ "SigType" SG_ 2566823166 EngMainBearing9Temp 1;
BA_ "SPN" SG_ 2566823422 EngMainBearing8Temp 1164;
BA_ "SigType" SG_ 2566823422 EngMainBearing8Temp 1;
BA_ "SPN" SG_ 2566823422 EngMainBearing7Temp 1163;
BA_ "SigType" SG_ 2566823422 EngMainBearing7Temp 1;
BA_ "SPN" SG_ 2566823422 EngMainBearing6Temp 1162;
BA_ "SigType" SG_ 2566823422 EngMainBearing6Temp 1;
BA_ "SPN" SG_ 2566823422 EngMainBearing5Temp 1161;
BA_ "SigType" SG_ 2566823422 EngMainBearing5Temp 1;
BA_ "SPN" SG_ 2566823678 EngMainBearing4Temp 1160;
BA_ "SigType" SG_ 2566823678 EngMainBearing4Temp 1;
BA_ "SPN" SG_ 2566823678 EngMainBearing3Temp 1159;
BA_ "SigType" SG_ 2566823678 EngMainBearing3Temp 1;
BA_ "SPN" SG_ 2566823678 EngMainBearing2Temp 1158;
BA_ "SigType" SG_ 2566823678 EngMainBearing2Temp 1;
BA_ "SPN" SG_ 2566823678 EngMainBearing1Temp 1157;
BA_ "SigType" SG_ 2566823678 EngMainBearing1Temp 1;
BA_ "SPN" SG_ 2432595710 DisplayDeadbands 2577;
BA_ "SigType" SG_ 2432595710 DisplayDeadbands 4;
BA_ "SPN" SG_ 2432595710 LEDPatternCtrl 2578;
BA_ "SigType" SG_ 2432595710 LEDPatternCtrl 4;
BA_ "SPN" SG_ 2432595710 LEDDisplayDeadbandCtrl 1806;
BA_ "SigType" SG_ 2432595710 LEDDisplayDeadbandCtrl 4;
BA_ "SPN" SG_ 2432595710 LEDDisplayModeCtrl 1805;
BA_ "SigType" SG_ 2432595710 LEDDisplayModeCtrl 4;
BA_ "SPN" SG_ 2432595710 LEDDisplayData1 1573;
BA_ "SigType" SG_ 2432595710 LEDDisplayData1 1;
BA_ "SPN" SG_ 2365486590 LaserStrikeDataLatency 2793;
BA_ "SigType" SG_ 2365486590 LaserStrikeDataLatency 1;
BA_ "SPN" SG_ 2365486590 LaserReceiverType 2576;
BA_ "SigType" SG_ 2365486590 LaserReceiverType 1;
BA_ "SPN" SG_ 2365486590 LaserStrikeVerticalDeviation 1574;
BA_ "SigType" SG_ 2365486590 LaserStrikeVerticalDeviation 1;
BA_ "SPN" SG_ 2365486590 AbsLaserStrikePos 2794;
BA_ "SigType" SG_ 2365486590 AbsLaserStrikePos 1;
BA_ "SPN" SG_ 2365485566 LaserTracerInformation 1583;
BA_ "SigType" SG_ 2365485566 LaserTracerInformation 1;
BA_ "SPN" SG_ 2365485566 LEDDisplayData2 1582;
BA_ "SigType" SG_ 2365485566 LEDDisplayData2 1;
BA_ "SPN" SG_ 2365485566 LaserTracerHorizontalDeviation 1581;
BA_ "SigType" SG_ 2365485566 LaserTracerHorizontalDeviation 1;
BA_ "SPN" SG_ 2365485566 LaserTracerVerticalDistance 1580;
BA_ "SigType" SG_ 2365485566 LaserTracerVerticalDistance 1;
BA_ "SPN" SG_ 2365485566 LaserTracerTargetDeviation 1579;
BA_ "SigType" SG_ 2365485566 LaserTracerTargetDeviation 1;
BA_ "SPN" SG_ 2633939454 TripCruiseFuelUsed 1005;
BA_ "SigType" SG_ 2633939454 TripCruiseFuelUsed 1;
BA_ "SPN" SG_ 2633939454 TripVehicleIdleFuelUsed 1004;
BA_ "SigType" SG_ 2633939454 TripVehicleIdleFuelUsed 1;
BA_ "SPN" SG_ 2633939454 TripDriveFuelUsed 1001;
BA_ "SigType" SG_ 2633939454 TripDriveFuelUsed 1;
BA_ "SPN" SG_ 2633939454 TrpPTOGovernorNonmovingFuelUsed 1003;
BA_ "SigType" SG_ 2633939454 TrpPTOGovernorNonmovingFuelUsed 1;
BA_ "SPN" SG_ 2633939454 TripPTOGovernorMovingFuelUsed 1002;
BA_ "SigType" SG_ 2633939454 TripPTOGovernorMovingFuelUsed 1;
BA_ "SPN" SG_ 2633939454 TripDriveFuelEconomy 1006;
BA_ "SigType" SG_ 2633939454 TripDriveFuelEconomy 1;
BA_ "SPN" SG_ 2365486334 BldHeightSetPointHighResolution 1759;
BA_ "SigType" SG_ 2365486334 BldHeightSetPointHighResolution 1;
BA_ "SPN" SG_ 2365486334 ModifyLevelingSystemSetPoint 1575;
BA_ "SigType" SG_ 2365486334 ModifyLevelingSystemSetPoint 1;
BA_ "SPN" SG_ 2364542462 SdshftDsrdBldOffsetOperatorCtrl 3339;
BA_ "SigType" SG_ 2364542462 SdshftDsrdBldOffsetOperatorCtrl 4;
BA_ "SPN" SG_ 2364542462 SdshftBldCtrlMdeOperatorControl 3338;
BA_ "SigType" SG_ 2364542462 SdshftBldCtrlMdeOperatorControl 4;
BA_ "SPN" SG_ 2364542462 RghtDsrdBladeOffsetOperatorCtrl 3337;
BA_ "SigType" SG_ 2364542462 RghtDsrdBladeOffsetOperatorCtrl 4;
BA_ "SPN" SG_ 2364542462 RghtBldeCtrlModeOperatorControl 3335;
BA_ "SigType" SG_ 2364542462 RghtBldeCtrlModeOperatorControl 4;
BA_ "SPN" SG_ 2364542462 LftDsredBladeOffsetOperatorCtrl 3336;
BA_ "SigType" SG_ 2364542462 LftDsredBladeOffsetOperatorCtrl 4;
BA_ "SPN" SG_ 2364542462 LftBladeCtrlModeOperatorControl 3334;
BA_ "SigType" SG_ 2364542462 LftBladeCtrlModeOperatorControl 4;
BA_ "SPN" SG_ 2364542462 BladeAutoModeCmd 3158;
BA_ "SigType" SG_ 2364542462 BladeAutoModeCmd 4;
BA_ "SPN" SG_ 2364542462 DesiredGradeOffsetSwitch 3157;
BA_ "SigType" SG_ 2364542462 DesiredGradeOffsetSwitch 4;
BA_ "SPN" SG_ 2364542462 BladeCtrlModeSwitch 3156;
BA_ "SigType" SG_ 2364542462 BladeCtrlModeSwitch 4;
BA_ "SPN" SG_ 2364542462 StElvtnSnsor2ReferenceElevation 5406;
BA_ "SigType" SG_ 2364542462 StElvtnSnsor2ReferenceElevation 4;
BA_ "SPN" SG_ 2364542462 StElvtnSnsor1ReferenceElevation 5405;
BA_ "SigType" SG_ 2364542462 StElvtnSnsor1ReferenceElevation 4;
BA_ "SPN" SG_ 2365486078 MastPos 1576;
BA_ "SigType" SG_ 2365486078 MastPos 1;
BA_ "SPN" SG_ 2633937918 TotalEngPTOGovernorFuelUsed 1028;
BA_ "SigType" SG_ 2633937918 TotalEngPTOGovernorFuelUsed 1;
BA_ "SPN" SG_ 2633937918 TripAverageFuelRate 1029;
BA_ "SigType" SG_ 2633937918 TripAverageFuelRate 1;
BA_ "SPN" SG_ 2633937918 FlexibleFuelPercentage 5458;
BA_ "SigType" SG_ 2633937918 FlexibleFuelPercentage 1;
BA_ "SPN" SG_ 2566845182 EngAverageFuelEconomy 185;
BA_ "SigType" SG_ 2566845182 EngAverageFuelEconomy 1;
BA_ "SPN" SG_ 2566845182 EngInstantaneousFuelEconomy 184;
BA_ "SigType" SG_ 2566845182 EngInstantaneousFuelEconomy 1;
BA_ "SPN" SG_ 2566845182 EngFuelRate 183;
BA_ "SigType" SG_ 2566845182 EngFuelRate 1;
BA_ "SPN" SG_ 2566845182 EngThrottleValve2Pos 3673;
BA_ "SigType" SG_ 2566845182 EngThrottleValve2Pos 1;
BA_ "SPN" SG_ 2566845182 EngThrottleValve1Pos 51;
BA_ "SigType" SG_ 2566845182 EngThrottleValve1Pos 1;
BA_ "SPN" SG_ 2566844928 EngAverageFuelEconomy 185;
BA_ "SigType" SG_ 2566844928 EngAverageFuelEconomy 1;
BA_ "SPN" SG_ 2566844928 EngInstantaneousFuelEconomy 184;
BA_ "SigType" SG_ 2566844928 EngInstantaneousFuelEconomy 1;
BA_ "SPN" SG_ 2566844928 EngFuelRate 183;
BA_ "SigType" SG_ 2566844928 EngFuelRate 1;
BA_ "SPN" SG_ 2566844928 EngThrottleValve2Pos 3673;
BA_ "SigType" SG_ 2566844928 EngThrottleValve2Pos 1;
BA_ "SPN" SG_ 2566844928 EngThrottleValve1Pos 51;
BA_ "SigType" SG_ 2566844928 EngThrottleValve1Pos 1;
BA_ "SPN" SG_ 2566842878 EngTotalFuelUsed 250;
BA_ "SigType" SG_ 2566842878 EngTotalFuelUsed 1;
BA_ "SPN" SG_ 2566842878 EngTripFuel 182;
BA_ "SigType" SG_ 2566842878 EngTripFuel 1;
BA_ "SPN" SG_ 2633883646 FrontWheelDriveActuatorStatus 2612;
BA_ "SigType" SG_ 2633883646 FrontWheelDriveActuatorStatus 4;
BA_ "SPN" SG_ 2633880062 FMSstandardSWversionSupported 2806;
BA_ "SigType" SG_ 2633880062 FMSstandardSWversionSupported 1;
BA_ "SPN" SG_ 2633880062 FMSstandardRqsSupported 2805;
BA_ "SigType" SG_ 2633880062 FMSstandardRqsSupported 4;
BA_ "SPN" SG_ 2633880062 FMSstandardDiagnosticsSupported 2804;
BA_ "SigType" SG_ 2633880062 FMSstandardDiagnosticsSupported 4;
BA_ "SPN" SG_ 2566806526 LnDprtureIndicationEnableStatus 1702;
BA_ "SigType" SG_ 2566806526 LnDprtureIndicationEnableStatus 4;
BA_ "SPN" SG_ 2566806526 LaneTrackingStatusLeftSide 1710;
BA_ "SigType" SG_ 2566806526 LaneTrackingStatusLeftSide 4;
BA_ "SPN" SG_ 2566806526 LaneTrackingStatusRightSide 1711;
BA_ "SigType" SG_ 2566806526 LaneTrackingStatusRightSide 4;
BA_ "SPN" SG_ 2431649790 LaneDepartureImminentLeftSide 1700;
BA_ "SigType" SG_ 2431649790 LaneDepartureImminentLeftSide 4;
BA_ "SPN" SG_ 2431649790 LaneDepartureImminentRightSide 1701;
BA_ "SigType" SG_ 2431649790 LaneDepartureImminentRightSide 4;
BA_ "SPN" SG_ 2431649790 LaneDepartureRight 3566;
BA_ "SigType" SG_ 2431649790 LaneDepartureRight 4;
BA_ "SPN" SG_ 2431649790 LaneDepartureLeft 3565;
BA_ "SigType" SG_ 2431649790 LaneDepartureLeft 4;
BA_ "SPN" SG_ 2633929214 EngFuelLeakage2 1240;
BA_ "SigType" SG_ 2633929214 EngFuelLeakage2 4;
BA_ "SPN" SG_ 2633929214 EngFuelLeakage1 1239;
BA_ "SigType" SG_ 2633929214 EngFuelLeakage1 4;
BA_ "SPN" SG_ 2566831614 FanSpeed 1639;
BA_ "SigType" SG_ 2566831614 FanSpeed 1;
BA_ "SPN" SG_ 2566831614 FanDriveState 977;
BA_ "SigType" SG_ 2566831614 FanDriveState 4;
BA_ "SPN" SG_ 2566831614 EstPercentFanSpeed 975;
BA_ "SigType" SG_ 2566831614 EstPercentFanSpeed 1;
BA_ "SPN" SG_ 2566831614 HydFanMotorPress 4211;
BA_ "SigType" SG_ 2566831614 HydFanMotorPress 1;
BA_ "SPN" SG_ 2566831614 FanDriveBypassCmdStatus 4212;
BA_ "SigType" SG_ 2566831614 FanDriveBypassCmdStatus 1;
BA_ "SPN" SG_ 2566820094 EngTorqueLimit6AxleInput 1263;
BA_ "SigType" SG_ 2566820094 EngTorqueLimit6AxleInput 1;
BA_ "SPN" SG_ 2566820094 EngTorqueLimit5Switch 1262;
BA_ "SigType" SG_ 2566820094 EngTorqueLimit5Switch 1;
BA_ "SPN" SG_ 2566820094 EngTorqueLimit4Trans 1261;
BA_ "SigType" SG_ 2566820094 EngTorqueLimit4Trans 1;
BA_ "SPN" SG_ 2566820094 EngTorqueLimit3Trans 1260;
BA_ "SigType" SG_ 2566820094 EngTorqueLimit3Trans 1;
BA_ "SPN" SG_ 2566820094 TransGearRatio3 1259;
BA_ "SigType" SG_ 2566820094 TransGearRatio3 1;
BA_ "SPN" SG_ 2566820094 EngTorqueLimit2Trans 1258;
BA_ "SigType" SG_ 2566820094 EngTorqueLimit2Trans 1;
BA_ "SPN" SG_ 2566820094 TransGearRatio2 1257;
BA_ "SigType" SG_ 2566820094 TransGearRatio2 1;
BA_ "SPN" SG_ 2566820094 EngTorqueLimit1Trans 1256;
BA_ "SigType" SG_ 2566820094 EngTorqueLimit1Trans 1;
BA_ "SPN" SG_ 2566820094 TransGearRatio1 1255;
BA_ "SigType" SG_ 2566820094 TransGearRatio1 1;
BA_ "SPN" SG_ 2566820094 EngTorqueLimitFeature 1632;
BA_ "SPN" SG_ 2566820094 TorqueLimitingFeatureStatus 1254;
BA_ "SigType" SG_ 2566820094 TorqueLimitingFeatureStatus 4;
BA_ "SPN" SG_ 2566820094 CalibRecordDurationTime 1253;
BA_ "SigType" SG_ 2566820094 CalibRecordDurationTime 1;
BA_ "SPN" SG_ 2566820094 CalibRecordStartYear 1252;
BA_ "SigType" SG_ 2566820094 CalibRecordStartYear 1;
BA_ "SPN" SG_ 2566820094 CalibRecordStartDay 1251;
BA_ "SigType" SG_ 2566820094 CalibRecordStartDay 1;
BA_ "SPN" SG_ 2566820094 CalibRecordStartMonth 1250;
BA_ "SigType" SG_ 2566820094 CalibRecordStartMonth 1;
BA_ "SPN" SG_ 2566820094 EngPeakTorque2 1249;
BA_ "SigType" SG_ 2566820094 EngPeakTorque2 1;
BA_ "SPN" SG_ 2566820094 EngPeakTorque1 1248;
BA_ "SigType" SG_ 2566820094 EngPeakTorque1 1;
BA_ "SPN" SG_ 2566820094 EngPower 1247;
BA_ "SigType" SG_ 2566820094 EngPower 1;
BA_ "SPN" SG_ 2566820094 NumberOfEngTorqueHistoryRecords 1246;
BA_ "SigType" SG_ 2566820094 NumberOfEngTorqueHistoryRecords 1;
BA_ "SPN" SG_ 2364542206 TransClutch_ConverterInputSpeed 5052;
BA_ "SigType" SG_ 2364542206 TransClutch_ConverterInputSpeed 1;
BA_ "SPN" SG_ 2364542206 TransTorqueConverterRatio 3030;
BA_ "SigType" SG_ 2364542206 TransTorqueConverterRatio 1;
BA_ "SPN" SG_ 2566802174 TrnsRvrseGearShiftInhibitStatus 4261;
BA_ "SigType" SG_ 2566802174 TrnsRvrseGearShiftInhibitStatus 4;
BA_ "SPN" SG_ 2566802174 TrnsCrrntRangeDisplayBlankState 4176;
BA_ "SigType" SG_ 2566802174 TrnsCrrntRangeDisplayBlankState 4;
BA_ "SPN" SG_ 2566802174 TransWarningIndicator 5344;
BA_ "SigType" SG_ 2566802174 TransWarningIndicator 4;
BA_ "SPN" SG_ 2566802174 TransMode8Indicator 4253;
BA_ "SigType" SG_ 2566802174 TransMode8Indicator 4;
BA_ "SPN" SG_ 2566802174 TransMode7Indicator 4252;
BA_ "SigType" SG_ 2566802174 TransMode7Indicator 4;
BA_ "SPN" SG_ 2566802174 TransMode6Indicator 4251;
BA_ "SigType" SG_ 2566802174 TransMode6Indicator 4;
BA_ "SPN" SG_ 2566802174 TransMode5Indicator 4250;
BA_ "SigType" SG_ 2566802174 TransMode5Indicator 4;
BA_ "SPN" SG_ 2566802174 TransRqedGearFeedback 3289;
BA_ "SigType" SG_ 2566802174 TransRqedGearFeedback 1;
BA_ "SPN" SG_ 2566802174 TransMode1Indicator 2536;
BA_ "SigType" SG_ 2566802174 TransMode1Indicator 4;
BA_ "SPN" SG_ 2566802174 TransMode2Indicator 2537;
BA_ "SigType" SG_ 2566802174 TransMode2Indicator 4;
BA_ "SPN" SG_ 2566802174 TransMode3Indicator 2538;
BA_ "SigType" SG_ 2566802174 TransMode3Indicator 4;
BA_ "SPN" SG_ 2566802174 TransMode4Indicator 2539;
BA_ "SigType" SG_ 2566802174 TransMode4Indicator 4;
BA_ "SPN" SG_ 2566802174 TransShiftInhibitIndicator 1851;
BA_ "SigType" SG_ 2566802174 TransShiftInhibitIndicator 4;
BA_ "SPN" SG_ 2566802174 TransEngCrankEnable 2900;
BA_ "SigType" SG_ 2566802174 TransEngCrankEnable 4;
BA_ "SPN" SG_ 2566802174 ActiveShiftConsoleIndicator 2945;
BA_ "SigType" SG_ 2566802174 ActiveShiftConsoleIndicator 4;
BA_ "SPN" SG_ 2566802174 TransReadyForBrakeRelease 3086;
BA_ "SigType" SG_ 2566802174 TransReadyForBrakeRelease 4;
BA_ "SPN" SG_ 2566802174 TransRqedRangeDisplayFlashState 1849;
BA_ "SigType" SG_ 2566802174 TransRqedRangeDisplayFlashState 4;
BA_ "SPN" SG_ 2566802174 TransRqedRangeDisplayBlankState 1850;
BA_ "SigType" SG_ 2566802174 TransRqedRangeDisplayBlankState 4;
BA_ "SPN" SG_ 2566802174 TransServiceIndicator 4178;
BA_ "SigType" SG_ 2566802174 TransServiceIndicator 4;
BA_ "SPN" SG_ 2633935870 ClutchLifeRemaining 2983;
BA_ "SigType" SG_ 2633935870 ClutchLifeRemaining 1;
BA_ "SPN" SG_ 2633935870 LowestPossibleGear 1114;
BA_ "SigType" SG_ 2633935870 LowestPossibleGear 1;
BA_ "SPN" SG_ 2633935870 HighestPossibleGear 1115;
BA_ "SigType" SG_ 2633935870 HighestPossibleGear 1;
BA_ "SPN" SG_ 2633935870 RecommendedGear 1113;
BA_ "SigType" SG_ 2633935870 RecommendedGear 1;
BA_ "SPN" SG_ 2633942014 TransForwardDirectionSwitch 903;
BA_ "SigType" SG_ 2633942014 TransForwardDirectionSwitch 4;
BA_ "SPN" SG_ 2633942014 TransNeutralSwitch 604;
BA_ "SigType" SG_ 2633942014 TransNeutralSwitch 4;
BA_ "SPN" SG_ 2633942014 TransReverseDirectionSwitch 767;
BA_ "SigType" SG_ 2633942014 TransReverseDirectionSwitch 4;
BA_ "SPN" SG_ 2633942014 TransLowRangeSenseSwitch 779;
BA_ "SigType" SG_ 2633942014 TransLowRangeSenseSwitch 4;
BA_ "SPN" SG_ 2633942014 TransHighRangeSenseSwitch 778;
BA_ "SigType" SG_ 2633942014 TransHighRangeSenseSwitch 4;
BA_ "SPN" SG_ 2633942526 TransSynchronizerBrakeValue 54;
BA_ "SigType" SG_ 2633942526 TransSynchronizerBrakeValue 1;
BA_ "SPN" SG_ 2633942526 TransSynchronizerClutchValue 53;
BA_ "SigType" SG_ 2633942526 TransSynchronizerClutchValue 1;
BA_ "SPN" SG_ 2633943038 TransInertiaBrakeActuator 787;
BA_ "SigType" SG_ 2633943038 TransInertiaBrakeActuator 4;
BA_ "SPN" SG_ 2633943038 TransDefuelActuator 786;
BA_ "SigType" SG_ 2633943038 TransDefuelActuator 4;
BA_ "SPN" SG_ 2633943038 TransLockupClutchActuator 740;
BA_ "SigType" SG_ 2633943038 TransLockupClutchActuator 4;
BA_ "SPN" SG_ 2633943038 TransClutchActuator 788;
BA_ "SigType" SG_ 2633943038 TransClutchActuator 4;
BA_ "SPN" SG_ 2633943038 TransSplitterIndirectActuator 771;
BA_ "SigType" SG_ 2633943038 TransSplitterIndirectActuator 4;
BA_ "SPN" SG_ 2633943038 TransSplitterDirectActuator 770;
BA_ "SigType" SG_ 2633943038 TransSplitterDirectActuator 4;
BA_ "SPN" SG_ 2633943038 TransRangeLowActuator 769;
BA_ "SigType" SG_ 2633943038 TransRangeLowActuator 4;
BA_ "SPN" SG_ 2633943038 TransRangeHighActuator 768;
BA_ "SigType" SG_ 2633943038 TransRangeHighActuator 4;
BA_ "SPN" SG_ 2633943038 TransShiftFingerGearActuator2 784;
BA_ "SigType" SG_ 2633943038 TransShiftFingerGearActuator2 4;
BA_ "SPN" SG_ 2633943038 TransShiftFingerRailActuator2 783;
BA_ "SigType" SG_ 2633943038 TransShiftFingerRailActuator2 4;
BA_ "SPN" SG_ 2633943038 TransShiftFingerGearActuator1 773;
BA_ "SigType" SG_ 2633943038 TransShiftFingerGearActuator1 4;
BA_ "SPN" SG_ 2633943038 TransShiftFingerRailActuator1 772;
BA_ "SigType" SG_ 2633943038 TransShiftFingerRailActuator1 4;
BA_ "SPN" SG_ 2633943038 TrnsShftFngrCenterRailIndicator 782;
BA_ "SigType" SG_ 2633943038 TrnsShftFngrCenterRailIndicator 4;
BA_ "SPN" SG_ 2633943038 TrnsShftFngrEngagementIndicator 781;
BA_ "SigType" SG_ 2633943038 TrnsShftFngrEngagementIndicator 4;
BA_ "SPN" SG_ 2633943038 TrnsShiftFingerNeutralIndicator 780;
BA_ "SigType" SG_ 2633943038 TrnsShiftFingerNeutralIndicator 4;
BA_ "SPN" SG_ 2633943038 TransShiftFingerRailPos 60;
BA_ "SigType" SG_ 2633943038 TransShiftFingerRailPos 1;
BA_ "SPN" SG_ 2633943038 TransShiftFingerGearPos 59;
BA_ "SigType" SG_ 2633943038 TransShiftFingerGearPos 1;
BA_ "SPN" SG_ 2565867006 TransCurrentRange 163;
BA_ "SigType" SG_ 2565867006 TransCurrentRange 1;
BA_ "SPN" SG_ 2565867006 TransRqedRange 162;
BA_ "SigType" SG_ 2565867006 TransRqedRange 1;
BA_ "SPN" SG_ 2565867006 TransCurrentGear 523;
BA_ "SigType" SG_ 2565867006 TransCurrentGear 1;
BA_ "SPN" SG_ 2565867006 TransActualGearRatio 526;
BA_ "SigType" SG_ 2565867006 TransActualGearRatio 1;
BA_ "SPN" SG_ 2565867006 TransSelectedGear 524;
BA_ "SigType" SG_ 2565867006 TransSelectedGear 1;
BA_ "SPN" SG_ 2565866755 TransCurrentRange 163;
BA_ "SigType" SG_ 2565866755 TransCurrentRange 1;
BA_ "SPN" SG_ 2565866755 TransRqedRange 162;
BA_ "SigType" SG_ 2565866755 TransRqedRange 1;
BA_ "SPN" SG_ 2565866755 TransCurrentGear 523;
BA_ "SigType" SG_ 2565866755 TransCurrentGear 1;
BA_ "SPN" SG_ 2565866755 TransActualGearRatio 526;
BA_ "SigType" SG_ 2565866755 TransActualGearRatio 1;
BA_ "SPN" SG_ 2565866755 TransSelectedGear 524;
BA_ "SigType" SG_ 2565866755 TransSelectedGear 1;
BA_ "SPN" SG_ 2364539646 TrnsTrqueConverterLockupEngaged 573;
BA_ "SigType" SG_ 2364539646 TrnsTrqueConverterLockupEngaged 4;
BA_ "SPN" SG_ 2364539646 TrnsTrqCnvrtrLckpTrnstnInPrcess 4816;
BA_ "SigType" SG_ 2364539646 TrnsTrqCnvrtrLckpTrnstnInPrcess 4;
BA_ "SPN" SG_ 2364539646 SrcAddrssOfCtrllngDvcFrTrnsCntrl 1482;
BA_ "SigType" SG_ 2364539646 SrcAddrssOfCtrllngDvcFrTrnsCntrl 1;
BA_ "SPN" SG_ 2364539646 MomentaryEngMaxPowerEnable 5015;
BA_ "SigType" SG_ 2364539646 MomentaryEngMaxPowerEnable 4;
BA_ "SPN" SG_ 2364539646 TransInputShaftSpeed 161;
BA_ "SigType" SG_ 2364539646 TransInputShaftSpeed 1;
BA_ "SPN" SG_ 2364539646 ProgressiveShiftDisable 607;
BA_ "SigType" SG_ 2364539646 ProgressiveShiftDisable 4;
BA_ "SPN" SG_ 2364539646 EngMomentaryOverspeedEnable 606;
BA_ "SigType" SG_ 2364539646 EngMomentaryOverspeedEnable 4;
BA_ "SPN" SG_ 2364539646 PercentClutchSlip 522;
BA_ "SigType" SG_ 2364539646 PercentClutchSlip 1;
BA_ "SPN" SG_ 2364539646 TransOutputShaftSpeed 191;
BA_ "SigType" SG_ 2364539646 TransOutputShaftSpeed 1;
BA_ "SPN" SG_ 2364539646 TransShiftInProcess 574;
BA_ "SigType" SG_ 2364539646 TransShiftInProcess 4;
BA_ "SPN" SG_ 2364539646 TransDrivelineEngaged 560;
BA_ "SigType" SG_ 2364539646 TransDrivelineEngaged 4;
BA_ "SPN" SG_ 2364539395 TrnsTrqueConverterLockupEngaged 573;
BA_ "SigType" SG_ 2364539395 TrnsTrqueConverterLockupEngaged 4;
BA_ "SPN" SG_ 2364539395 TrnsTrqCnvrtrLckpTrnstnInPrcess 4816;
BA_ "SigType" SG_ 2364539395 TrnsTrqCnvrtrLckpTrnstnInPrcess 4;
BA_ "SPN" SG_ 2364539395 SrcAddrssOfCtrllngDvcFrTrnsCntrl 1482;
BA_ "SigType" SG_ 2364539395 SrcAddrssOfCtrllngDvcFrTrnsCntrl 1;
BA_ "SPN" SG_ 2364539395 MomentaryEngMaxPowerEnable 5015;
BA_ "SigType" SG_ 2364539395 MomentaryEngMaxPowerEnable 4;
BA_ "SPN" SG_ 2364539395 TransInputShaftSpeed 161;
BA_ "SigType" SG_ 2364539395 TransInputShaftSpeed 1;
BA_ "SPN" SG_ 2364539395 ProgressiveShiftDisable 607;
BA_ "SigType" SG_ 2364539395 ProgressiveShiftDisable 4;
BA_ "SPN" SG_ 2364539395 EngMomentaryOverspeedEnable 606;
BA_ "SigType" SG_ 2364539395 EngMomentaryOverspeedEnable 4;
BA_ "SPN" SG_ 2364539395 PercentClutchSlip 522;
BA_ "SigType" SG_ 2364539395 PercentClutchSlip 1;
BA_ "SPN" SG_ 2364539395 TransOutputShaftSpeed 191;
BA_ "SigType" SG_ 2364539395 TransOutputShaftSpeed 1;
BA_ "SPN" SG_ 2364539395 TransShiftInProcess 574;
BA_ "SigType" SG_ 2364539395 TransShiftInProcess 4;
BA_ "SPN" SG_ 2364539395 TransDrivelineEngaged 560;
BA_ "SigType" SG_ 2364539395 TransDrivelineEngaged 4;
BA_ "SPN" SG_ 2566810110 EngChargeAirCooler1OutletTemp 2630;
BA_ "SigType" SG_ 2566810110 EngChargeAirCooler1OutletTemp 1;
BA_ "SPN" SG_ 2566810110 EngIntkVlvActationSystemOilTemp 2986;
BA_ "SigType" SG_ 2566810110 EngIntkVlvActationSystemOilTemp 1;
BA_ "SPN" SG_ 2566810110 EngIntakeManifold1AirTemp 1636;
BA_ "SigType" SG_ 2566810110 EngIntakeManifold1AirTemp 1;
BA_ "SPN" SG_ 2566810110 EngCoolantTempHiRes 1637;
BA_ "SigType" SG_ 2566810110 EngCoolantTempHiRes 1;
BA_ "SPN" SG_ 2566825214 EngExhstGsRcrculation1DiffPress 411;
BA_ "SigType" SG_ 2566825214 EngExhstGsRcrculation1DiffPress 1;
BA_ "SPN" SG_ 2566825214 EngExhaustGasRecirculation1Temp 412;
BA_ "SigType" SG_ 2566825214 EngExhaustGasRecirculation1Temp 1;
BA_ "SPN" SG_ 2566825214 EngECUTemp 1136;
BA_ "SigType" SG_ 2566825214 EngECUTemp 1;
BA_ "SPN" SG_ 2566825214 EngOilTemp2 1135;
BA_ "SigType" SG_ 2566825214 EngOilTemp2 1;
BA_ "SPN" SG_ 2566844158 EngFuelTemp1 174;
BA_ "SigType" SG_ 2566844158 EngFuelTemp1 1;
BA_ "SPN" SG_ 2566844158 EngIntercoolerThermostatOpening 1134;
BA_ "SigType" SG_ 2566844158 EngIntercoolerThermostatOpening 1;
BA_ "SPN" SG_ 2566844158 EngIntercoolerTemp 52;
BA_ "SigType" SG_ 2566844158 EngIntercoolerTemp 1;
BA_ "SPN" SG_ 2566844158 EngTurboOilTemp 176;
BA_ "SigType" SG_ 2566844158 EngTurboOilTemp 1;
BA_ "SPN" SG_ 2566844158 EngOilTemp1 175;
BA_ "SigType" SG_ 2566844158 EngOilTemp1 1;
BA_ "SPN" SG_ 2566844158 EngCoolantTemp 1637;
BA_ "SigType" SG_ 2566844158 EngCoolantTemp 1;
BA_ "SPN" SG_ 2566843904 EngFuelTemp1 174;
BA_ "SigType" SG_ 2566843904 EngFuelTemp1 1;
BA_ "SPN" SG_ 2566843904 EngIntercoolerThermostatOpening 1134;
BA_ "SigType" SG_ 2566843904 EngIntercoolerThermostatOpening 1;
BA_ "SPN" SG_ 2566843904 EngIntercoolerTemp 52;
BA_ "SigType" SG_ 2566843904 EngIntercoolerTemp 1;
BA_ "SPN" SG_ 2566843904 EngTurboOilTemp 176;
BA_ "SigType" SG_ 2566843904 EngTurboOilTemp 1;
BA_ "SPN" SG_ 2566843904 EngOilTemp1 175;
BA_ "SigType" SG_ 2566843904 EngOilTemp1 1;
BA_ "SPN" SG_ 2566843904 EngCoolantTemp 1637;
BA_ "SigType" SG_ 2566843904 EngCoolantTemp 1;
BA_ "SPN" SG_ 2566785022 EngExhaustGasTempRightManifold 2433;
BA_ "SigType" SG_ 2566785022 EngExhaustGasTempRightManifold 1;
BA_ "SPN" SG_ 2566785022 EngExhaustGasTempLeftManifold 2434;
BA_ "SigType" SG_ 2566785022 EngExhaustGasTempLeftManifold 1;
BA_ "SPN" SG_ 2565868542 SterableLiftAxleLoweringInhibit 2922;
BA_ "SigType" SG_ 2565868542 SterableLiftAxleLoweringInhibit 4;
BA_ "SPN" SG_ 2565868542 AxleLocation 2928;
BA_ "SigType" SG_ 2565868542 AxleLocation 1;
BA_ "SPN" SG_ 2565868542 TypeOfSteerTrans 2926;
BA_ "SigType" SG_ 2565868542 TypeOfSteerTrans 4;
BA_ "SPN" SG_ 2565868542 TypeOfSteerForces 2925;
BA_ "SigType" SG_ 2565868542 TypeOfSteerForces 4;
BA_ "SPN" SG_ 2565868542 SteerType 2924;
BA_ "SigType" SG_ 2565868542 SteerType 4;
BA_ "SPN" SG_ 2565868542 StatusOfSteerAxle 2923;
BA_ "SigType" SG_ 2565868542 StatusOfSteerAxle 4;
BA_ "SPN" SG_ 2565868542 ActualInnerWheelSteerAngle 2927;
BA_ "SigType" SG_ 2565868542 ActualInnerWheelSteerAngle 1;
BA_ "SPN" SG_ 2633941758 TransOutputRetarder 748;
BA_ "SigType" SG_ 2633941758 TransOutputRetarder 4;
BA_ "SPN" SG_ 2565865726 RetarderSelectionNonEng 1716;
BA_ "SigType" SG_ 2565865726 RetarderSelectionNonEng 1;
BA_ "SPN" SG_ 2565865726 SrcAddrssOfCtrllngDvcFrRtrdrCntr 1480;
BA_ "SigType" SG_ 2565865726 SrcAddrssOfCtrllngDvcFrRtrdrCntr 1;
BA_ "SystemSignalLongSymbol" SG_ 2565865726 SrcAddrssOfCtrllngDvcFrRtrdrCntr "SrcAddrssOfCtrllngDvcFrRtrdrCntrl";
BA_ "SPN" SG_ 2565865726 RetarderRoadSpeedLimitSwitch 4233;
BA_ "SigType" SG_ 2565865726 RetarderRoadSpeedLimitSwitch 4;
BA_ "SPN" SG_ 2565865726 RetarderRoadSpeedExceededStatus 4234;
BA_ "SigType" SG_ 2565865726 RetarderRoadSpeedExceededStatus 4;
BA_ "SPN" SG_ 2565865726 ActlMxAvlblRtarderPercentTorque 1717;
BA_ "SigType" SG_ 2565865726 ActlMxAvlblRtarderPercentTorque 1;
BA_ "SPN" SG_ 2565865726 DrvrsDmandRetarderPercentTorque 1715;
BA_ "SigType" SG_ 2565865726 DrvrsDmandRetarderPercentTorque 1;
BA_ "SPN" SG_ 2565865726 RetarderRqingBrakeLight 1667;
BA_ "SigType" SG_ 2565865726 RetarderRqingBrakeLight 4;
BA_ "SPN" SG_ 2565865726 EngCoolantLoadIncrease 1082;
BA_ "SigType" SG_ 2565865726 EngCoolantLoadIncrease 4;
BA_ "SPN" SG_ 2565865726 IntendedRetarderPercentTorque 1085;
BA_ "SigType" SG_ 2565865726 IntendedRetarderPercentTorque 1;
BA_ "SPN" SG_ 2565865726 ActualRetarderPercentTorque 520;
BA_ "SigType" SG_ 2565865726 ActualRetarderPercentTorque 1;
BA_ "SPN" SG_ 2565865726 RetarderEnableShiftAssistSwitch 572;
BA_ "SigType" SG_ 2565865726 RetarderEnableShiftAssistSwitch 4;
BA_ "SPN" SG_ 2565865726 RetarderEnableBrakeAssistSwitch 571;
BA_ "SigType" SG_ 2565865726 RetarderEnableBrakeAssistSwitch 4;
BA_ "SPN" SG_ 2565865726 RetarderTorqueMode 900;
BA_ "SigType" SG_ 2565865726 RetarderTorqueMode 4;
BA_ "SPN" SG_ 2565865487 RetarderSelectionNonEng 1716;
BA_ "SigType" SG_ 2565865487 RetarderSelectionNonEng 1;
BA_ "SPN" SG_ 2565865487 SrcAddrssOfCtrllngDvcFrRtrdrCntr 1480;
BA_ "SigType" SG_ 2565865487 SrcAddrssOfCtrllngDvcFrRtrdrCntr 1;
BA_ "SystemSignalLongSymbol" SG_ 2565865487 SrcAddrssOfCtrllngDvcFrRtrdrCntr "SrcAddrssOfCtrllngDvcFrRtrdrCntrl";
BA_ "SPN" SG_ 2565865487 RetarderRoadSpeedLimitSwitch 4233;
BA_ "SigType" SG_ 2565865487 RetarderRoadSpeedLimitSwitch 4;
BA_ "SPN" SG_ 2565865487 RetarderRoadSpeedExceededStatus 4234;
BA_ "SigType" SG_ 2565865487 RetarderRoadSpeedExceededStatus 4;
BA_ "SPN" SG_ 2565865487 ActlMxAvlblRtarderPercentTorque 1717;
BA_ "SigType" SG_ 2565865487 ActlMxAvlblRtarderPercentTorque 1;
BA_ "SPN" SG_ 2565865487 DrvrsDmandRetarderPercentTorque 1715;
BA_ "SigType" SG_ 2565865487 DrvrsDmandRetarderPercentTorque 1;
BA_ "SPN" SG_ 2565865487 RetarderRqingBrakeLight 1667;
BA_ "SigType" SG_ 2565865487 RetarderRqingBrakeLight 4;
BA_ "SPN" SG_ 2565865487 EngCoolantLoadIncrease 1082;
BA_ "SigType" SG_ 2565865487 EngCoolantLoadIncrease 4;
BA_ "SPN" SG_ 2565865487 IntendedRetarderPercentTorque 1085;
BA_ "SigType" SG_ 2565865487 IntendedRetarderPercentTorque 1;
BA_ "SPN" SG_ 2565865487 ActualRetarderPercentTorque 520;
BA_ "SigType" SG_ 2565865487 ActualRetarderPercentTorque 1;
BA_ "SPN" SG_ 2565865487 RetarderEnableShiftAssistSwitch 572;
BA_ "SigType" SG_ 2565865487 RetarderEnableShiftAssistSwitch 4;
BA_ "SPN" SG_ 2565865487 RetarderEnableBrakeAssistSwitch 571;
BA_ "SigType" SG_ 2565865487 RetarderEnableBrakeAssistSwitch 4;
BA_ "SPN" SG_ 2565865487 RetarderTorqueMode 900;
BA_ "SigType" SG_ 2565865487 RetarderTorqueMode 4;
BA_ "SPN" SG_ 2565865488 RetarderSelectionNonEng 1716;
BA_ "SigType" SG_ 2565865488 RetarderSelectionNonEng 1;
BA_ "SPN" SG_ 2565865488 SrcAddrssOfCtrllngDvcFrRtrdrCntr 1480;
BA_ "SigType" SG_ 2565865488 SrcAddrssOfCtrllngDvcFrRtrdrCntr 1;
BA_ "SystemSignalLongSymbol" SG_ 2565865488 SrcAddrssOfCtrllngDvcFrRtrdrCntr "SrcAddrssOfCtrllngDvcFrRtrdrCntrl";
BA_ "SPN" SG_ 2565865488 RetarderRoadSpeedLimitSwitch 4233;
BA_ "SigType" SG_ 2565865488 RetarderRoadSpeedLimitSwitch 4;
BA_ "SPN" SG_ 2565865488 RetarderRoadSpeedExceededStatus 4234;
BA_ "SigType" SG_ 2565865488 RetarderRoadSpeedExceededStatus 4;
BA_ "SPN" SG_ 2565865488 ActlMxAvlblRtarderPercentTorque 1717;
BA_ "SigType" SG_ 2565865488 ActlMxAvlblRtarderPercentTorque 1;
BA_ "SPN" SG_ 2565865488 DrvrsDmandRetarderPercentTorque 1715;
BA_ "SigType" SG_ 2565865488 DrvrsDmandRetarderPercentTorque 1;
BA_ "SPN" SG_ 2565865488 RetarderRqingBrakeLight 1667;
BA_ "SigType" SG_ 2565865488 RetarderRqingBrakeLight 4;
BA_ "SPN" SG_ 2565865488 EngCoolantLoadIncrease 1082;
BA_ "SigType" SG_ 2565865488 EngCoolantLoadIncrease 4;
BA_ "SPN" SG_ 2565865488 IntendedRetarderPercentTorque 1085;
BA_ "SigType" SG_ 2565865488 IntendedRetarderPercentTorque 1;
BA_ "SPN" SG_ 2565865488 ActualRetarderPercentTorque 520;
BA_ "SigType" SG_ 2565865488 ActualRetarderPercentTorque 1;
BA_ "SPN" SG_ 2565865488 RetarderEnableShiftAssistSwitch 572;
BA_ "SigType" SG_ 2565865488 RetarderEnableShiftAssistSwitch 4;
BA_ "SPN" SG_ 2565865488 RetarderEnableBrakeAssistSwitch 571;
BA_ "SigType" SG_ 2565865488 RetarderEnableBrakeAssistSwitch 4;
BA_ "SPN" SG_ 2565865488 RetarderTorqueMode 900;
BA_ "SigType" SG_ 2565865488 RetarderTorqueMode 4;
BA_ "SPN" SG_ 2633932798 EngExhaustGasPort20Temp 1156;
BA_ "SigType" SG_ 2633932798 EngExhaustGasPort20Temp 1;
BA_ "SPN" SG_ 2633932798 EngExhaustGasPort19Temp 1155;
BA_ "SigType" SG_ 2633932798 EngExhaustGasPort19Temp 1;
BA_ "SPN" SG_ 2633932798 EngExhaustGasPort18Temp 1154;
BA_ "SigType" SG_ 2633932798 EngExhaustGasPort18Temp 1;
BA_ "SPN" SG_ 2633932798 EngExhaustGasPort17Temp 1153;
BA_ "SigType" SG_ 2633932798 EngExhaustGasPort17Temp 1;
BA_ "SPN" SG_ 2566824190 EngExhaustGasPort16Temp 1152;
BA_ "SigType" SG_ 2566824190 EngExhaustGasPort16Temp 1;
BA_ "SPN" SG_ 2566824190 EngExhaustGasPort15Temp 1151;
BA_ "SigType" SG_ 2566824190 EngExhaustGasPort15Temp 1;
BA_ "SPN" SG_ 2566824190 EngExhaustGasPort14Temp 1150;
BA_ "SigType" SG_ 2566824190 EngExhaustGasPort14Temp 1;
BA_ "SPN" SG_ 2566824190 EngExhaustGasPort13Temp 1149;
BA_ "SigType" SG_ 2566824190 EngExhaustGasPort13Temp 1;
BA_ "SPN" SG_ 2633933310 EngExhaustGasPort12Temp 1148;
BA_ "SigType" SG_ 2633933310 EngExhaustGasPort12Temp 1;
BA_ "SPN" SG_ 2633933310 EngExhaustGasPort11Temp 1147;
BA_ "SigType" SG_ 2633933310 EngExhaustGasPort11Temp 1;
BA_ "SPN" SG_ 2633933310 EngExhaustGasPort10Temp 1146;
BA_ "SigType" SG_ 2633933310 EngExhaustGasPort10Temp 1;
BA_ "SPN" SG_ 2633933310 EngExhaustGasPort9Temp 1145;
BA_ "SigType" SG_ 2633933310 EngExhaustGasPort9Temp 1;
BA_ "SPN" SG_ 2633933566 EngExhaustGasPort8Temp 1144;
BA_ "SigType" SG_ 2633933566 EngExhaustGasPort8Temp 1;
BA_ "SPN" SG_ 2633933566 EngExhaustGasPort7Temp 1143;
BA_ "SigType" SG_ 2633933566 EngExhaustGasPort7Temp 1;
BA_ "SPN" SG_ 2633933566 EngExhaustGasPort6Temp 1142;
BA_ "SigType" SG_ 2633933566 EngExhaustGasPort6Temp 1;
BA_ "SPN" SG_ 2633933566 EngExhaustGasPort5Temp 1141;
BA_ "SigType" SG_ 2633933566 EngExhaustGasPort5Temp 1;
BA_ "SPN" SG_ 2633933822 EngExhaustGasPort4Temp 1140;
BA_ "SigType" SG_ 2633933822 EngExhaustGasPort4Temp 1;
BA_ "SPN" SG_ 2633933822 EngExhaustGasPort3Temp 1139;
BA_ "SigType" SG_ 2633933822 EngExhaustGasPort3Temp 1;
BA_ "SPN" SG_ 2633933822 EngExhaustGasPort2Temp 1138;
BA_ "SigType" SG_ 2633933822 EngExhaustGasPort2Temp 1;
BA_ "SPN" SG_ 2633933822 EngExhaustGasPort1Temp 1137;
BA_ "SigType" SG_ 2633933822 EngExhaustGasPort1Temp 1;
BA_ "SPN" SG_ 2566776062 PayloadPercentage 2600;
BA_ "SigType" SG_ 2566776062 PayloadPercentage 1;
BA_ "SPN" SG_ 2566771454 DataMemoryUsage 2802;
BA_ "SigType" SG_ 2566771454 DataMemoryUsage 1;
BA_ "SPN" SG_ 2566771454 KeepAliveBatteryConsumption 2803;
BA_ "SigType" SG_ 2566771454 KeepAliveBatteryConsumption 4;
BA_ "SPN" SG_ 2566775806 TravelVelocityCtrlPos 2601;
BA_ "SigType" SG_ 2566775806 TravelVelocityCtrlPos 1;
BA_ "SPN" SG_ 2633935358 EngExhstGsOxygnSnsrClsdLpOprton 1696;
BA_ "SigType" SG_ 2633935358 EngExhstGsOxygnSnsrClsdLpOprton 4;
BA_ "SPN" SG_ 2633935358 EngExhstGsOxygnSnsrFlngCrrction 1695;
BA_ "SigType" SG_ 2633935358 EngExhstGsOxygnSnsrFlngCrrction 1;
BA_ "SPN" SG_ 2633935358 EngActualExhaustOxygen 1119;
BA_ "SigType" SG_ 2633935358 EngActualExhaustOxygen 1;
BA_ "SPN" SG_ 2633935358 EngDesiredExhaustOxygen 1118;
BA_ "SigType" SG_ 2633935358 EngDesiredExhaustOxygen 1;
BA_ "SPN" SG_ 2633935358 EngDesiredRatedExhaustOxygen 1117;
BA_ "SigType" SG_ 2633935358 EngDesiredRatedExhaustOxygen 1;
VAL_ 2348941054 TrnsShftSlctorDisplayModeSwitch 3 "NotAvailable" 2 "Error" 1 "On" 0 "Off" ;
VAL_ 2348941054 TransMode4 3 "TakeNoAction" 2 "Reserved" 1 "Enable" 0 "Disable" ;
VAL_ 2348941054 TransMode3 3 "TakeNoAction" 2 "Reserved" 1 "Enable" 0 "Disable" ;
VAL_ 2348941054 TransMode2 3 "TakeNoAction" 2 "Reserved" 1 "Enable" 0 "Disable" ;
VAL_ 2348941054 TransMode1 3 "TakeNoAction" 2 "Reserved" 1 "Enable" 0 "Disable" ;
VAL_ 2348941054 DisengageDiffLockRqCentralRear 3 "TakeNoAction" 2 "Reserved" 1 "DisengageDiffLock" 0 "EngageDiffLock" ;
VAL_ 2348941054 DisengageDiffLockRqCentralFront 3 "TakeNoAction" 2 "Reserved" 1 "DisengageDiffLock" 0 "EngageDiffLock" ;
VAL_ 2348941054 DisengageDiffLockRqCentral 3 "TakeNoAction" 2 "Reserved" 1 "DisengageDiffLock" 0 "EngageDiffLock" ;
VAL_ 2348941054 DisengageDiffLockRqRearAxle2 3 "TakeNoAction" 2 "Reserved" 1 "DisengageDiffLock" 0 "EngageDiffLock" ;
VAL_ 2348941054 DisengageDiffLockRqRearAxle1 3 "TakeNoAction" 2 "Reserved" 1 "DisengageDiffLock" 0 "EngageDiffLock" ;
VAL_ 2348941054 DisengageDiffLockRqFrontAxle2 3 "TakeNoAction" 2 "Reserved" 1 "DisengageDiffLock" 0 "EngageDiffLock" ;
VAL_ 2348941054 DisengageDiffLockRqFrontAxle1 3 "TakeNoAction" 2 "Reserved" 1 "DisengageDiffLock" 0 "EngageDiffLock" ;
VAL_ 2348941054 TransRqedGear 60 "Reserved" 61 "Reserved" 222 "NeutralSelectorPos" 223 "ReverseSelectorPos" 224 "PsUnknownAnd_OrNoButtonsPressed" 225 "PrssOfMmntryBttnTRslctCrrentPos" 226 "BtwnRvrsAndPrkShiftSelectorPoss" 227 "BtwnNtrlAndRvrsShftSelectorPoss" 228 "BtwnDrvAndNtrlShiftSelectorPoss" 229 "BtwnD1AndDriveShiftSelectorPoss" 230 "BetweenD2AndD1ShiftSelectorPoss" 231 "BetweenD3AndD2ShiftSelectorPoss" 232 "BetweenD4AndD3ShiftSelectorPoss" 233 "BetweenD5AndD4ShiftSelectorPoss" 234 "BetweenD6AndD5ShiftSelectorPoss" 235 "BetweenD7AndD6ShiftSelectorPoss" 236 "BtwnTwoForwardShiftSelectorPoss" 237 "BtwnTwoReverseShiftSelectorPoss" 238 "BetweenTwoShiftSelectorPoss" 239 "D77thFrwrdSlctrPsRfrncdFrmDrive" 240 "D66thFrwrdSlctrPsRfrncdFrmDrive" 241 "D55thFrwrdSlctrPsRfrncdFrmDrive" 242 "D44thFrwrdSlctrPsRfrncdFrmDrive" 243 "D33rdFrwrdSlctrPsRfrncdFrmDrive" 244 "D22ndFrwrdSlctrPsRfrncdFrmDrive" 245 "D11stFrwrdSlctrPsRfrncdFrmDrive" 246 "Downshift2GearsFromCurrentPos" 247 "Downshift1GearFromCurrentPos" 248 "Upshift2GearsFromCurrentPos" 249 "Upshift1GearFromCurrentPos" 250 "ForwardLowPos" 251 "ParkPos" 252 "ForwardDrivePos" 253 "HoldCurrentGear" ;
VAL_ 2348941054 DisengageDrivelineRq 2 "Reserved" 3 "TakeNoAction" 1 "DisengageDriveline" 0 "AllowDrivelineEngagement" ;
VAL_ 2348941054 TransGearShiftInhibitRq 2 "Reserved" 3 "TakeNoAction" 1 "GearShiftsAreInhibited" 0 "GearShiftsAreAllowed" ;
VAL_ 2348941054 TrnsTrqConverterLockupDisableRq 3 "TakeNoAction" 2 "Reserved" 1 "DisableTorqueConverterLockup" 0 "AllowTorqueConverterLockup" ;
VAL_ 2348941054 TransRqedLaunchGear 15 "NotAvailable" 14 "Error" 13 "Reserved" 12 "LaunchVehicleInReverse4" 11 "LaunchVehicleInReverse3" 10 "LaunchVehicleInReverse2" 9 "LaunchVehicleInReverse1" 8 "LaunchVehicleIn8thGear" 7 "LaunchVehicleIn7thGear" 6 "LaunchVehicleIn6thGear" 5 "LaunchVehicleIn5thGear" 4 "LaunchVehicleIn4thGear" 3 "LaunchVehicleIn3rdGear" 2 "LaunchVehicleIn2ndGear" 1 "LaunchVehicleIn1stGear" 0 "NSpcfcLnchGrRqdUsDfltLaunchGear" ;
VAL_ 2348941054 TransReverseGearShiftInhibitRq 3 "TakeNoAction" 2 "Reserved" 1 "InhbtShftsIntRvrsGrAndShftTrnsT" 0 "AllowShiftsIntoReverseGear" ;
VAL_ 2348941054 TransMode8 3 "TakeNoAction" 2 "Reserved" 1 "Enable" 0 "Disable" ;
VAL_ 2348941054 TransMode7 3 "TakeNoAction" 2 "Reserved" 1 "Enable" 0 "Disable" ;
VAL_ 2348941054 TransMode6 3 "TakeNoAction" 2 "Reserved" 1 "Enable" 0 "Disable" ;
VAL_ 2348941054 TransMode5 3 "TakeNoAction" 2 "Reserved" 1 "Enable" 0 "Disable" ;
VAL_ 2566839806 EngTurboOilLevelSwitch 3 "NotAvailable" 2 "Error" 1 "OilPresentAtTurbo" 0 "NoOilPresentAtTurbo" ;
VAL_ 2566841598 EngOverspeedTest 3 "NotAvailable" 2 "Reserved" 1 "EngOverspeedTestActive" 0 "EngOverspeedTestNotActive" ;
VAL_ 2566841598 EngAirShutoffCmdStatus 0 "ArShtffDsbldNtAttmptngTShtffEng" 3 "NotAvailable" 2 "Reserved" 1 "ArShtffEnbldAttmptngTShtffEngAr" ;
VAL_ 2566841598 EngAlarmOutputCmdStatus 3 "NotAvailable" 2 "Reserved" 1 "EngAlarmOutputCmdActive" 0 "EngAlarmOutputCmdNotActive" ;
VAL_ 2566841598 EngAlarmAcknowledge 3 "NotAvailable" 2 "Error" 1 "EngAlarmAcknowledgeActive" 0 "EngAlarmAcknowledgeNotActive" ;
VAL_ 2566841598 EngProtectionSystemConfig 3 "NotAvailable" 2 "Error" 1 "EnabledInCalib" 0 "DisabledInCalib" ;
VAL_ 2566841598 EngProtectionSystemTimerState 3 "NotAvailable" 2 "Error" 1 "Active" 0 "Inactive" ;
VAL_ 2566841598 EngPrtectionSystemTimerOverride 3 "NotAvailable" 2 "Error" 1 "Active" 0 "Inactive" ;
VAL_ 2566841598 EngPrtctnSystmApprchingShutdown 3 "NotAvailable" 2 "Error" 1 "Approaching" 0 "NotApproaching" ;
VAL_ 2566841598 EngWaitToStartLamp 3 "NotAvailable" 2 "Error" 1 "On" 0 "Off" ;
VAL_ 2566841598 RefrigerantHighPressSwitch 3 "NotAvailable" 2 "Error" 1 "PrssTHghCmprssrCltchMyBDsngaged" 0 "PressNormal" ;
VAL_ 2566841598 RefrigerantLowPressSwitch 3 "NotAvailable" 2 "Error" 1 "PrssTLwCmprssrCltchMyBDsengaged" 0 "PressNormal" ;
VAL_ 2566841598 A_CHighPressFanSwitch 3 "NotAvailable" 2 "Error" 1 "PressHighFanMayBeEngaged" 0 "PressNormal" ;
VAL_ 2566841598 EngIdleShutdownTimerFunction 3 "NotAvailable" 2 "Error" 1 "EnabledInCalib" 0 "DisabledInCalib" ;
VAL_ 2566841598 EngIdleShutdownTimerState 3 "NotAvailable" 2 "Error" 1 "Active" 0 "Inactive" ;
VAL_ 2566841598 EngIdleShutdownTimerOverride 3 "NotAvailable" 2 "Error" 1 "Active" 0 "Inactive" ;
VAL_ 2566841598 EngIdleShutdownDriverAlertMode 3 "NotAvailable" 2 "Error" 1 "Active" 0 "Inactive" ;
VAL_ 2566841598 PTOShutdownHasShutdownEng 3 "NotAvailable" 2 "Error" 1 "Yes" 0 "No" ;
VAL_ 2566841598 EngPrtctnSystmHasShutdownEngine 3 "NotAvailable" 2 "Error" 1 "Yes" 0 "No" ;
VAL_ 2566841598 EngIdlShutdownHasShutdownEngine 3 "NotAvailable" 2 "Error" 1 "Yes" 0 "No" ;
VAL_ 2566841598 EngAirShutoffStatus 3 "NotAvailable" 2 "Error" 1 "AirFlowRestricted" 0 "AirFlowAllowedToEng" ;
VAL_ 2566847486 DrvlneRetarderOverheatIndicator 3 "NotAvailable" 2 "DrvlnRtrdrOvrhtIndctrIsFlashing" 1 "DrvlnRtrdrOvrhtIndctrIsOnCntnsl" 0 "DrvlnRtrdrOvrheatIndicatorIsOff" ;
VAL_ 2566847248 DrvlneRetarderOverheatIndicator 3 "NotAvailable" 2 "DrvlnRtrdrOvrhtIndctrIsFlashing" 1 "DrvlnRtrdrOvrhtIndctrIsOnCntnsl" 0 "DrvlnRtrdrOvrheatIndicatorIsOff" ;
VAL_ 2631859966 EngBuildHoursReset 2 "Reserved" 3 "TakeNoAction" 1 "Reset" 0 "DoNotReset" ;
VAL_ 2631859966 TripGroup2Proprietary 2 "Reserved" 3 "NotApplicable" 1 "Reset" 0 "TakeNoAction" ;
VAL_ 2631859966 TripGroup1 2 "Reserved" 3 "NotApplicable" 1 "Reset" 0 "TakeNoAction" ;
VAL_ 2631859966 SteerStraightAheadPosReset 3 "NotApplicable" 2 "ReservedTakeNoAction" 1 "Reset" 0 "TakeNoActionDoNotReset" ;
VAL_ 2566840830 RetarderLocation 15 "NotAvailable" 14 "Other" 6 "1101NotDefined" 5 "Trailer" 4 "Driveline" 3 "TransOutput" 2 "TransInput" 1 "EngExhaustBrake" 0 "EngCompressionReleaseBrake" ;
VAL_ 2566840830 RetarderType 15 "NotAvailable" 14 "Other" 5 "1101NotDefined" 4 "Exhaust" 3 "CompressionRelease" 2 "CooledFriction" 1 "Hyd" 0 "Electric_Magnetic" ;
VAL_ 2566844670 OprtrEngPTOGvrnrMmrySlectSwitch 3 "notAvailable" 2 "error" 1 "PTOSetSpeedMemory2Selected" 0 "PTOSetSpeedMemory1Selected" ;
VAL_ 2566844670 EngRmtPTOGvrnrVrblSpdCtrlSwitch 3 "NotAvailable" 2 "Error" 1 "On" 0 "Off" ;
VAL_ 2566844670 EngRmtPTOGvrnrPrprgrmmdSpdCtrlSw 3 "NotAvailable" 2 "Error" 1 "On" 0 "Off" ;
VAL_ 2566844670 EngPTOGvrnrCst_DecelerateSwitch 3 "NotAvailable" 2 "Error" 1 "On" 0 "Off" ;
VAL_ 2566844670 EngPTOGovernorSetSwitch 3 "NotAvailable" 2 "Error" 1 "On" 0 "Off" ;
VAL_ 2566844670 EngPTOGovernorResumeSwitch 3 "NotAvailable" 2 "Error" 1 "On" 0 "Off" ;
VAL_ 2566844670 EngPTOGovernorEnableSwitch 3 "NotAvailable" 2 "Error" 1 "On" 0 "Off" ;
VAL_ 2566844670 EngPTOGovernorAccelerateSwitch 3 "NotAvailable" 2 "Error" 1 "On" 0 "Off" ;
VAL_ 2566844670 RmtPTOPrprgrmmdSpeedCtrlSwitch2 3 "NotAvailable" 2 "Error" 1 "On" 0 "Off" ;
VAL_ 2566844670 AuxInputIgnoreSwitch 3 "NotAvailable" 2 "Error" 1 "On" 0 "Off" ;
VAL_ 2566844416 OprtrEngPTOGvrnrMmrySlectSwitch 3 "notAvailable" 2 "error" 1 "PTOSetSpeedMemory2Selected" 0 "PTOSetSpeedMemory1Selected" ;
VAL_ 2566844416 EngRmtPTOGvrnrVrblSpdCtrlSwitch 3 "NotAvailable" 2 "Error" 1 "On" 0 "Off" ;
VAL_ 2566844416 EngRmtPTOGvrnrPrprgrmmdSpdCtrlSw 3 "NotAvailable" 2 "Error" 1 "On" 0 "Off" ;
VAL_ 2566844416 EngPTOGvrnrCst_DecelerateSwitch 3 "NotAvailable" 2 "Error" 1 "On" 0 "Off" ;
VAL_ 2566844416 EngPTOGovernorSetSwitch 3 "NotAvailable" 2 "Error" 1 "On" 0 "Off" ;
VAL_ 2566844416 EngPTOGovernorResumeSwitch 3 "NotAvailable" 2 "Error" 1 "On" 0 "Off" ;
VAL_ 2566844416 EngPTOGovernorEnableSwitch 3 "NotAvailable" 2 "Error" 1 "On" 0 "Off" ;
VAL_ 2566844416 EngPTOGovernorAccelerateSwitch 3 "NotAvailable" 2 "Error" 1 "On" 0 "Off" ;
VAL_ 2566844416 RmtPTOPrprgrmmdSpeedCtrlSwitch2 3 "NotAvailable" 2 "Error" 1 "On" 0 "Off" ;
VAL_ 2566844416 AuxInputIgnoreSwitch 3 "NotAvailable" 2 "Error" 1 "On" 0 "Off" ;
VAL_ 2566770174 RearWasherFunction 7 "NotAvailable" 4 "110Reserved" 3 "High" 2 "Medium" 1 "Low" 0 "Off" ;
VAL_ 2566770174 FrontOperatorWasherSwitch 7 "NotAvailable" 4 "110Reserved" 3 "High" 2 "Medium" 1 "Low" 0 "Off" ;
VAL_ 2566770174 FrontNonoperatorWasherSwitch 7 "NotAvailable" 4 "110Reserved" 3 "High" 2 "Medium" 1 "Low" 0 "Off" ;
VAL_ 2566770174 RearWiperSwitch 7 "1110Reserved" 6 "Mist" 5 "Delayed2" 4 "Delayed1" 2 "Medium" 15 "NotAvailable" 3 "High" 1 "Low" 0 "Off" ;
VAL_ 2566770174 FrontOperatorWiperSwitch 7 "1110Reserved" 6 "Mist" 5 "Delayed2" 4 "Delayed1" 2 "Medium" 15 "NotAvailable" 3 "High" 1 "Low" 0 "Off" ;
VAL_ 2566770174 FrontNonoperatorWiperSwitch 15 "NotAvailable" 7 "1110Reserved" 6 "Mist" 5 "Delayed2" 4 "Delayed1" 3 "High" 2 "Medium" 1 "Low" 0 "Off" ;
VAL_ 2566769662 EngAltDroopAuxInputSelect 15 "NotAvailable" 14 "ErrorCondition" 1 "thr1101OnOfAltDrpSttng1Thrgh13I" 0 "NormalDroopSettingIsSelected" ;
VAL_ 2566769662 EngAltDroopRemoteAccelSelect 15 "NotAvailable" 14 "ErrorCondition" 1 "thr1101OnOfAltDrpSttng1Thrgh13I" 0 "NormalDroopSettingIsSelected" ;
VAL_ 2566769662 EngAltDroopAccel2Select 15 "NotAvailable" 14 "ErrorCondition" 1 "thr1101OnOfAltDrpSttng1Thrgh13I" 0 "NormalDroopSettingIsSelected" ;
VAL_ 2566769662 EngAltDroopAccel1Select 15 "NotAvailable" 14 "ErrorCondition" 1 "thr1101OnOfAltDrpSttng1Thrgh13I" 0 "NormalDroopSettingIsSelected" ;
VAL_ 2566769662 EngAltRatingSelect 1 "IndctsThtAltPwrFling1IsSelected" 0 "IndctsThtMxPwrFuelingIsSelected" ;
VAL_ 2566769662 EngAltLowIdleSwitch 3 "NotAvailableUnused" 2 "Error" 1 "AltLowIdlePointIsSelected" 0 "DefaultLowIdlePointIsSelected" ;
VAL_ 2566769662 EngSynchronizationSwitch 3 "NotAvailableUnused" 2 "Error" 1 "FunctionalityIsEnabled" 0 "FunctionalityIsDisabled" ;
VAL_ 2566769662 EngAuxGovernorSwitch 2 "ErrorCondition" 1 "AuxGovernorIsEnabled" 0 "AuxGovernorIsDisabled" 3 "NotAvailable" ;
VAL_ 2566768638 EngAltDroopAuxInputSelectState 15 "NotAvailable" 14 "SAEReserved" 1 "thr1101CtrlSttIsOnOfAltDrpSttng" 0 "CtrlStateIsNormalDroopSetting" ;
VAL_ 2566768638 EngAltDrpRemoteAccelSelectState 15 "NotAvailable" 14 "SAEReserved" 1 "thr1101CtrlSttIsOnOfAltDrpSttng" 0 "CtrlStateIsNormalDroopSetting" ;
VAL_ 2566768638 EngAltDroopAccel2SelectState 15 "NotAvailable" 14 "SAEReserved" 1 "thr1101CtrlsSttIsOnOfAltDrpSttn" 0 "CtrlsStateIsNormalDroopSetting" ;
VAL_ 2566768638 EngAltDroopAccel1SelectState 15 "NotAvailable" 14 "SAEReserved" 1 "thr1101CtrlSttIsOnOfAltDrpSttng" 0 "CtrlStateIsNormalDroopSetting" ;
VAL_ 2566768638 EngAltRatingSelectState 1 "CtrlStateIsAltPowerFueling1" 0 "CtrlStateIsMaxPowerFueling" ;
VAL_ 2566768638 EngAltLowIdleSelectState 3 "NotAvailable" 2 "SAEReserved" 1 "AltIdleState" 0 "NormalIdleState" ;
VAL_ 2566768638 EngMultiUnitSyncState 3 "NotAvailable" 2 "SAEReserved" 1 "CtrlStateIsFunctionalityEnabled" 0 "CtrlStteIsFunctionalityDisabled" ;
VAL_ 2566768638 EngAuxGovernorState 3 "NotAvailable" 2 "SAEReserved" 1 "CtrlStateIsAuxGovernorEnabled" 0 "CtrlStateIsAuxGovernorDisabled" ;
VAL_ 2365443326 HighLowBeamSwitch 3 "NotAvailable" 2 "Error" 1 "HighBeamSelected" 0 "LowBeamSelected" ;
VAL_ 2365443326 HazardLightSwitch 3 "NotAvailable" 2 "Error" 1 "HazardLampsToBeFlashing" 0 "HazardLampsToBeOff" ;
VAL_ 2365443326 TurnSignalSwitch 2 "RightTurnToBeFlashing" 15 "NotAvailable" 14 "Error" 3 "1101Reserved" 1 "LeftTurnToBeFlashing" 0 "NoTurnBeingSignaled" ;
VAL_ 2365443326 MainLightSwitch 9 "1101Reserved" 8 "DlydOffPsByWhchThOprtrSlctsThtA" 4 "0111Reserved" 2 "HdlghtOnPsByWhchThOprtrSlctsTht" 15 "NotAvailable" 14 "Error" 3 "HdlghtAndPrkOnPsByWhchThOprtrSl" 1 "PrkOnPsByWhchThOprtrSlctsThtThP" 0 "OffPsByWhchThOprtrSlctsThtNnOfT" ;
VAL_ 2365443326 WorkLightSwitch 5 "1101Reserved" 4 "WrkLghtCmbntn4OnPsByWhchThOprtr" 2 "WrkLghtCmbntn2OnPsByWhchThOprtr" 15 "NotAvailable" 14 "Error" 3 "WrkLghtCmbntn3OnPsByWhchThOprtr" 1 "WrkLghtCmbntn1OnPsByWhchThOprtr" 0 "OffPsByWhchThOprtrSlctsThtNnOfT" ;
VAL_ 2566802686 BlackOutWorkLampSelect 3 "NotSupported" 2 "Reserved" 1 "On" 0 "Off" ;
VAL_ 2566802686 NightVisionIlluminatorSelect 3 "NotSupported" 2 "Reserved" 1 "On" 0 "Off" ;
VAL_ 2566802686 BlackOutBrake_StopLampSelect 3 "NotSupported" 2 "Reserved" 1 "On" 0 "Off" ;
VAL_ 2566802686 ConvoyDrivingLampSelect 3 "NotSupported" 2 "Reserved" 1 "On" 0 "Off" ;
VAL_ 2566802686 ConvoyLampSelect 3 "NotSupported" 2 "Reserved" 1 "On" 0 "Off" ;
VAL_ 2566802686 FrontBlackOutMarkerLampSelect 3 "NotSupported" 2 "Reserved" 1 "On" 0 "Off" ;
VAL_ 2566802686 RearBlackOutMarkerSelect 3 "NotSupported" 2 "Reserved" 1 "On" 0 "Off" ;
VAL_ 2566774014 SlowVesselModeStatus 3 "TakeNoAction" 2 "Reserved" 1 "SlowVesselModeIsACTIVE" 0 "SlowVesselModeIsOFF" ;
VAL_ 2566774014 TrollingModeStatus 3 "TakeNoAction" 2 "Reserved" 1 "TrollingModeIsACTIVE" 0 "TrollingModeIsOFF" ;
VAL_ 2566774014 EngThrttlSynchrnztionModeStatus 15 "TakeNoAction" 5 "1110Reserved" 4 "SynchronizedMaster" 3 "SynchronizedStarboard" 2 "SynchronizedPort" 1 "SynchronizedCenter" 0 "NotSynchronized" ;
VAL_ 2432595710 DisplayDeadbands 15 "NotAvailable" 3 "1110Reserved" 2 "Wide_24mm" 1 "Standard_12mm" 0 "Narrow_45mm" ;
VAL_ 2432595710 LEDPatternCtrl 15 "NotAvailable" 3 "1110Reserved" 2 "7Channel" 1 "Offset" 0 "5Channel" ;
VAL_ 2432595710 LEDDisplayDeadbandCtrl 15 "NotAvailableNotApplicable" 5 "1110Reserved" 4 "_1Mm" 3 "_5Mm" 2 "_24Mm" 1 "_12Mm" 0 "_45Mm" ;
VAL_ 2432595710 LEDDisplayModeCtrl 15 "NotAvailableNotApplicable" 3 "1110Reserved" 2 "CenterOnGradeDisplayMode2" 1 "OffsetOnGradeDisplayMode" 0 "CenterOnGradeDisplayMode1" ;
VAL_ 2432595710 LEDDisplayData1 511 "NotAvailable" 254 "Error" 159 "NoData" 149 "HighCoarse" 148 "HighMedium_Coarse" 147 "HighMedium" 146 "HighMedium_Fine" 145 "HighFine" 144 "OnGrade" 132 "LowFine" 131 "LowMedium_Fine" 130 "LowMedium" 129 "LowMedium_Coarse" 128 "LowCoarse" 32 "LowCoarseLEDOn" 16 "LowFineLEDOn" 8 "OngradeLEDOn" 4 "HighFineLEDOn" 2 "HighCoarseLEDOn" ;
VAL_ 2365486590 LaserReceiverType 1 "LinearLaserReceiver" 0 "Reserved" ;
VAL_ 2365485566 LaserTracerInformation 32 "Curb" 16 "Stringline" 8 "PreviousPass" 4 "ValidTarget" 2 "LaserIsReady" 1 "LaserPowerIsOn" ;
VAL_ 2365485566 LEDDisplayData2 511 "NotAvailable" 254 "Error" 159 "NoData" 149 "HighCoarse" 148 "HighMedium_Coarse" 147 "HighMedium" 146 "HighMedium_Fine" 145 "HighFine" 144 "OnGrade" 132 "LowFine" 131 "LowMedium_Fine" 130 "LowMedium" 129 "LowMedium_Coarse" 128 "LowCoarse" 64 "RightLEDOn" 32 "LeftLEDOn" 16 "DownLEDOn" 8 "UpLEDOn" 4 "OngradeCLEDOn" 2 "OngradeBLEDOn" 1 "OngradeALEDOn" ;
VAL_ 2364542462 SdshftDsrdBldOffsetOperatorCtrl 15 "NotInstalled" 14 "ErrorIndicator" 4 "1101Reserved" 3 "AutomaticOperatorCtrlRq" 2 "ManualOperatorCtrlRq" 0 "NoOperatorCtrlRq" 1 "MomentaryOperatorCtrlRq" ;
VAL_ 2364542462 SdshftBldCtrlMdeOperatorControl 15 "NotInstalled" 14 "ErrorIndicator" 3 "1101Reserved" 2 "DecrementOperatorCtrlRq" 0 "NoOperatorCtrlRq" 1 "IncrementOperatorCtrlRq" ;
VAL_ 2364542462 RghtDsrdBladeOffsetOperatorCtrl 15 "NotInstalled" 14 "ErrorIndicator" 3 "1101Reserved" 2 "DecrementOperatorCtrlRq" 0 "NoOperatorCtrlRq" 1 "OprtrCtrlSttCnBRdInTwWysOnMthdU" ;
VAL_ 2364542462 RghtBldeCtrlModeOperatorControl 15 "NotInstalled" 14 "ErrorIndicator" 3 "AutomaticOperatorCtrlRq" 2 "ManualOperatorCtrlRq" 0 "NoChange" 1 "MomentaryOperatorCtrlRq" ;
VAL_ 2364542462 LftDsredBladeOffsetOperatorCtrl 15 "NotInstalled" 14 "ErrorIndicator" 3 "1101Reserved" 2 "DecrementOperatorCtrlRq" 0 "NoOperatorCtrlRq" 1 "OprtrCtrlSttCnBRdInTwWysOnMthdU" ;
VAL_ 2364542462 LftBladeCtrlModeOperatorControl 15 "NotInstalled" 14 "ErrorIndicator" 12 "1101Reserved" 3 "AutomaticOperatorCtrlRq" 2 "ManualOperatorCtrlRq" 0 "NoChange" 1 "OprtrCtrlSttCnBRdInTwWysOnMthdU" ;
VAL_ 2364542462 BladeAutoModeCmd 15 "NotSupported" 14 "ErrorIndicator" 4 "AutoNotAllowed" 3 "SrvcMdAtAllwdOnlyDrngSrvceModes" 2 "SspndAtTmprarilySuspendAutoMode" 1 "ActvtyAllwsAtMstDtctOprtrBfrAtA" 0 "AutoAllowed" ;
VAL_ 2364542462 DesiredGradeOffsetSwitch 15 "NotInstalled" 14 "ErrorIndicator" 2 "DecrementButtonPressed" 0 "NoButtonPressed" 1 "SwtchSttCnBRdInTwWysOnMthdUssTh" ;
VAL_ 2364542462 BladeCtrlModeSwitch 15 "NotInstalled" 14 "ErrorIndicator" 3 "AutomaticButtonPressed" 2 "ManualButtonPressed" 0 "NoButtonPressed" 1 "SwtchSttCnBRdInTwWysOnMthdUssTh" ;
VAL_ 2364542462 StElvtnSnsor2ReferenceElevation 3 "DontCare_TakeNoAction" 2 "Reserved" 1 "SetReferenceElevation" 0 "DoNotSetReferenceElevation" ;
VAL_ 2364542462 StElvtnSnsor1ReferenceElevation 3 "DontCare_TakeNoAction" 2 "Reserved" 1 "SetReferenceElevation" 0 "DoNotSetReferenceElevation" ;
VAL_ 2633937918 FlexibleFuelPercentage 4 "MansAlcoholAsFuelAndNothingElse" ;
VAL_ 2633883646 FrontWheelDriveActuatorStatus 3 "NotAvailable" 2 "Error" 1 "FrontWheelDriveActuatorEngaged" 0 "FrntWhelDriveActuatorNotEngaged" ;
VAL_ 2633880062 FMSstandardRqsSupported 3 "DontCare" 2 "Reserved" 1 "OnRqModeIsSupported" 0 "OnRqModeIsNotSupported" ;
VAL_ 2633880062 FMSstandardDiagnosticsSupported 3 "DontCare" 2 "Reserved" 1 "DiagnosticsIsSupported" 0 "DiagnosticsIsNotSupported" ;
VAL_ 2566806526 LnDprtureIndicationEnableStatus 3 "NotUsed" 2 "Reserved" 1 "LaneDepartureIndicationEnabled" 0 "LaneDepartureIndicationDisabled" ;
VAL_ 2566806526 LaneTrackingStatusLeftSide 3 "DontCare_TakeNoAction" 2 "Reserved" 1 "TrackingLeftSide" 0 "NotTrackingLeftSide" ;
VAL_ 2566806526 LaneTrackingStatusRightSide 3 "DontCare_TakeNoAction" 2 "Reserved" 1 "TrackingRightSide" 0 "NotTrackingRightSide" ;
VAL_ 2431649790 LaneDepartureImminentLeftSide 3 "NotUsed" 2 "Reserved" 1 "Imminent" 0 "NotImminent" ;
VAL_ 2431649790 LaneDepartureImminentRightSide 3 "NotUsed" 2 "Reserved" 1 "Imminent" 0 "NotImminent" ;
VAL_ 2431649790 LaneDepartureRight 3 "TakeNoAction" 2 "Reserved" 1 "MddlOfVhclDprtsThLnTThRightSide" 0 "MddlOfVhclDsNtDprtThLnTThRghtSd" ;
VAL_ 2431649790 LaneDepartureLeft 3 "TakeNoAction" 2 "Reserved" 1 "MddlOfVhclDprtsThLnTTheLeftSide" 0 "MddlOfVhclDsNtDprtThLnTThLftSde" ;
VAL_ 2633929214 EngFuelLeakage2 3 "NotAvailable" 2 "Error" 1 "LeakageDetected" 0 "NoLeakageDetected" ;
VAL_ 2633929214 EngFuelLeakage1 3 "NotAvailable" 2 "Error" 1 "LeakageDetected" 0 "NoLeakageDetected" ;
VAL_ 2566831614 FanDriveState 15 "NotAvailable" 14 "Other" 13 "EngBrake" 12 "Timer" 11 "A_CSystem" 10 "TransRetarder" 9 "ManualCtrl" 8 "ReverseOperation" 7 "DefaultOperation" 6 "ExcessiveHydOilTemp" 5 "ExcessiveTransOilTemp" 4 "ExcessiveEngCoolantTemp" 3 "ExcessiveEngOilTemp" 2 "ExcessiveEngAirTemp" 1 "EngSystemGeneral" 0 "FanOff" ;
VAL_ 2566820094 EngTorqueLimitFeature 7 "NotAvailable" 5 "110Reserved" 4 "CurrentTorqueRating" 3 "PreviousTorqueRating" 2 "FirstTorqueRating" 1 "HighestTorqueRating" 0 "Reserved" ;
VAL_ 2566820094 TorqueLimitingFeatureStatus 3 "NotAvailable" 2 "Error" 1 "Enabled" 0 "Disabled" ;
VAL_ 2364542206 TransTorqueConverterRatio 64256 "RatioCannotBeProperlyDetermined" ;
VAL_ 2566802174 TrnsRvrseGearShiftInhibitStatus 3 "NotAvailable" 2 "Error" 1 "RvrsGrShftsArCurrentlyInhibited" 0 "RvrsGrShiftsAreCurrentlyAllowed" ;
VAL_ 2566802174 TrnsCrrntRangeDisplayBlankState 3 "NotSupported" 2 "Error" 1 "Blanked" 0 "NotBlanked" ;
VAL_ 2566802174 TransWarningIndicator 3 "NotAvailable" 2 "TransWarningIndicatorIsFlashing" 1 "TrnsWrnngIndctrIsOnContinuously" 0 "TransWarningIndicatorIsOff" ;
VAL_ 2566802174 TransMode8Indicator 3 "TakeNoAction" 2 "Reserved" 1 "Enable" 0 "Disable" ;
VAL_ 2566802174 TransMode7Indicator 3 "TakeNoAction" 2 "Reserved" 1 "Enable" 0 "Disable" ;
VAL_ 2566802174 TransMode6Indicator 3 "TakeNoAction" 2 "Reserved" 1 "Enable" 0 "Disable" ;
VAL_ 2566802174 TransMode5Indicator 3 "TakeNoAction" 2 "Reserved" 1 "Enable" 0 "Disable" ;
VAL_ 2566802174 TransMode1Indicator 3 "NotAvailable" 2 "Error" 1 "TransMode1Active" 0 "TransMode1NotActive" ;
VAL_ 2566802174 TransMode2Indicator 3 "NotAvailable" 2 "Error" 1 "TransMode2Active" 0 "TransMode2NotActive" ;
VAL_ 2566802174 TransMode3Indicator 3 "NotAvailable" 2 "Error" 1 "TransMode3Active" 0 "TransMode3NotActive" ;
VAL_ 2566802174 TransMode4Indicator 3 "NotAvailable" 2 "Error" 1 "TransMode4Active" 0 "TransMode4NotActive" ;
VAL_ 2566802174 TransShiftInhibitIndicator 3 "TakeNoAction" 2 "Reserved" 1 "ActiveShiftIsInhibited" 0 "InactiveShiftIsNotInhibited" ;
VAL_ 2566802174 TransEngCrankEnable 3 "NotAvailable" 2 "Error" 1 "CrnkngEnbldEngCrnkngIsAllwdByTr" 0 "CrnkngDsbldEngCrnkngIsPrhbtdByT" ;
VAL_ 2566802174 ActiveShiftConsoleIndicator 3 "NotAvailable" 2 "Reserved" 1 "SecondShiftConsoleIsActive" 0 "PrimaryShiftConsoleIsActive" ;
VAL_ 2566802174 TransReadyForBrakeRelease 3 "NotAvailable" 2 "Error" 1 "TransReadyForBrakeRelease" 0 "TransNotReadyForBrakeRelease" ;
VAL_ 2566802174 TransRqedRangeDisplayFlashState 3 "TakeNoAction" 2 "Reserved" 1 "ActvTrnsRqdRngDsplyShldBFlshing" 0 "InctvTrnsRqdRngDsplyShldNtBFlsh" ;
VAL_ 2566802174 TransRqedRangeDisplayBlankState 3 "TakeNoAction" 2 "Reserved" 1 "ActvTrnsRqdRngDsplyShldBBlanked" 0 "InctvTrnsRqdRngDsplyShldNtBBlnk" ;
VAL_ 2566802174 TransServiceIndicator 3 "NotAvailable" 2 "ServiceIndicatorFlashing" 1 "ServiceIndicatorOn" 0 "SeviceIndicatorOff" ;
VAL_ 2633935870 LowestPossibleGear 251 "Park" ;
VAL_ 2633935870 HighestPossibleGear 251 "Park" ;
VAL_ 2633935870 RecommendedGear 251 "Park" ;
VAL_ 2633942014 TransForwardDirectionSwitch 3 "NotAvailable" 2 "Error" 1 "On" 0 "Off" ;
VAL_ 2633942014 TransNeutralSwitch 3 "NotAvailable" 2 "Error" 1 "On" 0 "Off" ;
VAL_ 2633942014 TransReverseDirectionSwitch 3 "NotAvailable" 2 "Error" 1 "On" 0 "Off" ;
VAL_ 2633942014 TransLowRangeSenseSwitch 3 "NotAvailable" 2 "Error" 1 "On" 0 "Off" ;
VAL_ 2633942014 TransHighRangeSenseSwitch 3 "NotAvailable" 2 "Error" 1 "On" 0 "Off" ;
VAL_ 2633943038 TransInertiaBrakeActuator 3 "NotAvailable" 2 "Error" 1 "On" 0 "Off" ;
VAL_ 2633943038 TransDefuelActuator 3 "NotAvailable" 2 "Error" 1 "On" 0 "Off" ;
VAL_ 2633943038 TransLockupClutchActuator 3 "NotAvailable" 2 "Error" 1 "On" 0 "Off" ;
VAL_ 2633943038 TransClutchActuator 3 "NotAvailable" 2 "Error" 1 "On" 0 "Off" ;
VAL_ 2633943038 TransSplitterIndirectActuator 3 "NotAvailable" 2 "Error" 1 "On" 0 "Off" ;
VAL_ 2633943038 TransSplitterDirectActuator 3 "NotAvailable" 2 "Error" 1 "On" 0 "Off" ;
VAL_ 2633943038 TransRangeLowActuator 3 "NotAvailable" 2 "Error" 1 "On" 0 "Off" ;
VAL_ 2633943038 TransRangeHighActuator 3 "NotAvailable" 2 "Error" 1 "On" 0 "Off" ;
VAL_ 2633943038 TransShiftFingerGearActuator2 3 "NotAvailable" 2 "Error" 1 "On" 0 "Off" ;
VAL_ 2633943038 TransShiftFingerRailActuator2 3 "NotAvailable" 2 "Error" 1 "On" 0 "Off" ;
VAL_ 2633943038 TransShiftFingerGearActuator1 3 "NotAvailable" 2 "Error" 1 "On" 0 "Off" ;
VAL_ 2633943038 TransShiftFingerRailActuator1 3 "NotAvailable" 2 "Error" 1 "On" 0 "Off" ;
VAL_ 2633943038 TrnsShftFngrCenterRailIndicator 3 "NotAvailable" 2 "Error" 1 "On" 0 "Off" ;
VAL_ 2633943038 TrnsShftFngrEngagementIndicator 3 "NotAvailable" 2 "Error" 1 "On" 0 "Off" ;
VAL_ 2633943038 TrnsShiftFingerNeutralIndicator 3 "NotAvailable" 2 "Error" 1 "On" 0 "Off" ;
VAL_ 2565867006 TransCurrentGear 251 "Park" ;
VAL_ 2565867006 TransSelectedGear 251 "Park" ;
VAL_ 2565866755 TransCurrentGear 251 "Park" ;
VAL_ 2565866755 TransSelectedGear 251 "Park" ;
VAL_ 2364539646 TrnsTrqueConverterLockupEngaged 3 "NotAvailable" 2 "Error" 1 "TorqueConverterLockupEngaged" 0 "TorqueConverterLockupDisengaged" ;
VAL_ 2364539646 TrnsTrqCnvrtrLckpTrnstnInPrcess 3 "NotAvailable" 2 "Error" 1 "TransitionIsInProcess" 0 "TransitionIsNotInProcess" ;
VAL_ 2364539646 MomentaryEngMaxPowerEnable 3 "notAvailable" 2 "fault" 1 "mmntarilyRqingMaxPowerAvailable" 0 "notRqingMaxPowerAvailable" ;
VAL_ 2364539646 ProgressiveShiftDisable 2 "Reserved" 3 "TakeNoAction" 1 "ProgressiveShiftIsDisabled" 0 "ProgressiveShiftIsNotDisabled" ;
VAL_ 2364539646 EngMomentaryOverspeedEnable 3 "TakeNoAction" 2 "Reserved" 1 "MomentaryEngOverspeedIsEnabled" 0 "MomentaryEngOverspeedIsDisabled" ;
VAL_ 2364539646 TransShiftInProcess 3 "NotAvailable" 2 "Error" 1 "ShiftInProcess" 0 "ShiftIsNotInProcess" ;
VAL_ 2364539646 TransDrivelineEngaged 3 "NotAvailable" 2 "Error" 1 "DrivelineEngaged" 0 "DrivelineDisengaged" ;
VAL_ 2364539395 TrnsTrqueConverterLockupEngaged 3 "NotAvailable" 2 "Error" 1 "TorqueConverterLockupEngaged" 0 "TorqueConverterLockupDisengaged" ;
VAL_ 2364539395 TrnsTrqCnvrtrLckpTrnstnInPrcess 3 "NotAvailable" 2 "Error" 1 "TransitionIsInProcess" 0 "TransitionIsNotInProcess" ;
VAL_ 2364539395 MomentaryEngMaxPowerEnable 3 "notAvailable" 2 "fault" 1 "mmntarilyRqingMaxPowerAvailable" 0 "notRqingMaxPowerAvailable" ;
VAL_ 2364539395 ProgressiveShiftDisable 2 "Reserved" 3 "TakeNoAction" 1 "ProgressiveShiftIsDisabled" 0 "ProgressiveShiftIsNotDisabled" ;
VAL_ 2364539395 EngMomentaryOverspeedEnable 3 "TakeNoAction" 2 "Reserved" 1 "MomentaryEngOverspeedIsEnabled" 0 "MomentaryEngOverspeedIsDisabled" ;
VAL_ 2364539395 TransShiftInProcess 3 "NotAvailable" 2 "Error" 1 "ShiftInProcess" 0 "ShiftIsNotInProcess" ;
VAL_ 2364539395 TransDrivelineEngaged 3 "NotAvailable" 2 "Error" 1 "DrivelineEngaged" 0 "DrivelineDisengaged" ;
VAL_ 2565868542 SterableLiftAxleLoweringInhibit 3 "NotAvailable" 2 "Reserved" 1 "LoweringInhibited" 0 "LoweringAllowed" ;
VAL_ 2565868542 TypeOfSteerTrans 15 "NotAvailable" 4 "1110ReservedForSAEAssignment" 3 "HybrdStrTrnsAStrngTrnsmssnInWhc" 2 "PrlyElctrcStrTrnsAStrngTrnsmssn" 1 "PrlyHydStrTrnsAStrngTrnsmssnInW" 0 "PrlyMchStrTrnsAStrngTrnsmssnInW" ;
VAL_ 2565868542 TypeOfSteerForces 15 "NotAvailable" 4 "1110ReservedForSAEAssignment" 3 "SlfTrckngStrEqpmntASystmDsgndTC" 2 "FllPwrStrEqpmntStrngFrcsArPrvdd" 1 "PwrAssstdStrEqpmntStrngFrcsRslt" 0 "MnlStrEqpmntStrngFrcsRsltSllyFr" ;
VAL_ 2565868542 SteerType 15 "NotAvailable" 2 "1110ReservedForAssignmentBySAE" 1 "AxStrEqpmntASystmInWhchWhlsOnAx" 0 "MnStrSystmStrngEqpmntOfAVhclWhc" ;
VAL_ 2565868542 StatusOfSteerAxle 15 "NotAvailable" 6 "1110ReservedForSAEAssignment" 5 "AxleSteerInSpecialMode" 4 "AxleNotActiveBecauseOfAnError" 3 "AxleCenteredBecauseOfAnError" 2 "AxleCentered" 1 "AxleSteerActive" 0 "AxleSteerNotActive" ;
VAL_ 2633941758 TransOutputRetarder 3 "NotAvailable" 2 "Error" 1 "On" 0 "Off" ;
VAL_ 2565865726 RetarderRoadSpeedLimitSwitch 3 "NotAvailable" 2 "ErrorIndicator" 1 "RdSpdLmtngByRtrdrIsEnbldRdSpdTh" 0 "RdSpdLmtingByRetarderIsDisabled" ;
VAL_ 2565865726 RetarderRoadSpeedExceededStatus 3 "DontCare_TakeNoAction" 2 "Reserved" 1 "RdSpdIsAbvThrshldAndRtrdrIsAllw" 0 "RoadSpeedIsBelowThreshold" ;
VAL_ 2565865726 RetarderRqingBrakeLight 3 "NotAvailable_TakeNoAction" 2 "Reserved" 1 "RtrdrIsRqngThtBrkLghtsArIllmntd" 0 "RtrdrIsNtRqngThtBrkLghtsArIllmn" ;
VAL_ 2565865726 EngCoolantLoadIncrease 3 "NotAvailable" 2 "Error" 1 "CoolantLoadIncreasePossible" 0 "NoCoolantLoadIncrease" ;
VAL_ 2565865726 RetarderEnableShiftAssistSwitch 3 "NotAvailable" 2 "Error" 1 "RetarderShiftAssistEnabled" 0 "RetarderShiftAssistDisabled" ;
VAL_ 2565865726 RetarderEnableBrakeAssistSwitch 3 "NotAvailable" 2 "Error" 1 "RetarderBrakeAssistEnabled" 0 "RetarderBrakeAssistDisabled" ;
VAL_ 2565865487 RetarderRoadSpeedLimitSwitch 3 "NotAvailable" 2 "ErrorIndicator" 1 "RdSpdLmtngByRtrdrIsEnbldRdSpdTh" 0 "RdSpdLmtingByRetarderIsDisabled" ;
VAL_ 2565865487 RetarderRoadSpeedExceededStatus 3 "DontCare_TakeNoAction" 2 "Reserved" 1 "RdSpdIsAbvThrshldAndRtrdrIsAllw" 0 "RoadSpeedIsBelowThreshold" ;
VAL_ 2565865487 RetarderRqingBrakeLight 3 "NotAvailable_TakeNoAction" 2 "Reserved" 1 "RtrdrIsRqngThtBrkLghtsArIllmntd" 0 "RtrdrIsNtRqngThtBrkLghtsArIllmn" ;
VAL_ 2565865487 EngCoolantLoadIncrease 3 "NotAvailable" 2 "Error" 1 "CoolantLoadIncreasePossible" 0 "NoCoolantLoadIncrease" ;
VAL_ 2565865487 RetarderEnableShiftAssistSwitch 3 "NotAvailable" 2 "Error" 1 "RetarderShiftAssistEnabled" 0 "RetarderShiftAssistDisabled" ;
VAL_ 2565865487 RetarderEnableBrakeAssistSwitch 3 "NotAvailable" 2 "Error" 1 "RetarderBrakeAssistEnabled" 0 "RetarderBrakeAssistDisabled" ;
VAL_ 2565865488 RetarderRoadSpeedLimitSwitch 3 "NotAvailable" 2 "ErrorIndicator" 1 "RdSpdLmtngByRtrdrIsEnbldRdSpdTh" 0 "RdSpdLmtingByRetarderIsDisabled" ;
VAL_ 2565865488 RetarderRoadSpeedExceededStatus 3 "DontCare_TakeNoAction" 2 "Reserved" 1 "RdSpdIsAbvThrshldAndRtrdrIsAllw" 0 "RoadSpeedIsBelowThreshold" ;
VAL_ 2565865488 RetarderRqingBrakeLight 3 "NotAvailable_TakeNoAction" 2 "Reserved" 1 "RtrdrIsRqngThtBrkLghtsArIllmntd" 0 "RtrdrIsNtRqngThtBrkLghtsArIllmn" ;
VAL_ 2565865488 EngCoolantLoadIncrease 3 "NotAvailable" 2 "Error" 1 "CoolantLoadIncreasePossible" 0 "NoCoolantLoadIncrease" ;
VAL_ 2565865488 RetarderEnableShiftAssistSwitch 3 "NotAvailable" 2 "Error" 1 "RetarderShiftAssistEnabled" 0 "RetarderShiftAssistDisabled" ;
VAL_ 2565865488 RetarderEnableBrakeAssistSwitch 3 "NotAvailable" 2 "Error" 1 "RetarderBrakeAssistEnabled" 0 "RetarderBrakeAssistDisabled" ;
VAL_ 2633935358 EngExhstGsOxygnSnsrClsdLpOprton 3 "DontCare_TakeNoAction" 2 "Reserved" 1 "EngUsngExhstGsOxygnSnsrFrAClsdL" 0 "EngNtUsngExhaustGasOxygenSensor" ;
